VERSION ""

NS_ :

BS_:

BU_: VMCU TECU OBDScanT2 IC3 EMS ECUspare2 ECUspare1 DACU CIOM BBM

BO_ 1443 IC3_BB2_06S: 21 IC3
 SG_ SaveTrlrName_rqst_Request : 160|2@1+ (1,0) [0|0] ""  VMCU
 SG_ SaveTrlrName_rqst_sg_UB : 165|1@1+ (1,0) [0|0] ""  VMCU
 SG_ SaveTrlrName_rqst_NewName : 0|160@1+ (1,0) [0|0] ""  VMCU
 SG_ SaveTrlrName_rqst_Position : 162|3@1+ (1,0) [0|0] ""  VMCU

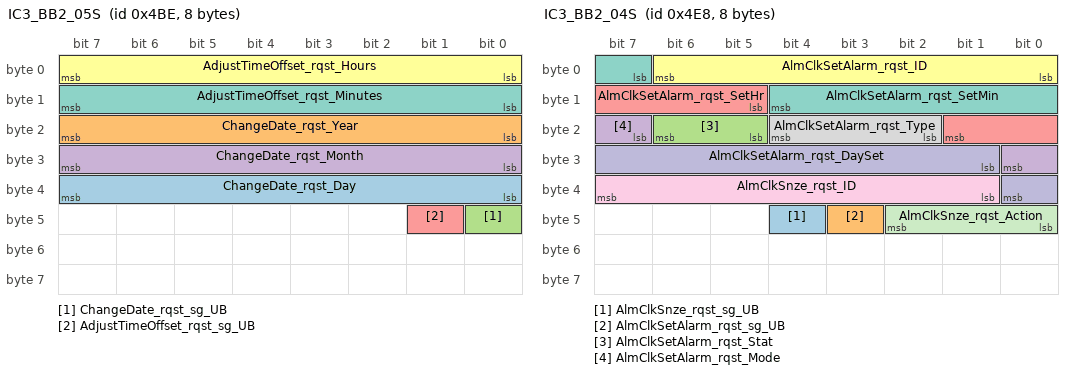
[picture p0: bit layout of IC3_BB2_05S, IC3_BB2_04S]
BO_ 1214 IC3_BB2_05S: 8 IC3
 SG_ ChangeDate_rqst_Day : 32|8@1+ (1,0) [0|255] "Days"  VMCU
 SG_ ChangeDate_rqst_Year : 16|8@1+ (1,1985) [1985|2240] "Years"  VMCU
 SG_ ChangeDate_rqst_sg_UB : 40|1@1+ (1,0) [0|0] ""  VMCU
 SG_ ChangeDate_rqst_Month : 24|8@1+ (1,0) [0|255] "Months"  VMCU
 SG_ AdjustTimeOffset_rqst_sg_UB : 41|1@1+ (1,0) [0|0] ""  VMCU
 SG_ AdjustTimeOffset_rqst_Hours : 0|8@1+ (1,0) [0|255] "h"  VMCU
 SG_ AdjustTimeOffset_rqst_Minutes : 8|8@1+ (1,0) [0|255] "min"  VMCU

BO_ 1256 IC3_BB2_04S: 8 IC3
 SG_ AlmClkSnze_rqst_sg_UB : 44|1@1+ (1,0) [0|0] ""  VMCU
 SG_ AlmClkSetAlarm_rqst_sg_UB : 43|1@1+ (1,0) [0|0] ""  VMCU
 SG_ AlmClkSetAlarm_rqst_Stat : 21|2@1+ (1,0) [0|0] ""  VMCU
 SG_ AlmClkSetAlarm_rqst_Mode : 23|2@1+ (1,0) [0|0] ""  VMCU
 SG_ AlmClkSetAlarm_rqst_SetHr : 13|5@1+ (1,0) [0|31] "h"  VMCU
 SG_ AlmClkSetAlarm_rqst_ID : 0|7@1+ (1,0) [0|0] ""  VMCU
 SG_ AlmClkSetAlarm_rqst_SetMin : 7|6@1+ (1,0) [0|63] "min"  VMCU
 SG_ AlmClkSetAlarm_rqst_Type : 18|3@1+ (1,0) [0|0] ""  VMCU
 SG_ AlmClkSnze_rqst_ID : 33|7@1+ (1,0) [0|0] ""  VMCU
 SG_ AlmClkSetAlarm_rqst_DaySet : 25|8@1+ (1,0) [0|255] ""  VMCU
 SG_ AlmClkSnze_rqst_Action : 40|3@1+ (1,0) [0|0] ""  VMCU

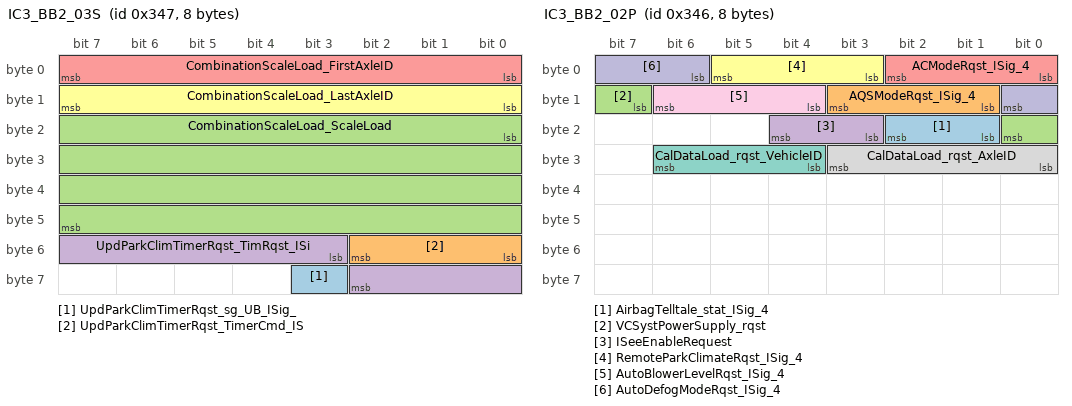
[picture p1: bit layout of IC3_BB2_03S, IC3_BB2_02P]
BO_ 839 IC3_BB2_03S: 8 IC3
 SG_ UpdParkClimTimerRqst_sg_UB_ISig_ : 59|1@1+ (1,0) [0|0] ""  CIOM
 SG_ UpdParkClimTimerRqst_TimerCmd_IS : 48|3@1+ (1,0) [0|0] ""  CIOM
 SG_ CombinationScaleLoad_ScaleLoad : 16|32@1+ (1,0) [0|4294967295] "kg"  VMCU
 SG_ UpdParkClimTimerRqst_TimRqst_ISi : 51|8@1+ (1,0) [0|0] ""  CIOM
 SG_ CombinationScaleLoad_FirstAxleID : 0|8@1+ (1,0) [0|255] "NotApplicable"  VMCU
 SG_ CombinationScaleLoad_LastAxleID : 8|8@1+ (1,0) [0|255] "NotApplicable"  VMCU

BO_ 838 IC3_BB2_02P: 8 IC3
 SG_ AirbagTelltale_stat_ISig_4 : 17|2@1+ (1,0) [0|0] ""  CIOM
 SG_ AQSModeRqst_ISig_4 : 9|3@1+ (1,0) [0|0] ""  CIOM
 SG_ VCSystPowerSupply_rqst : 15|2@1+ (1,0) [0|0] ""  VMCU
 SG_ ISeeEnableRequest : 19|2@1+ (1,0) [0|0] ""  TECU
 SG_ ACModeRqst_ISig_4 : 0|3@1+ (1,0) [0|0] ""  CIOM
 SG_ RemoteParkClimateRqst_ISig_4 : 3|3@1+ (1,0) [0|0] ""  CIOM
 SG_ CalDataLoad_rqst_VehicleID : 28|3@1+ (1,0) [0|0] ""  VMCU
 SG_ CalDataLoad_rqst_AxleID : 24|4@1+ (1,0) [0|0] ""  VMCU
 SG_ AutoBlowerLevelRqst_ISig_4 : 12|3@1+ (1,0) [0|0] ""  CIOM
 SG_ AutoDefogModeRqst_ISig_4 : 6|3@1+ (1,0) [0|0] ""  CIOM

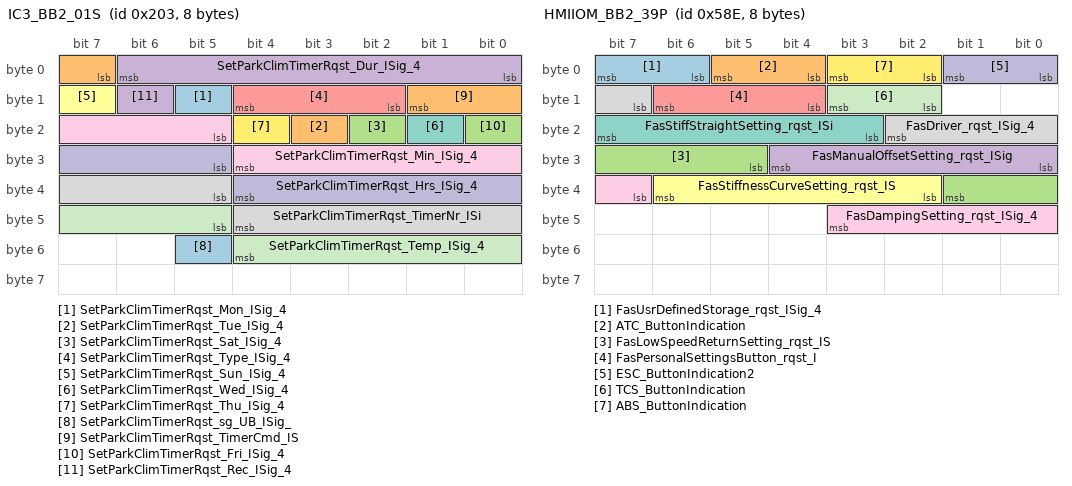
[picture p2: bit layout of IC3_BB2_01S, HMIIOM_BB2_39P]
BO_ 515 IC3_BB2_01S: 8 IC3
 SG_ SetParkClimTimerRqst_Mon_ISig_4 : 13|1@1+ (1,0) [0|0] ""  CIOM
 SG_ SetParkClimTimerRqst_Tue_ISig_4 : 19|1@1+ (1,0) [0|0] ""  CIOM
 SG_ SetParkClimTimerRqst_Sat_ISig_4 : 18|1@1+ (1,0) [0|0] ""  CIOM
 SG_ SetParkClimTimerRqst_Dur_ISig_4 : 0|7@1+ (1,0) [0|127] "min"  CIOM
 SG_ SetParkClimTimerRqst_Type_ISig_4 : 10|3@1+ (1,0) [0|0] ""  CIOM
 SG_ SetParkClimTimerRqst_Sun_ISig_4 : 15|1@1+ (1,0) [0|0] ""  CIOM
 SG_ SetParkClimTimerRqst_Wed_ISig_4 : 17|1@1+ (1,0) [0|0] ""  CIOM
 SG_ SetParkClimTimerRqst_TimerNr_ISi : 37|8@1+ (1,0) [0|0] ""  CIOM
 SG_ SetParkClimTimerRqst_Min_ISig_4 : 21|8@1+ (1,0) [0|255] "min"  CIOM
 SG_ SetParkClimTimerRqst_Hrs_ISig_4 : 29|8@1+ (1,0) [0|255] "h"  CIOM
 SG_ SetParkClimTimerRqst_Temp_ISig_4 : 45|8@1+ (0.5,0) [0|127.5] "DegreeC"  CIOM
 SG_ SetParkClimTimerRqst_Thu_ISig_4 : 20|1@1+ (1,0) [0|0] ""  CIOM
 SG_ SetParkClimTimerRqst_sg_UB_ISig_ : 53|1@1+ (1,0) [0|0] ""  CIOM
 SG_ SetParkClimTimerRqst_TimerCmd_IS : 7|3@1+ (1,0) [0|0] ""  CIOM
 SG_ SetParkClimTimerRqst_Fri_ISig_4 : 16|1@1+ (1,0) [0|0] ""  CIOM
 SG_ SetParkClimTimerRqst_Rec_ISig_4 : 14|1@1+ (1,0) [0|0] ""  CIOM

BO_ 1477 HMIIOM_BB2_S28_FCM: 8 TECU
 SG_ HMIIOM_BB2_S28_FCS : 0|64@1+ (1,0) [0|0] ""  IC3

BO_ 1422 HMIIOM_BB2_39P: 8 IC3
 SG_ FasUsrDefinedStorage_rqst_ISig_4 : 6|2@1+ (1,0) [0|0] ""  VMCU
 SG_ ATC_ButtonIndication : 4|2@1+ (1,0) [0|0] ""  CIOM
 SG_ FasLowSpeedReturnSetting_rqst_IS : 29|5@1+ (1,-10) [-10|21] ""  VMCU
 SG_ FasManualOffsetSetting_rqst_ISig : 24|5@1+ (1,-10) [-10|21] ""  VMCU
 SG_ FasPersonalSettingsButton_rqst_I : 12|3@1+ (1,0) [0|0] ""  VMCU
 SG_ FasStiffnessCurveSetting_rqst_IS : 34|5@1+ (1,-10) [-10|21] ""  VMCU
 SG_ FasStiffStraightSetting_rqst_ISi : 19|5@1+ (1,-10) [-10|21] ""  VMCU
 SG_ FasDriver_rqst_ISig_4 : 15|4@1+ (1,0) [0|0] ""  VMCU
 SG_ FasDampingSetting_rqst_ISig_4 : 39|5@1+ (1,-10) [-10|21] ""  VMCU
 SG_ ESC_ButtonIndication2 : 0|2@1+ (1,0) [0|0] ""  CIOM
 SG_ TCS_ButtonIndication : 10|2@1+ (1,0) [0|0] ""  CIOM
 SG_ ABS_ButtonIndication : 2|2@1+ (1,0) [0|0] ""  CIOM

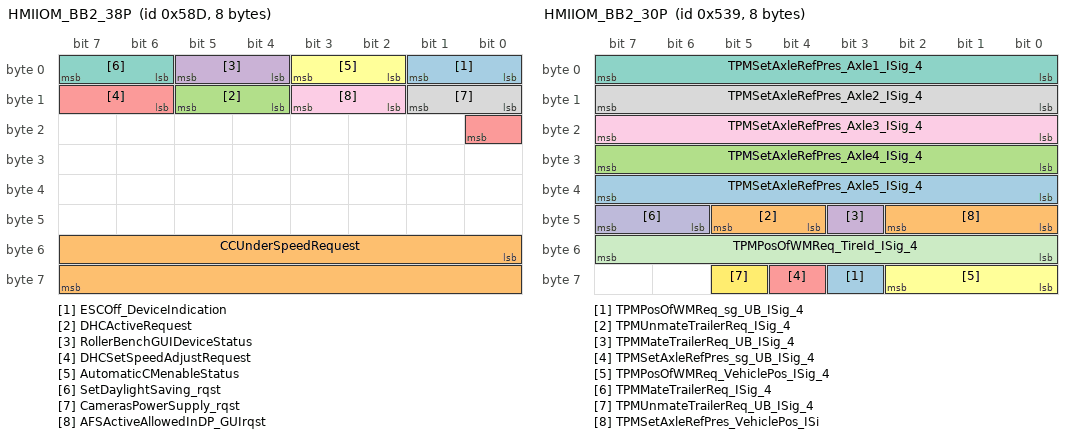
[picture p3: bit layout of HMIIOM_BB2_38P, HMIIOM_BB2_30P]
BO_ 1421 HMIIOM_BB2_38P: 8 IC3
 SG_ ESCOff_DeviceIndication : 0|2@1+ (1,0) [0|0] ""  CIOM
 SG_ CCUnderSpeedRequest : 48|16@1+ (0.00390625,0) [0|255.99609375] "Km_per_h"  VMCU
 SG_ DHCActiveRequest : 12|2@1+ (1,0) [0|0] ""  VMCU
 SG_ RollerBenchGUIDeviceStatus : 4|2@1+ (1,0) [0|0] ""  CIOM
 SG_ DHCSetSpeedAdjustRequest : 14|3@1+ (1,0) [0|0] ""  VMCU
 SG_ AutomaticCMenableStatus : 2|2@1+ (1,0) [0|0] ""  DACU
 SG_ SetDaylightSaving_rqst : 6|2@1+ (1,0) [0|0] ""  VMCU
 SG_ CamerasPowerSupply_rqst : 8|2@1+ (1,0) [0|0] ""  VMCU
 SG_ AFSActiveAllowedInDP_GUIrqst : 10|2@1+ (1,0) [0|0] ""  VMCU

BO_ 518 HMIIOM_BB2_37S: 8 IC3
 SG_ AdasisMapData_ISig_4 : 7|64@0+ (1,0) [0|0] ""  TECU

BO_ 1397 HMIIOM_BB2_36S_FCM: 8 CIOM
 SG_ HMIIOM_BB2_36S_FCS : 0|64@1+ (1,0) [0|0] ""  IC3

BO_ 1396 HMIIOM_BB2_36S: 36 IC3
 SG_ SEM_DisplayText_stat_ISig_4 : 0|288@1+ (1,0) [0|0] ""  CIOM

BO_ 952 HMIIOM_BB2_35S_FCM: 8 CIOM
 SG_ HMIIOM_BB2_35S_FCS : 0|64@1+ (1,0) [0|0] ""  IC3

BO_ 949 HMIIOM_BB2_35S: 98 IC3
 SG_ MediaSourcesListRsp_sg_UB_ISig_4 : 782|1@1+ (1,0) [0|0] ""  CIOM
 SG_ MediaSourcesListRsp_SrcAttrib_IS : 392|384@1+ (1,0) [0|0] ""  CIOM
 SG_ MediaSourcesListRsp_SInfo_ISig_4 : 780|2@1+ (1,0) [0|0] ""  CIOM
 SG_ MediaSourcesListRsp_Name_ISig_4 : 8|384@1+ (1,0) [0|0] ""  CIOM
 SG_ MediaSourcesListRsp_PCI_ISig_4 : 0|8@1+ (1,0) [0|255] ""  CIOM
 SG_ MediaSourcesListRsp_ItemID_ISig_ : 776|4@1+ (1,0) [0|0] ""  CIOM

BO_ 967 HMIIOM_BB2_34S: 8 IC3
 SG_ MediaSourcesListNPRsp_ISig_4 : 0|8@1+ (1,0) [0|255] ""  CIOM
 SG_ MediaSourcesListNPRsp_UB_ISig_4 : 8|1@1+ (1,0) [0|0] ""  CIOM

BO_ 822 HMIIOM_BB2_33P: 8 IC3
 SG_ SEMMediaSourceAvail_Source04_ISi : 4|1@1+ (1,0) [0|0] ""  CIOM
 SG_ SEMMediaSourceAvail_Source10_ISi : 10|1@1+ (1,0) [0|0] ""  CIOM
 SG_ SEMMediaSourceAvail_SInfo_ISig_4 : 14|2@1+ (1,0) [0|0] ""  CIOM
 SG_ SEM_PresetIndicationCmd_ISig_4 : 25|6@1+ (1,0) [0|63] "Enumeration"  CIOM
 SG_ SEMMediaSourceAvail_Source09_ISi : 9|1@1+ (1,0) [0|0] ""  CIOM
 SG_ SEMMediaSourceAvail_Source12_ISi : 12|1@1+ (1,0) [0|0] ""  CIOM
 SG_ SEMMediaSourceAvail_Source07_ISi : 7|1@1+ (1,0) [0|0] ""  CIOM
 SG_ SEMMediaSourceAvail_Source03_ISi : 3|1@1+ (1,0) [0|0] ""  CIOM
 SG_ SEMMediaSourceAvail_Source11_ISi : 11|1@1+ (1,0) [0|0] ""  CIOM
 SG_ SEM_AudioVolValIndCmd_ISig_4 : 19|6@1+ (1,0) [0|63] "Step"  CIOM
 SG_ SEMMediaSourceAvail_Source02_ISi : 2|1@1+ (1,0) [0|0] ""  CIOM
 SG_ AudioSourceStat_ISig_4 : 31|4@1+ (1,0) [0|0] ""  CIOM
 SG_ SEMMediaSourceAvail_Source06_ISi : 6|1@1+ (1,0) [0|0] ""  CIOM
 SG_ SEMMediaSourceAvail_Source00_ISi : 0|1@1+ (1,0) [0|0] ""  CIOM
 SG_ SEMMediaSourceAvail_Source01_ISi : 1|1@1+ (1,0) [0|0] ""  CIOM
 SG_ SEMMediaSourceAvail_Source08_ISi : 8|1@1+ (1,0) [0|0] ""  CIOM
 SG_ SEM_AudioMuteStat_ISig_4 : 16|3@1+ (1,0) [0|0] ""  CIOM
 SG_ SEMMediaSourceAvail_Source13_ISi : 13|1@1+ (1,0) [0|0] ""  CIOM
 SG_ SEMMediaSourceAvail_Source05_ISi : 5|1@1+ (1,0) [0|0] ""  CIOM

BO_ 1337 HMIIOM_BB2_30P: 8 IC3
 SG_ TPMPosOfWMReq_sg_UB_ISig_4 : 59|1@1+ (1,0) [0|0] ""  VMCU
 SG_ TPMUnmateTrailerReq_ISig_4 : 44|2@1+ (1,0) [0|0] ""  VMCU
 SG_ TPMSetAxleRefPres_Axle4_ISig_4 : 24|8@1+ (10,0) [0|2550] "kPa"  VMCU
 SG_ TPMMateTrailerReq_UB_ISig_4 : 43|1@1+ (1,0) [0|0] ""  VMCU
 SG_ TPMSetAxleRefPres_sg_UB_ISig_4 : 60|1@1+ (1,0) [0|0] ""  VMCU
 SG_ TPMPosOfWMReq_VehiclePos_ISig_4 : 56|3@1+ (1,0) [0|0] ""  VMCU
 SG_ TPMSetAxleRefPres_Axle1_ISig_4 : 0|8@1+ (10,0) [0|2550] "kPa"  VMCU
 SG_ TPMSetAxleRefPres_Axle2_ISig_4 : 8|8@1+ (10,0) [0|2550] "kPa"  VMCU
 SG_ TPMSetAxleRefPres_Axle3_ISig_4 : 16|8@1+ (10,0) [0|2550] "kPa"  VMCU
 SG_ TPMMateTrailerReq_ISig_4 : 46|2@1+ (1,0) [0|0] ""  VMCU
 SG_ TPMPosOfWMReq_TireId_ISig_4 : 48|8@1+ (1,0) [0|255] "NotApplicable"  VMCU
 SG_ TPMUnmateTrailerReq_UB_ISig_4 : 61|1@1+ (1,0) [0|0] ""  VMCU
 SG_ TPMSetAxleRefPres_Axle5_ISig_4 : 32|8@1+ (10,0) [0|2550] "kPa"  VMCU
 SG_ TPMSetAxleRefPres_VehiclePos_ISi : 40|3@1+ (1,0) [0|0] ""  VMCU

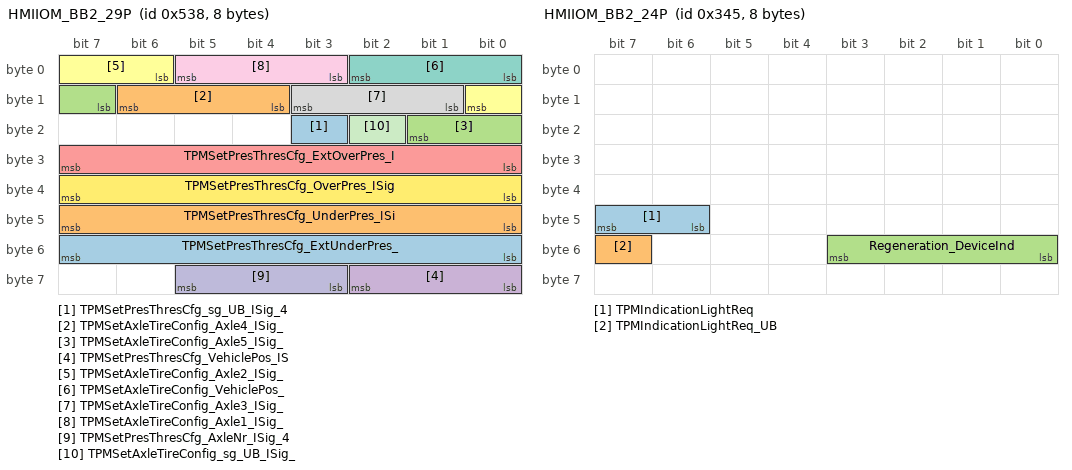
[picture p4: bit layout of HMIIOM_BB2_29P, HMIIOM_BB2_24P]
BO_ 1336 HMIIOM_BB2_29P: 8 IC3
 SG_ TPMSetPresThresCfg_sg_UB_ISig_4 : 19|1@1+ (1,0) [0|0] ""  VMCU
 SG_ TPMSetAxleTireConfig_Axle4_ISig_ : 12|3@1+ (1,0) [0|0] ""  VMCU
 SG_ TPMSetAxleTireConfig_Axle5_ISig_ : 15|3@1+ (1,0) [0|0] ""  VMCU
 SG_ TPMSetPresThresCfg_VehiclePos_IS : 56|3@1+ (1,0) [0|0] ""  VMCU
 SG_ TPMSetPresThresCfg_ExtOverPres_I : 24|8@1+ (1,-125) [-125|130] "Percent"  VMCU
 SG_ TPMSetAxleTireConfig_Axle2_ISig_ : 6|3@1+ (1,0) [0|0] ""  VMCU
 SG_ TPMSetAxleTireConfig_VehiclePos_ : 0|3@1+ (1,0) [0|0] ""  VMCU
 SG_ TPMSetAxleTireConfig_Axle3_ISig_ : 9|3@1+ (1,0) [0|0] ""  VMCU
 SG_ TPMSetAxleTireConfig_Axle1_ISig_ : 3|3@1+ (1,0) [0|0] ""  VMCU
 SG_ TPMSetPresThresCfg_AxleNr_ISig_4 : 59|3@1+ (1,0) [0|0] ""  VMCU
 SG_ TPMSetAxleTireConfig_sg_UB_ISig_ : 18|1@1+ (1,0) [0|0] ""  VMCU
 SG_ TPMSetPresThresCfg_OverPres_ISig : 32|8@1+ (1,-125) [-125|130] "Percent"  VMCU
 SG_ TPMSetPresThresCfg_ExtUnderPres_ : 48|8@1+ (1,-125) [-125|130] "Percent"  VMCU
 SG_ TPMSetPresThresCfg_UnderPres_ISi : 40|8@1+ (1,-125) [-125|130] "Percent"  VMCU

BO_ 1476 HMIIOM_BB2_28S: 284 IC3
 SG_ HillDataPkgTGW_ISig_4 : 0|2272@1+ (1,0) [0|0] ""  TECU

BO_ 1394 HMIIOM_BB2_27S_FCM: 8 CIOM
 SG_ HMIIOM_BB2_27S_FCS : 0|64@1+ (1,0) [0|0] ""  IC3

BO_ 837 HMIIOM_BB2_24P: 8 IC3
 SG_ TPMIndicationLightReq : 46|2@1+ (1,0) [0|0] ""  VMCU
 SG_ TPMIndicationLightReq_UB : 55|1@1+ (1,0) [0|0] ""  VMCU
 SG_ Regeneration_DeviceInd : 48|4@1+ (1,0) [0|0] ""  CIOM

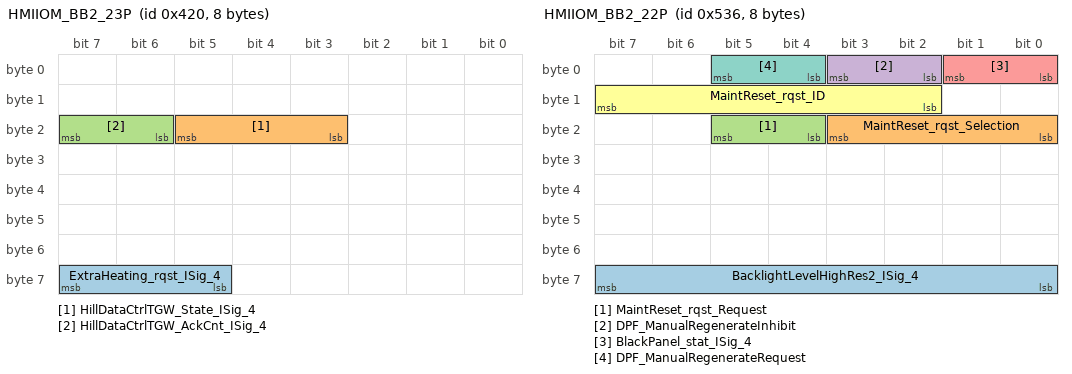
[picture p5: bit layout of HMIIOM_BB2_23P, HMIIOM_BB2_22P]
BO_ 1056 HMIIOM_BB2_23P: 8 IC3
 SG_ ExtraHeating_rqst_ISig_4 : 61|3@1+ (1,0) [0|0] ""  CIOM
 SG_ HillDataCtrlTGW_State_ISig_4 : 19|3@1+ (1,0) [0|0] ""  TECU
 SG_ HillDataCtrlTGW_AckCnt_ISig_4 : 22|2@1+ (1,0) [0|3] ""  TECU

BO_ 1334 HMIIOM_BB2_22P: 8 IC3
 SG_ BacklightLevelHighRes2_ISig_4 : 56|8@1+ (0.4,0) [0|102] "Percent"  CIOM,BBM,VMCU
 SG_ MaintReset_rqst_Selection : 16|4@1+ (1,0) [0|15] "Enumeration"  VMCU
 SG_ MaintReset_rqst_Request : 20|2@1+ (1,0) [0|0] ""  VMCU
 SG_ DPF_ManualRegenerateInhibit : 2|2@1+ (1,0) [0|0] ""  EMS
 SG_ BlackPanel_stat_ISig_4 : 0|2@1+ (1,0) [0|0] ""  VMCU
 SG_ MaintReset_rqst_ID : 10|6@1+ (1,0) [0|63] "Enumeration"  VMCU
 SG_ DPF_ManualRegenerateRequest : 4|2@1+ (1,0) [0|0] ""  EMS

BO_ 1344 HMIIOM_BB2_20S_FCM: 8 CIOM
 SG_ HMIIOM_BB2_20S_FCS : 0|64@1+ (1,0) [0|0] ""  IC3

BO_ 1343 HMIIOM_BB2_20S: 11 IC3
 SG_ ECU3VIN_stat : 0|88@1+ (1,0) [0|0] ""  CIOM

BO_ 1379 HMIIOM_BB2_19P_VMCU_FCM: 8 VMCU
 SG_ HMIIOM_BB2_19P_FCS_563 : 0|64@1+ (1,0) [0|0] ""  IC3

BO_ 1377 HMIIOM_BB2_19P_VMCU: 21 IC3
 SG_ GPSData_Longitude_ISig_4_561 : 0|32@1+ (1E-007,-210) [-210|219.4967295] "deg"  VMCU
 SG_ GPSData_sg_UB_ISig_4_561 : 163|1@1+ (1,0) [0|1] ""  VMCU
 SG_ GPSData_Direction_ISig_4_561 : 96|16@1+ (0.0078125,0) [0|511.9921875] "deg"  VMCU
 SG_ GPSData_Latitude_ISig_4_561 : 32|32@1+ (1E-007,-210) [-210|219.4967295] "deg"  VMCU
 SG_ GPSData_Altitude_ISig_4_561 : 144|16@1+ (0.125,-2500) [-2500|5691.875] "m"  VMCU
 SG_ GPSData_HDOP_ISig_4_561 : 112|16@1+ (0.01,0) [0|655.35] ""  VMCU
 SG_ GPSData_Time_ISig_4_561 : 64|32@1+ (1,0) [0|4294967295] "s"  VMCU
 SG_ GPSData_VehSpeed_ISig_4_561 : 128|16@1+ (0.00390625,0) [0|255.99609375] "Km_per_h"  VMCU
 SG_ GPSData_AntennaStat_ISig_4_561 : 160|3@1+ (1,0) [0|0] ""  VMCU

BO_ 1376 HMIIOM_BB2_19P_TECU_FCM: 8 TECU
 SG_ HMIIOM_BB2_19P_FCS_560 : 0|64@1+ (1,0) [0|0] ""  IC3

BO_ 1375 HMIIOM_BB2_19P_TECU: 21 IC3
 SG_ GPSData_HDOP_ISig_4_55f : 112|16@1+ (0.01,0) [0|655.35] ""  TECU
 SG_ GPSData_VehSpeed_ISig_4_55f : 128|16@1+ (0.00390625,0) [0|255.99609375] "Km_per_h"  TECU
 SG_ GPSData_Direction_ISig_4_55f : 96|16@1+ (0.0078125,0) [0|511.9921875] "deg"  TECU
 SG_ GPSData_Longitude_ISig_4_55f : 0|32@1+ (1E-007,-210) [-210|219.4967295] "deg"  TECU
 SG_ GPSData_sg_UB_ISig_4_55f : 163|1@1+ (1,0) [0|1] ""  TECU
 SG_ GPSData_Time_ISig_4_55f : 64|32@1+ (1,0) [0|4294967295] "s"  TECU
 SG_ GPSData_Latitude_ISig_4_55f : 32|32@1+ (1E-007,-210) [-210|219.4967295] "deg"  TECU
 SG_ GPSData_AntennaStat_ISig_4_55f : 160|3@1+ (1,0) [0|0] ""  TECU
 SG_ GPSData_Altitude_ISig_4_55f : 144|16@1+ (0.125,-2500) [-2500|5691.875] "m"  TECU

BO_ 1382 HMIIOM_BB2_19P_DACU_FCM: 8 DACU
 SG_ HMIIOM_BB2_19P_FCS_566 : 0|64@1+ (1,0) [0|0] ""  IC3

BO_ 1381 HMIIOM_BB2_19P_DACU: 21 IC3
 SG_ GPSData_HDOP_ISig_4_565 : 112|16@1+ (0.01,0) [0|655.35] ""  DACU
 SG_ GPSData_VehSpeed_ISig_4_565 : 128|16@1+ (0.00390625,0) [0|255.99609375] "Km_per_h"  DACU
 SG_ GPSData_sg_UB_ISig_4_565 : 163|1@1+ (1,0) [0|1] ""  DACU
 SG_ GPSData_AntennaStat_ISig_4_565 : 160|3@1+ (1,0) [0|0] ""  DACU
 SG_ GPSData_Latitude_ISig_4_565 : 32|32@1+ (1E-007,-210) [-210|219.4967295] "deg"  DACU
 SG_ GPSData_Time_ISig_4_565 : 64|32@1+ (1,0) [0|4294967295] "s"  DACU
 SG_ GPSData_Direction_ISig_4_565 : 96|16@1+ (0.0078125,0) [0|511.9921875] "deg"  DACU
 SG_ GPSData_Longitude_ISig_4_565 : 0|32@1+ (1E-007,-210) [-210|219.4967295] "deg"  DACU
 SG_ GPSData_Altitude_ISig_4_565 : 144|16@1+ (0.125,-2500) [-2500|5691.875] "m"  DACU

BO_ 1387 HMIIOM_BB2_19P_CIOM_FCM: 8 CIOM
 SG_ HMIIOM_BB2_19P_FCS_56b : 0|64@1+ (1,0) [0|0] ""  IC3

BO_ 1386 HMIIOM_BB2_19P_CIOM: 21 IC3
 SG_ GPSData_HDOP_ISig_4_56a : 112|16@1+ (0.01,0) [0|655.35] ""  CIOM
 SG_ GPSData_Latitude_ISig_4_56a : 32|32@1+ (1E-007,-210) [-210|219.4967295] "deg"  CIOM
 SG_ GPSData_Time_ISig_4_56a : 64|32@1+ (1,0) [0|4294967295] "s"  CIOM
 SG_ GPSData_Direction_ISig_4_56a : 96|16@1+ (0.0078125,0) [0|511.9921875] "deg"  CIOM
 SG_ GPSData_sg_UB_ISig_4_56a : 163|1@1+ (1,0) [0|1] ""  CIOM
 SG_ GPSData_AntennaStat_ISig_4_56a : 160|3@1+ (1,0) [0|0] ""  CIOM
 SG_ GPSData_Longitude_ISig_4_56a : 0|32@1+ (1E-007,-210) [-210|219.4967295] "deg"  CIOM
 SG_ GPSData_VehSpeed_ISig_4_56a : 128|16@1+ (0.00390625,0) [0|255.99609375] "Km_per_h"  CIOM
 SG_ GPSData_Altitude_ISig_4_56a : 144|16@1+ (0.125,-2500) [-2500|5691.875] "m"  CIOM

BO_ 1385 HMIIOM_BB2_19P_BBM_FCM: 8 BBM
 SG_ HMIIOM_BB2_19P_FCS_569 : 0|64@1+ (1,0) [0|0] ""  IC3

BO_ 1384 HMIIOM_BB2_19P_BBM: 21 IC3
 SG_ GPSData_Time_ISig_4_568 : 64|32@1+ (1,0) [0|4294967295] "s"  BBM
 SG_ GPSData_HDOP_ISig_4_568 : 112|16@1+ (0.01,0) [0|655.35] ""  BBM
 SG_ GPSData_Direction_ISig_4_568 : 96|16@1+ (0.0078125,0) [0|511.9921875] "deg"  BBM
 SG_ GPSData_Longitude_ISig_4_568 : 0|32@1+ (1E-007,-210) [-210|219.4967295] "deg"  BBM
 SG_ GPSData_sg_UB_ISig_4_568 : 163|1@1+ (1,0) [0|1] ""  BBM
 SG_ GPSData_VehSpeed_ISig_4_568 : 128|16@1+ (0.00390625,0) [0|255.99609375] "Km_per_h"  BBM
 SG_ GPSData_Altitude_ISig_4_568 : 144|16@1+ (0.125,-2500) [-2500|5691.875] "m"  BBM
 SG_ GPSData_Latitude_ISig_4_568 : 32|32@1+ (1E-007,-210) [-210|219.4967295] "deg"  BBM
 SG_ GPSData_AntennaStat_ISig_4_568 : 160|3@1+ (1,0) [0|0] ""  BBM

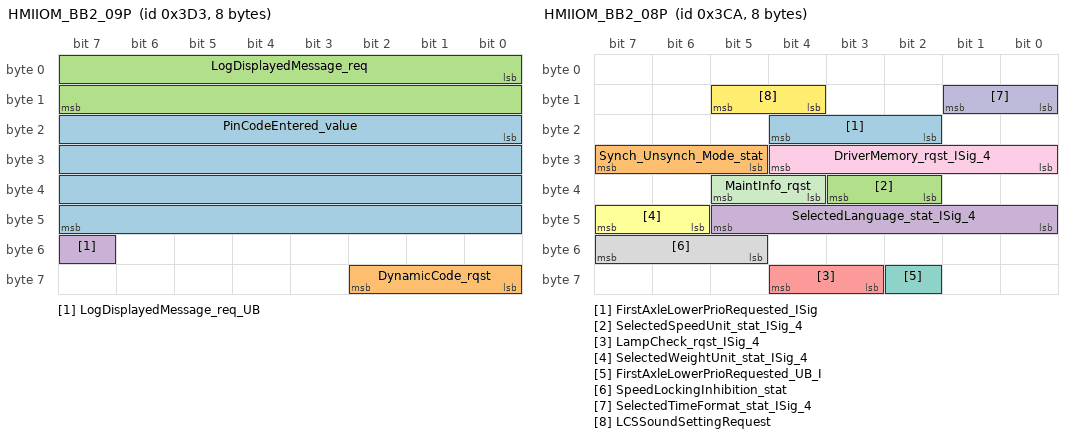
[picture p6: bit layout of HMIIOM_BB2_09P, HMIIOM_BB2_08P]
BO_ 979 HMIIOM_BB2_09P: 8 IC3
 SG_ PinCodeEntered_value : 16|32@1+ (1,0) [0|4294967295] "NotApplicable"  CIOM
 SG_ DynamicCode_rqst : 56|3@1+ (1,0) [0|0] ""  CIOM
 SG_ LogDisplayedMessage_req : 0|16@1+ (1,0) [0|65535] "NotApplicable"  VMCU
 SG_ LogDisplayedMessage_req_UB : 55|1@1+ (1,0) [0|0] ""  VMCU

BO_ 970 HMIIOM_BB2_08P: 8 IC3
 SG_ FirstAxleLowerPrioRequested_ISig : 18|3@1+ (1,0) [0|0] ""  VMCU
 SG_ Synch_Unsynch_Mode_stat : 29|3@1+ (1,0) [0|0] ""  CIOM
 SG_ SelectedSpeedUnit_stat_ISig_4 : 34|2@1+ (1,0) [0|0] ""  VMCU
 SG_ SelectedLanguage_stat_ISig_4 : 40|6@1+ (1,0) [0|0] ""  BBM,CIOM
 SG_ LampCheck_rqst_ISig_4 : 59|2@1+ (1,0) [0|0] ""  VMCU
 SG_ SelectedWeightUnit_stat_ISig_4 : 46|2@1+ (1,0) [0|0] ""  CIOM
 SG_ FirstAxleLowerPrioRequested_UB_I : 58|1@1+ (1,0) [0|0] ""  VMCU
 SG_ SpeedLockingInhibition_stat : 53|3@1+ (1,0) [0|0] ""  CIOM
 SG_ DriverMemory_rqst_ISig_4 : 24|5@1+ (1,0) [0|0] ""  CIOM,VMCU
 SG_ SelectedTimeFormat_stat_ISig_4 : 8|2@1+ (1,0) [0|0] ""  CIOM
 SG_ MaintInfo_rqst : 36|2@1+ (1,0) [0|0] ""  VMCU
 SG_ LCSSoundSettingRequest : 12|2@1+ (1,0) [0|0] ""  DACU

BO_ 851 HMIIOM_BB2_07P: 8 IC3
 SG_ BunkBacklightCmd_ISig_4 : 16|5@1+ (1,0) [0|0] ""  CIOM

BO_ 1270 HMIIOM_BB2_05P: 8 IC3
 SG_ CabLightIntensity_stat_ISig_4 : 0|8@1+ (0.4,0) [0|102] "Percent"  BBM,DACU

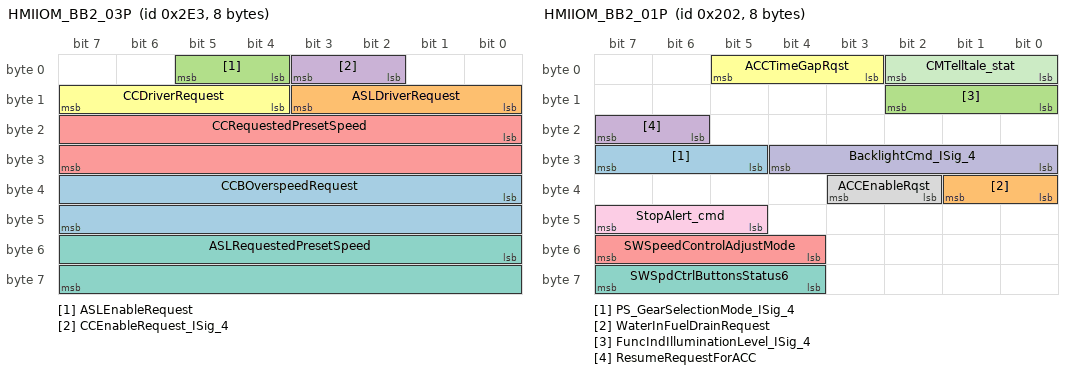
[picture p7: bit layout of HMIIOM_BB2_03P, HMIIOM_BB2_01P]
BO_ 739 HMIIOM_BB2_03P: 8 IC3
 SG_ CCBOverspeedRequest : 32|16@1+ (0.00390625,0) [0|255.99609375] "Km_per_h"  VMCU
 SG_ ASLDriverRequest : 8|4@1+ (1,0) [0|0] ""  VMCU
 SG_ ASLEnableRequest : 4|2@1+ (1,0) [0|0] ""  VMCU
 SG_ CCEnableRequest_ISig_4 : 2|2@1+ (1,0) [0|0] ""  CIOM,VMCU,BBM
 SG_ CCRequestedPresetSpeed : 16|16@1+ (0.00390625,0) [0|255.99609375] "Km_per_h"  VMCU
 SG_ CCDriverRequest : 12|4@1+ (1,0) [0|0] ""  VMCU,BBM
 SG_ ASLRequestedPresetSpeed : 48|16@1+ (0.00390625,0) [0|255.99609375] "Km_per_h"  VMCU

BO_ 390 HMIIOM_BB2_02P: 8 IC3
 SG_ EcoRollEnableRequest_ISig_4 : 6|2@1+ (1,0) [0|0] ""  TECU
 SG_ SelectedEcoCruiseLevel_ISig_4 : 40|3@1+ (1,0) [0|0] ""  EMS,DACU,TECU,VMCU

BO_ 514 HMIIOM_BB2_01P: 8 IC3
 SG_ PS_GearSelectionMode_ISig_4 : 29|3@1+ (1,0) [0|0] ""  VMCU
 SG_ WaterInFuelDrainRequest : 32|2@1+ (1,0) [0|0] ""  EMS
 SG_ FuncIndIlluminationLevel_ISig_4 : 8|3@1+ (1,0) [0|0] ""  VMCU,CIOM
 SG_ ResumeRequestForACC : 22|2@1+ (1,0) [0|0] ""  DACU
 SG_ SWSpeedControlAdjustMode : 52|4@1+ (1,0) [0|0] ""  VMCU,CIOM
 SG_ ACCTimeGapRqst : 3|3@1+ (1,0) [0|0] ""  DACU
 SG_ SWSpdCtrlButtonsStatus6 : 60|4@1+ (1,0) [0|0] ""  CIOM
 SG_ ACCEnableRqst : 34|2@1+ (1,0) [0|0] ""  VMCU,DACU,CIOM
 SG_ StopAlert_cmd : 45|3@1+ (1,0) [0|0] ""  VMCU
 SG_ BacklightCmd_ISig_4 : 24|5@1+ (1,0) [0|0] ""  CIOM,VMCU
 SG_ CMTelltale_stat : 0|3@1+ (1,0) [0|0] ""  DACU

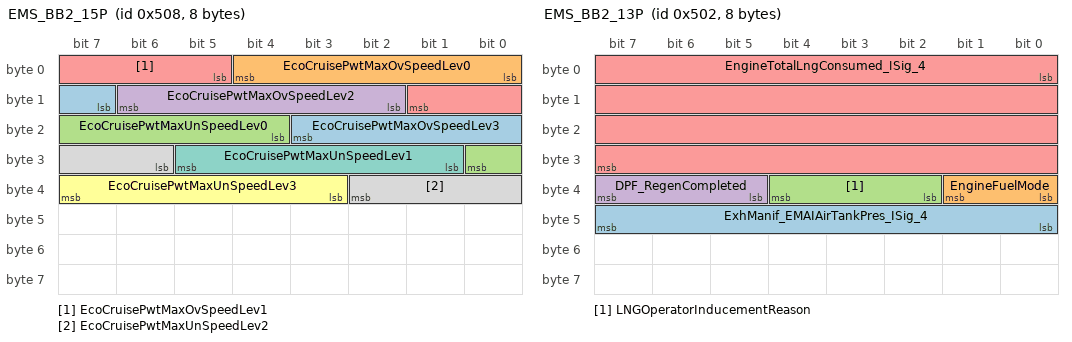
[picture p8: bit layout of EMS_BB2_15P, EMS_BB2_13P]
BO_ 1288 EMS_BB2_15P: 8 EMS
 SG_ EcoCruisePwtMaxOvSpeedLev3 : 15|5@1+ (1,0) [0|31] "Km_per_h"  VMCU
 SG_ EcoCruisePwtMaxOvSpeedLev0 : 0|5@1+ (1,0) [0|31] "Km_per_h"  VMCU
 SG_ EcoCruisePwtMaxUnSpeedLev0 : 20|5@1+ (1,0) [0|31] "Km_per_h"  VMCU
 SG_ EcoCruisePwtMaxOvSpeedLev2 : 10|5@1+ (1,0) [0|31] "Km_per_h"  VMCU
 SG_ EcoCruisePwtMaxOvSpeedLev1 : 5|5@1+ (1,0) [0|31] "Km_per_h"  VMCU
 SG_ EcoCruisePwtMaxUnSpeedLev3 : 35|5@1+ (1,0) [0|31] "Km_per_h"  VMCU
 SG_ EcoCruisePwtMaxUnSpeedLev1 : 25|5@1+ (1,0) [0|31] "Km_per_h"  VMCU
 SG_ EcoCruisePwtMaxUnSpeedLev2 : 30|5@1+ (1,0) [0|31] "Km_per_h"  VMCU

BO_ 1285 EMS_BB2_14P: 8 EMS
 SG_ TotPTOLNGHighAccuracy : 0|32@1+ (0.01,0) [0|42949672.95] "kg"  VMCU

BO_ 1282 EMS_BB2_13P: 8 EMS
 SG_ ExhManif_EMAIAirTankPres_ISig_4 : 40|8@1+ (8,0) [0|2040] "kPa"  VMCU
 SG_ EngineFuelMode : 32|2@1+ (1,0) [0|0] ""  VMCU
 SG_ LNGOperatorInducementReason : 34|3@1+ (1,0) [0|0] ""  IC3
 SG_ DPF_RegenCompleted : 37|3@1+ (1,0) [0|0] ""  IC3
 SG_ EngineTotalLngConsumed_ISig_4 : 0|32@1+ (0.01,0) [0|42949672.95] "kg"  CIOM,IC3,VMCU

BO_ 1252 EMS_BB2_12P: 8 EMS
 SG_ DistLeftToSevereInducement_OBD : 32|8@1+ (5,0) [0|1275] "Km"  IC3
 SG_ TopGearUseDistance_ISig_4 : 0|32@1+ (0.01,0) [0|42949672.95] "km"  IC3

BO_ 961 EMS_BB2_11S_FCM: 8 CIOM
 SG_ EMS_BB2_11S_FCS : 0|64@1+ (1,0) [0|0] ""  EMS

BO_ 958 EMS_BB2_11S: 16 EMS
 SG_ KeyID_EngineStartAuth : 0|128@1+ (1,0) [0|0] ""  CIOM

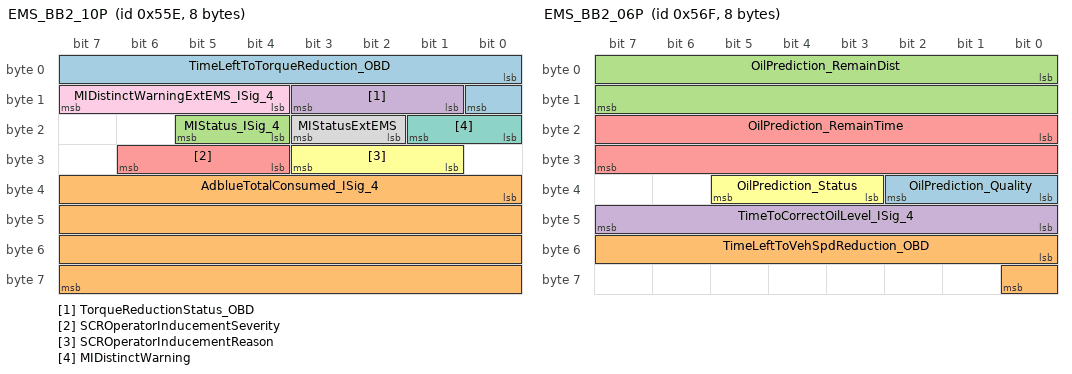
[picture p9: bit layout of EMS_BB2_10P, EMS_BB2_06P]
BO_ 1374 EMS_BB2_10P: 8 EMS
 SG_ TimeLeftToTorqueReduction_OBD : 0|9@1+ (12,0) [0|6132] "min"  IC3
 SG_ AdblueTotalConsumed_ISig_4 : 32|32@1+ (0.01,0) [0|42949672.95] "l"  VMCU,IC3
 SG_ MIStatus_ISig_4 : 20|2@1+ (1,0) [0|0] ""  VMCU,IC3
 SG_ TorqueReductionStatus_OBD : 9|3@1+ (1,0) [0|0] ""  IC3
 SG_ SCROperatorInducementSeverity : 28|3@1+ (1,0) [0|0] ""  IC3
 SG_ SCROperatorInducementReason : 25|3@1+ (1,0) [0|0] ""  IC3
 SG_ MIDistinctWarning : 16|2@1+ (1,0) [0|0] ""  VMCU,IC3
 SG_ MIStatusExtEMS : 18|2@1+ (1,0) [0|0] ""  IC3
 SG_ MIDistinctWarningExtEMS_ISig_4 : 12|4@1+ (1,0) [0|0] ""  VMCU,IC3

BO_ 1342 EMS_BB2_09S_FCM: 8 CIOM
 SG_ EMS_BB2_09S_FCS : 0|64@1+ (1,0) [0|0] ""  EMS

BO_ 1341 EMS_BB2_09S: 11 EMS
 SG_ ECU4VIN_stat : 0|88@1+ (1,0) [0|0] ""  CIOM

BO_ 1392 EMS_BB2_08P: 8 EMS
 SG_ EngineRunningTime_ISig_4 : 0|32@1+ (1,0) [0|4294967295] "s"  BBM,IC3,VMCU,CIOM
 SG_ TotPTOFuelHighAccuracy : 32|32@1+ (0.01,0) [0|42949672.95] "l"  VMCU

BO_ 1391 EMS_BB2_06P: 8 EMS
 SG_ OilPrediction_Quality : 32|3@1+ (1,0) [0|0] ""  CIOM,VMCU
 SG_ TimeLeftToVehSpdReduction_OBD : 48|9@1+ (15,0) [0|7665] "min"  IC3
 SG_ OilPrediction_RemainDist : 0|16@1+ (10,0) [0|655350] "km"  CIOM,VMCU
 SG_ TimeToCorrectOilLevel_ISig_4 : 40|8@1+ (1,0) [0|255] "min"  IC3
 SG_ OilPrediction_RemainTime : 16|16@1+ (1,0) [0|65535] "h"  VMCU,CIOM
 SG_ OilPrediction_Status : 35|3@1+ (1,0) [0|0] ""  CIOM,VMCU

CM_ SG_ 1377 GPSData_Longitude_ISig_4_561 "4261412864-4278190079 Error ; 4278190080-4294967295 Not available";
CM_ SG_ 1377 GPSData_Latitude_ISig_4_561 "4261412864-4278190079 Error ; 4278190080-4294967295 Not available";
CM_ SG_ 1377 GPSData_Time_ISig_4_561 "4261412864 - 4278190079 Error ; 4278190080 - 4294967295 Not available";
CM_ SG_ 1377 GPSData_VehSpeed_ISig_4_561 "65024 - 65279 Error ; 65280 - 65535 Not available";
CM_ SG_ 1375 GPSData_VehSpeed_ISig_4_55f "65024 - 65279 Error ; 65280 - 65535 Not available";
CM_ SG_ 1375 GPSData_Longitude_ISig_4_55f "4261412864-4278190079 Error ; 4278190080-4294967295 Not available";
CM_ SG_ 1375 GPSData_Time_ISig_4_55f "4261412864 - 4278190079 Error ; 4278190080 - 4294967295 Not available";
CM_ SG_ 1375 GPSData_Latitude_ISig_4_55f "4261412864-4278190079 Error ; 4278190080-4294967295 Not available";
CM_ SG_ 1381 GPSData_VehSpeed_ISig_4_565 "65024 - 65279 Error ; 65280 - 65535 Not available";
CM_ SG_ 1381 GPSData_Latitude_ISig_4_565 "4261412864-4278190079 Error ; 4278190080-4294967295 Not available";
CM_ SG_ 1381 GPSData_Time_ISig_4_565 "4261412864 - 4278190079 Error ; 4278190080 - 4294967295 Not available";
CM_ SG_ 1381 GPSData_Longitude_ISig_4_565 "4261412864-4278190079 Error ; 4278190080-4294967295 Not available";
CM_ SG_ 1386 GPSData_Latitude_ISig_4_56a "4261412864-4278190079 Error ; 4278190080-4294967295 Not available";
CM_ SG_ 1386 GPSData_Time_ISig_4_56a "4261412864 - 4278190079 Error ; 4278190080 - 4294967295 Not available";
CM_ SG_ 1386 GPSData_Longitude_ISig_4_56a "4261412864-4278190079 Error ; 4278190080-4294967295 Not available";
CM_ SG_ 1386 GPSData_VehSpeed_ISig_4_56a "65024 - 65279 Error ; 65280 - 65535 Not available";
CM_ SG_ 1384 GPSData_Time_ISig_4_568 "4261412864 - 4278190079 Error ; 4278190080 - 4294967295 Not available";
CM_ SG_ 1384 GPSData_Longitude_ISig_4_568 "4261412864-4278190079 Error ; 4278190080-4294967295 Not available";
CM_ SG_ 1384 GPSData_VehSpeed_ISig_4_568 "65024 - 65279 Error ; 65280 - 65535 Not available";
CM_ SG_ 1384 GPSData_Latitude_ISig_4_568 "4261412864-4278190079 Error ; 4278190080-4294967295 Not available";
CM_ SG_ 1270 CabLightIntensity_stat_ISig_4 "254 Error ; 255 Not available";
CM_ SG_ 739 CCBOverspeedRequest "65024 - 65279 Error ; 65280 - 65535 Not available";
CM_ SG_ 739 CCRequestedPresetSpeed "65024 - 65279 Error ; 65280 - 65535 Not available";
CM_ SG_ 739 ASLRequestedPresetSpeed "65024 - 65279 Error ; 65280 - 65535 Not available";
CM_ SG_ 1374 TimeLeftToTorqueReduction_OBD "510 Error ; 511 Not available";
CM_ SG_ 1374 AdblueTotalConsumed_ISig_4 "4261412864 - 4278190079 Error ; 4278190080 - 4294967295 Not available";
CM_ SG_ 1392 EngineRunningTime_ISig_4 "4261412864 - 4278190079 Error ; 4278190080 - 4294967295 Not available";
CM_ SG_ 1392 TotPTOFuelHighAccuracy "4261412864 - 4278190079 Error ; 4278190080 - 4294967295 Not available";
CM_ SG_ 1391 OilPrediction_RemainDist "65024 - 65279 Error ; 65280 - 65535 Not available";
CM_ SG_ 1391 TimeToCorrectOilLevel_ISig_4 "254 Error ; 255 Not Available";
CM_ SG_ 1391 OilPrediction_RemainTime "65024 - 65279 Error ; 65280 - 65535 Not available";
BA_DEF_ BO_  "GenMsgStartDelayTime" INT 0 0;
BA_DEF_ BO_  "GenMsgDelayTime" INT 0 0;
BA_DEF_ BO_  "GenMsgCycleTime" INT 0 0;
BA_DEF_ BO_  "GenMsgSendType" ENUM  "Cyclic","NotUsed","NotUsed","NotUsed","NotUsed","NotUsed","NotUsed","IfActive","NoMsgSendType","NotUsed";
BA_DEF_ SG_  "GenSigStartValue" INT 0 0;
BA_DEF_ SG_  "GenSigCycleTimeActive" INT 0 0;
BA_DEF_ SG_  "GenSigCycleTime" INT 0 0;
BA_DEF_ SG_  "GenSigSendType" ENUM  "Cyclic","OnWrite","OnWriteWithRepetition","OnChange","OnChangeWithRepetition","IfActive","IfActiveWithRepetition","NoSigSendType","NotUsed","NotUsed","NotUsed","NotUsed","NotUsed";
BA_DEF_ BO_  "VFrameFormat" ENUM  "StandardCAN","ExtendedCAN","reserved","J1939PG";
BA_DEF_ SG_  "SigType" ENUM  "Default","Range","RangeSigned","ASCII","Discrete","Control","ReferencePGN","DTC","StringDelimiter","StringLength","StringLengthControl";
BA_DEF_ SG_  "SeToolVersion_SIGNAL" STRING ;
BA_DEF_ SG_  "SeToolUniqueID_SIGNAL" STRING ;
BA_DEF_ SG_  "SeToolOwnerSigGroup_SIGNAL" STRING ;
BA_DEF_ SG_  "SeToolOwnerSigGroupID_SIGNAL" STRING ;
BA_DEF_ SG_  "SeToolName_SIGNAL" STRING ;
BA_DEF_ SG_  "SeToolItemID_SIGNAL" STRING ;
BA_DEF_ SG_  "SeToolAncestorID_SIGNAL" STRING ;
BA_DEF_ SG_  "Platform_VMCU1_Sig" ENUM  "No","Yes";
BA_DEF_ BO_  "NmAsrMessage" ENUM  "No","Yes";
BA_DEF_ SG_  "NeedsUpdateBit" ENUM  "No","Yes";
BA_DEF_ SG_  "MmAnSignal" ENUM  "No","Yes";
BA_DEF_ SG_  "GenSigMaxLatency" INT 0 65535;
BA_DEF_ SG_  "GenSigILSupport" ENUM  "Yes","No";
BA_DEF_ BO_  "GenMsgRequestable" INT 0 1;
BA_DEF_ BO_  "GenMsgILSupport" ENUM  "No","Yes";
BA_DEF_ BO_  "DiagUUDTResponse" ENUM  "No","Yes";
BA_DEF_ BO_  "DiagState" ENUM  "No","Yes";
BA_DEF_ BO_  "DiagResponse" ENUM  "No","Yes";
BA_DEF_ BO_  "DiagRequest" ENUM  "No","Yes";
BA_DEF_ BO_  "DiagConnection" HEX 0 65535;
BA_DEF_ BO_  "CanTpSTmin" INT 0 255;
BA_DEF_ BO_  "CanTpFcFrameId" HEX 0 2147483647;
BA_DEF_ BO_  "CanTpBs" INT 0 255;
BA_DEF_ SG_  "SystemSignalLongSymbol" STRING ;
BA_DEF_REL_ BU_SG_REL_  "GenSigTimeoutTime" INT 0 65535;
BA_DEF_REL_ BU_SG_REL_  "GenSigFirstTimeoutTime" INT 0 65535;
BA_DEF_DEF_  "GenMsgStartDelayTime" 0;
BA_DEF_DEF_  "GenMsgDelayTime" 0;
BA_DEF_DEF_  "GenMsgCycleTime" 0;
BA_DEF_DEF_  "GenMsgSendType" "Cyclic";
BA_DEF_DEF_  "GenSigStartValue" 0;
BA_DEF_DEF_  "GenSigCycleTimeActive" 0;
BA_DEF_DEF_  "GenSigCycleTime" 0;
BA_DEF_DEF_  "GenSigSendType" "Cyclic";
BA_DEF_DEF_  "VFrameFormat" "ExtendedCAN";
BA_DEF_DEF_  "SigType" "Default";
BA_DEF_DEF_  "SeToolVersion_SIGNAL" "";
BA_DEF_DEF_  "SeToolUniqueID_SIGNAL" "";
BA_DEF_DEF_  "SeToolOwnerSigGroup_SIGNAL" "";
BA_DEF_DEF_  "SeToolOwnerSigGroupID_SIGNAL" "";
BA_DEF_DEF_  "SeToolName_SIGNAL" "";
BA_DEF_DEF_  "SeToolItemID_SIGNAL" "";
BA_DEF_DEF_  "SeToolAncestorID_SIGNAL" "";
BA_DEF_DEF_  "Platform_VMCU1_Sig" "No";
BA_DEF_DEF_  "NmAsrMessage" "No";
BA_DEF_DEF_  "NeedsUpdateBit" "No";
BA_DEF_DEF_  "MmAnSignal" "No";
BA_DEF_DEF_  "GenSigMaxLatency" 0;
BA_DEF_DEF_  "GenSigILSupport" "Yes";
BA_DEF_DEF_  "GenMsgRequestable" 1;
BA_DEF_DEF_  "GenMsgILSupport" "Yes";
BA_DEF_DEF_  "DiagUUDTResponse" "No";
BA_DEF_DEF_  "DiagState" "No";
BA_DEF_DEF_  "DiagResponse" "No";
BA_DEF_DEF_  "DiagRequest" "No";
BA_DEF_DEF_  "DiagConnection" 0;
BA_DEF_DEF_  "CanTpSTmin" 0;
BA_DEF_DEF_  "CanTpFcFrameId" 2147483647;
BA_DEF_DEF_  "CanTpBs" 255;
BA_DEF_DEF_REL_ "GenSigTimeoutTime" 0;
BA_DEF_DEF_REL_ "GenSigFirstTimeoutTime" 0;
BA_DEF_DEF_  "SystemSignalLongSymbol" "";
BA_ "CanTpFcFrameId" BO_ 1443 1444;
BA_ "VFrameFormat" BO_ 1443 0;
BA_ "GenMsgSendType" BO_ 1443 8;
BA_ "GenMsgDelayTime" BO_ 1443 200;
BA_ "VFrameFormat" BO_ 1214 0;
BA_ "GenMsgSendType" BO_ 1214 8;
BA_ "GenMsgDelayTime" BO_ 1214 200;
BA_ "VFrameFormat" BO_ 1256 0;
BA_ "GenMsgSendType" BO_ 1256 8;
BA_ "GenMsgDelayTime" BO_ 1256 200;
BA_ "VFrameFormat" BO_ 839 0;
BA_ "GenMsgSendType" BO_ 839 8;
BA_ "GenMsgStartDelayTime" BO_ 839 20;
BA_ "VFrameFormat" BO_ 838 0;
BA_ "GenMsgCycleTime" BO_ 838 50;
BA_ "GenMsgStartDelayTime" BO_ 838 10;
BA_ "VFrameFormat" BO_ 515 0;
BA_ "GenMsgSendType" BO_ 515 8;
BA_ "GenMsgStartDelayTime" BO_ 515 20;
BA_ "CanTpSTmin" BO_ 1477 5;
BA_ "GenMsgILSupport" BO_ 1477 0;
BA_ "VFrameFormat" BO_ 1477 0;
BA_ "GenMsgSendType" BO_ 1477 8;
BA_ "VFrameFormat" BO_ 1422 0;
BA_ "GenMsgCycleTime" BO_ 1422 1000;
BA_ "GenMsgStartDelayTime" BO_ 1422 50;
BA_ "VFrameFormat" BO_ 1421 0;
BA_ "GenMsgCycleTime" BO_ 1421 100;
BA_ "GenMsgStartDelayTime" BO_ 1421 50;
BA_ "VFrameFormat" BO_ 518 0;
BA_ "GenMsgSendType" BO_ 518 8;
BA_ "GenMsgDelayTime" BO_ 518 20;
BA_ "GenMsgILSupport" BO_ 1397 0;
BA_ "VFrameFormat" BO_ 1397 0;
BA_ "GenMsgSendType" BO_ 1397 8;
BA_ "CanTpFcFrameId" BO_ 1396 1397;
BA_ "VFrameFormat" BO_ 1396 0;
BA_ "GenMsgSendType" BO_ 1396 8;
BA_ "GenMsgDelayTime" BO_ 1396 150;
BA_ "GenMsgILSupport" BO_ 952 0;
BA_ "VFrameFormat" BO_ 952 0;
BA_ "GenMsgSendType" BO_ 952 8;
BA_ "CanTpFcFrameId" BO_ 949 952;
BA_ "VFrameFormat" BO_ 949 0;
BA_ "GenMsgSendType" BO_ 949 8;
BA_ "GenMsgDelayTime" BO_ 949 100;
BA_ "VFrameFormat" BO_ 967 0;
BA_ "GenMsgSendType" BO_ 967 8;
BA_ "GenMsgDelayTime" BO_ 967 50;
BA_ "VFrameFormat" BO_ 822 0;
BA_ "GenMsgCycleTime" BO_ 822 50;
BA_ "GenMsgStartDelayTime" BO_ 822 25;
BA_ "VFrameFormat" BO_ 1337 0;
BA_ "GenMsgCycleTime" BO_ 1337 500;
BA_ "GenMsgStartDelayTime" BO_ 1337 285;
BA_ "VFrameFormat" BO_ 1336 0;
BA_ "GenMsgCycleTime" BO_ 1336 500;
BA_ "GenMsgStartDelayTime" BO_ 1336 100;
BA_ "CanTpFcFrameId" BO_ 1476 1477;
BA_ "CanTpSTmin" BO_ 1476 5;
BA_ "VFrameFormat" BO_ 1476 0;
BA_ "GenMsgSendType" BO_ 1476 8;
BA_ "GenMsgDelayTime" BO_ 1476 2400;
BA_ "GenMsgStartDelayTime" BO_ 1476 50;
BA_ "GenMsgILSupport" BO_ 1394 0;
BA_ "VFrameFormat" BO_ 1394 0;
BA_ "GenMsgSendType" BO_ 1394 8;
BA_ "VFrameFormat" BO_ 837 0;
BA_ "GenMsgCycleTime" BO_ 837 50;
BA_ "VFrameFormat" BO_ 1056 0;
BA_ "GenMsgCycleTime" BO_ 1056 150;
BA_ "GenMsgStartDelayTime" BO_ 1056 35;
BA_ "VFrameFormat" BO_ 1334 0;
BA_ "GenMsgCycleTime" BO_ 1334 500;
BA_ "GenMsgDelayTime" BO_ 1334 100;
BA_ "GenMsgStartDelayTime" BO_ 1334 250;
BA_ "GenMsgILSupport" BO_ 1344 0;
BA_ "VFrameFormat" BO_ 1344 0;
BA_ "GenMsgSendType" BO_ 1344 8;
BA_ "CanTpFcFrameId" BO_ 1343 1344;
BA_ "VFrameFormat" BO_ 1343 0;
BA_ "GenMsgSendType" BO_ 1343 8;
BA_ "GenMsgDelayTime" BO_ 1343 110;
BA_ "GenMsgStartDelayTime" BO_ 1343 50;
BA_ "GenMsgILSupport" BO_ 1379 0;
BA_ "VFrameFormat" BO_ 1379 0;
BA_ "GenMsgSendType" BO_ 1379 8;
BA_ "CanTpFcFrameId" BO_ 1377 1379;
BA_ "VFrameFormat" BO_ 1377 0;
BA_ "GenMsgCycleTime" BO_ 1377 500;
BA_ "GenMsgStartDelayTime" BO_ 1377 5;
BA_ "GenMsgILSupport" BO_ 1376 0;
BA_ "VFrameFormat" BO_ 1376 0;
BA_ "GenMsgSendType" BO_ 1376 8;
BA_ "CanTpFcFrameId" BO_ 1375 1376;
BA_ "VFrameFormat" BO_ 1375 0;
BA_ "GenMsgCycleTime" BO_ 1375 500;
BA_ "GenMsgStartDelayTime" BO_ 1375 50;
BA_ "GenMsgILSupport" BO_ 1382 0;
BA_ "VFrameFormat" BO_ 1382 0;
BA_ "GenMsgSendType" BO_ 1382 8;
BA_ "CanTpFcFrameId" BO_ 1381 1382;
BA_ "VFrameFormat" BO_ 1381 0;
BA_ "GenMsgCycleTime" BO_ 1381 500;
BA_ "GenMsgStartDelayTime" BO_ 1381 105;
BA_ "GenMsgILSupport" BO_ 1387 0;
BA_ "VFrameFormat" BO_ 1387 0;
BA_ "GenMsgSendType" BO_ 1387 8;
BA_ "CanTpFcFrameId" BO_ 1386 1387;
BA_ "VFrameFormat" BO_ 1386 0;
BA_ "GenMsgCycleTime" BO_ 1386 500;
BA_ "GenMsgStartDelayTime" BO_ 1386 210;
BA_ "GenMsgILSupport" BO_ 1385 0;
BA_ "VFrameFormat" BO_ 1385 0;
BA_ "GenMsgSendType" BO_ 1385 8;
BA_ "CanTpFcFrameId" BO_ 1384 1385;
BA_ "VFrameFormat" BO_ 1384 0;
BA_ "GenMsgCycleTime" BO_ 1384 500;
BA_ "GenMsgStartDelayTime" BO_ 1384 150;
BA_ "VFrameFormat" BO_ 979 0;
BA_ "GenMsgCycleTime" BO_ 979 75;
BA_ "GenMsgStartDelayTime" BO_ 979 5;
BA_ "VFrameFormat" BO_ 970 0;
BA_ "GenMsgCycleTime" BO_ 970 75;
BA_ "GenMsgStartDelayTime" BO_ 970 30;
BA_ "VFrameFormat" BO_ 851 0;
BA_ "GenMsgCycleTime" BO_ 851 60;
BA_ "GenMsgStartDelayTime" BO_ 851 10;
BA_ "VFrameFormat" BO_ 1270 0;
BA_ "GenMsgCycleTime" BO_ 1270 200;
BA_ "VFrameFormat" BO_ 739 0;
BA_ "GenMsgCycleTime" BO_ 739 35;
BA_ "GenMsgStartDelayTime" BO_ 739 20;
BA_ "VFrameFormat" BO_ 390 0;
BA_ "GenMsgCycleTime" BO_ 390 15;
BA_ "VFrameFormat" BO_ 514 0;
BA_ "GenMsgCycleTime" BO_ 514 25;
BA_ "GenMsgStartDelayTime" BO_ 514 5;
BA_ "VFrameFormat" BO_ 1288 0;
BA_ "GenMsgCycleTime" BO_ 1288 1000;
BA_ "GenMsgStartDelayTime" BO_ 1288 150;
BA_ "VFrameFormat" BO_ 1285 0;
BA_ "GenMsgCycleTime" BO_ 1285 1000;
BA_ "VFrameFormat" BO_ 1282 0;
BA_ "GenMsgCycleTime" BO_ 1282 500;
BA_ "GenMsgStartDelayTime" BO_ 1282 100;
BA_ "VFrameFormat" BO_ 1252 0;
BA_ "GenMsgCycleTime" BO_ 1252 1000;
BA_ "GenMsgStartDelayTime" BO_ 1252 75;
BA_ "GenMsgILSupport" BO_ 961 0;
BA_ "VFrameFormat" BO_ 961 0;
BA_ "GenMsgSendType" BO_ 961 8;
BA_ "CanTpFcFrameId" BO_ 958 961;
BA_ "VFrameFormat" BO_ 958 0;
BA_ "GenMsgSendType" BO_ 958 8;
BA_ "GenMsgDelayTime" BO_ 958 85;
BA_ "VFrameFormat" BO_ 1374 0;
BA_ "GenMsgCycleTime" BO_ 1374 1000;
BA_ "GenMsgStartDelayTime" BO_ 1374 40;
BA_ "GenMsgILSupport" BO_ 1342 0;
BA_ "VFrameFormat" BO_ 1342 0;
BA_ "GenMsgSendType" BO_ 1342 8;
BA_ "CanTpFcFrameId" BO_ 1341 1342;
BA_ "VFrameFormat" BO_ 1341 0;
BA_ "GenMsgSendType" BO_ 1341 8;
BA_ "GenMsgDelayTime" BO_ 1341 110;
BA_ "VFrameFormat" BO_ 1392 0;
BA_ "GenMsgCycleTime" BO_ 1392 1200;
BA_ "GenMsgStartDelayTime" BO_ 1392 60;
BA_ "VFrameFormat" BO_ 1391 0;
BA_ "GenMsgCycleTime" BO_ 1391 1500;
BA_ "GenMsgStartDelayTime" BO_ 1391 250;
BA_ "GenSigSendType" SG_ 1443 SaveTrlrName_rqst_Request 1;
BA_ "GenSigStartValue" SG_ 1443 SaveTrlrName_rqst_Request 3;
BA_ "GenSigMaxLatency" SG_ 1443 SaveTrlrName_rqst_Request 1000;
BA_ "NeedsUpdateBit" SG_ 1443 SaveTrlrName_rqst_Request 1;
BA_ "GenSigSendType" SG_ 1443 SaveTrlrName_rqst_sg_UB 7;
BA_ "GenSigSendType" SG_ 1443 SaveTrlrName_rqst_NewName 1;
BA_ "GenSigMaxLatency" SG_ 1443 SaveTrlrName_rqst_NewName 1000;
BA_ "NeedsUpdateBit" SG_ 1443 SaveTrlrName_rqst_NewName 1;
BA_ "GenSigSendType" SG_ 1443 SaveTrlrName_rqst_Position 1;
BA_ "GenSigStartValue" SG_ 1443 SaveTrlrName_rqst_Position 7;
BA_ "GenSigMaxLatency" SG_ 1443 SaveTrlrName_rqst_Position 1000;
BA_ "NeedsUpdateBit" SG_ 1443 SaveTrlrName_rqst_Position 1;
BA_ "GenSigSendType" SG_ 1214 ChangeDate_rqst_Day 1;
BA_ "GenSigCycleTime" SG_ 1214 ChangeDate_rqst_Day 100;
BA_ "GenSigCycleTimeActive" SG_ 1214 ChangeDate_rqst_Day 100;
BA_ "GenSigStartValue" SG_ 1214 ChangeDate_rqst_Day 255;
BA_ "GenSigMaxLatency" SG_ 1214 ChangeDate_rqst_Day 200;
BA_ "NeedsUpdateBit" SG_ 1214 ChangeDate_rqst_Day 1;
BA_ "GenSigSendType" SG_ 1214 ChangeDate_rqst_Year 1;
BA_ "GenSigCycleTime" SG_ 1214 ChangeDate_rqst_Year 100;
BA_ "GenSigCycleTimeActive" SG_ 1214 ChangeDate_rqst_Year 100;
BA_ "GenSigStartValue" SG_ 1214 ChangeDate_rqst_Year 255;
BA_ "GenSigMaxLatency" SG_ 1214 ChangeDate_rqst_Year 200;
BA_ "NeedsUpdateBit" SG_ 1214 ChangeDate_rqst_Year 1;
BA_ "GenSigSendType" SG_ 1214 ChangeDate_rqst_sg_UB 7;
BA_ "GenSigSendType" SG_ 1214 ChangeDate_rqst_Month 1;
BA_ "GenSigCycleTime" SG_ 1214 ChangeDate_rqst_Month 100;
BA_ "GenSigCycleTimeActive" SG_ 1214 ChangeDate_rqst_Month 100;
BA_ "GenSigStartValue" SG_ 1214 ChangeDate_rqst_Month 255;
BA_ "GenSigMaxLatency" SG_ 1214 ChangeDate_rqst_Month 200;
BA_ "NeedsUpdateBit" SG_ 1214 ChangeDate_rqst_Month 1;
BA_ "GenSigSendType" SG_ 1214 AdjustTimeOffset_rqst_sg_UB 7;
BA_ "GenSigSendType" SG_ 1214 AdjustTimeOffset_rqst_Hours 1;
BA_ "GenSigCycleTime" SG_ 1214 AdjustTimeOffset_rqst_Hours 100;
BA_ "GenSigCycleTimeActive" SG_ 1214 AdjustTimeOffset_rqst_Hours 100;
BA_ "GenSigStartValue" SG_ 1214 AdjustTimeOffset_rqst_Hours 255;
BA_ "GenSigMaxLatency" SG_ 1214 AdjustTimeOffset_rqst_Hours 200;
BA_ "NeedsUpdateBit" SG_ 1214 AdjustTimeOffset_rqst_Hours 1;
BA_ "GenSigSendType" SG_ 1214 AdjustTimeOffset_rqst_Minutes 1;
BA_ "GenSigCycleTime" SG_ 1214 AdjustTimeOffset_rqst_Minutes 100;
BA_ "GenSigCycleTimeActive" SG_ 1214 AdjustTimeOffset_rqst_Minutes 100;
BA_ "GenSigStartValue" SG_ 1214 AdjustTimeOffset_rqst_Minutes 255;
BA_ "GenSigMaxLatency" SG_ 1214 AdjustTimeOffset_rqst_Minutes 200;
BA_ "NeedsUpdateBit" SG_ 1214 AdjustTimeOffset_rqst_Minutes 1;
BA_ "GenSigSendType" SG_ 1256 AlmClkSnze_rqst_sg_UB 7;
BA_ "GenSigSendType" SG_ 1256 AlmClkSetAlarm_rqst_sg_UB 7;
BA_ "GenSigSendType" SG_ 1256 AlmClkSetAlarm_rqst_Stat 1;
BA_ "GenSigCycleTime" SG_ 1256 AlmClkSetAlarm_rqst_Stat 100;
BA_ "GenSigCycleTimeActive" SG_ 1256 AlmClkSetAlarm_rqst_Stat 100;
BA_ "GenSigStartValue" SG_ 1256 AlmClkSetAlarm_rqst_Stat 3;
BA_ "GenSigMaxLatency" SG_ 1256 AlmClkSetAlarm_rqst_Stat 210;
BA_ "NeedsUpdateBit" SG_ 1256 AlmClkSetAlarm_rqst_Stat 1;
BA_ "GenSigSendType" SG_ 1256 AlmClkSetAlarm_rqst_Mode 1;
BA_ "GenSigCycleTime" SG_ 1256 AlmClkSetAlarm_rqst_Mode 100;
BA_ "GenSigCycleTimeActive" SG_ 1256 AlmClkSetAlarm_rqst_Mode 100;
BA_ "GenSigStartValue" SG_ 1256 AlmClkSetAlarm_rqst_Mode 3;
BA_ "GenSigMaxLatency" SG_ 1256 AlmClkSetAlarm_rqst_Mode 210;
BA_ "NeedsUpdateBit" SG_ 1256 AlmClkSetAlarm_rqst_Mode 1;
BA_ "GenSigSendType" SG_ 1256 AlmClkSetAlarm_rqst_SetHr 1;
BA_ "GenSigCycleTime" SG_ 1256 AlmClkSetAlarm_rqst_SetHr 100;
BA_ "GenSigCycleTimeActive" SG_ 1256 AlmClkSetAlarm_rqst_SetHr 100;
BA_ "GenSigStartValue" SG_ 1256 AlmClkSetAlarm_rqst_SetHr 31;
BA_ "GenSigMaxLatency" SG_ 1256 AlmClkSetAlarm_rqst_SetHr 210;
BA_ "NeedsUpdateBit" SG_ 1256 AlmClkSetAlarm_rqst_SetHr 1;
BA_ "GenSigSendType" SG_ 1256 AlmClkSetAlarm_rqst_ID 1;
BA_ "GenSigCycleTime" SG_ 1256 AlmClkSetAlarm_rqst_ID 100;
BA_ "GenSigCycleTimeActive" SG_ 1256 AlmClkSetAlarm_rqst_ID 100;
BA_ "GenSigStartValue" SG_ 1256 AlmClkSetAlarm_rqst_ID 127;
BA_ "GenSigMaxLatency" SG_ 1256 AlmClkSetAlarm_rqst_ID 210;
BA_ "NeedsUpdateBit" SG_ 1256 AlmClkSetAlarm_rqst_ID 1;
BA_ "GenSigSendType" SG_ 1256 AlmClkSetAlarm_rqst_SetMin 1;
BA_ "GenSigCycleTime" SG_ 1256 AlmClkSetAlarm_rqst_SetMin 100;
BA_ "GenSigCycleTimeActive" SG_ 1256 AlmClkSetAlarm_rqst_SetMin 100;
BA_ "GenSigStartValue" SG_ 1256 AlmClkSetAlarm_rqst_SetMin 63;
BA_ "GenSigMaxLatency" SG_ 1256 AlmClkSetAlarm_rqst_SetMin 210;
BA_ "NeedsUpdateBit" SG_ 1256 AlmClkSetAlarm_rqst_SetMin 1;
BA_ "GenSigSendType" SG_ 1256 AlmClkSetAlarm_rqst_Type 1;
BA_ "GenSigCycleTime" SG_ 1256 AlmClkSetAlarm_rqst_Type 100;
BA_ "GenSigCycleTimeActive" SG_ 1256 AlmClkSetAlarm_rqst_Type 100;
BA_ "GenSigStartValue" SG_ 1256 AlmClkSetAlarm_rqst_Type 7;
BA_ "GenSigMaxLatency" SG_ 1256 AlmClkSetAlarm_rqst_Type 210;
BA_ "NeedsUpdateBit" SG_ 1256 AlmClkSetAlarm_rqst_Type 1;
BA_ "GenSigSendType" SG_ 1256 AlmClkSnze_rqst_ID 1;
BA_ "GenSigCycleTime" SG_ 1256 AlmClkSnze_rqst_ID 100;
BA_ "GenSigCycleTimeActive" SG_ 1256 AlmClkSnze_rqst_ID 100;
BA_ "GenSigStartValue" SG_ 1256 AlmClkSnze_rqst_ID 127;
BA_ "GenSigMaxLatency" SG_ 1256 AlmClkSnze_rqst_ID 210;
BA_ "NeedsUpdateBit" SG_ 1256 AlmClkSnze_rqst_ID 1;
BA_ "GenSigSendType" SG_ 1256 AlmClkSetAlarm_rqst_DaySet 1;
BA_ "GenSigCycleTime" SG_ 1256 AlmClkSetAlarm_rqst_DaySet 100;
BA_ "GenSigCycleTimeActive" SG_ 1256 AlmClkSetAlarm_rqst_DaySet 100;
BA_ "GenSigStartValue" SG_ 1256 AlmClkSetAlarm_rqst_DaySet 255;
BA_ "GenSigMaxLatency" SG_ 1256 AlmClkSetAlarm_rqst_DaySet 210;
BA_ "NeedsUpdateBit" SG_ 1256 AlmClkSetAlarm_rqst_DaySet 1;
BA_ "GenSigSendType" SG_ 1256 AlmClkSnze_rqst_Action 1;
BA_ "GenSigCycleTime" SG_ 1256 AlmClkSnze_rqst_Action 100;
BA_ "GenSigCycleTimeActive" SG_ 1256 AlmClkSnze_rqst_Action 100;
BA_ "GenSigStartValue" SG_ 1256 AlmClkSnze_rqst_Action 7;
BA_ "GenSigMaxLatency" SG_ 1256 AlmClkSnze_rqst_Action 210;
BA_ "NeedsUpdateBit" SG_ 1256 AlmClkSnze_rqst_Action 1;
BA_ "GenSigSendType" SG_ 839 UpdParkClimTimerRqst_sg_UB_ISig_ 7;
BA_ "SystemSignalLongSymbol" SG_ 839 UpdParkClimTimerRqst_sg_UB_ISig_ "UpdParkClimTimerRqst_sg_UB_ISig_4";
BA_ "GenSigSendType" SG_ 839 UpdParkClimTimerRqst_TimerCmd_IS 1;
BA_ "GenSigStartValue" SG_ 839 UpdParkClimTimerRqst_TimerCmd_IS 7;
BA_ "NeedsUpdateBit" SG_ 839 UpdParkClimTimerRqst_TimerCmd_IS 1;
BA_ "SystemSignalLongSymbol" SG_ 839 UpdParkClimTimerRqst_TimerCmd_IS "UpdParkClimTimerRqst_TimerCmd_ISig_4";
BA_ "GenSigSendType" SG_ 839 CombinationScaleLoad_ScaleLoad 1;
BA_ "GenSigStartValue" SG_ 839 CombinationScaleLoad_ScaleLoad 4294967295;
BA_ "GenSigSendType" SG_ 839 UpdParkClimTimerRqst_TimRqst_ISi 1;
BA_ "GenSigStartValue" SG_ 839 UpdParkClimTimerRqst_TimRqst_ISi 255;
BA_ "NeedsUpdateBit" SG_ 839 UpdParkClimTimerRqst_TimRqst_ISi 1;
BA_ "SystemSignalLongSymbol" SG_ 839 UpdParkClimTimerRqst_TimRqst_ISi "UpdParkClimTimerRqst_TimRqst_ISig_4";
BA_ "GenSigSendType" SG_ 839 CombinationScaleLoad_FirstAxleID 1;
BA_ "GenSigStartValue" SG_ 839 CombinationScaleLoad_FirstAxleID 255;
BA_ "GenSigSendType" SG_ 839 CombinationScaleLoad_LastAxleID 1;
BA_ "GenSigStartValue" SG_ 839 CombinationScaleLoad_LastAxleID 255;
BA_ "GenSigCycleTime" SG_ 838 AirbagTelltale_stat_ISig_4 100;
BA_ "GenSigCycleTimeActive" SG_ 838 AirbagTelltale_stat_ISig_4 100;
BA_ "GenSigStartValue" SG_ 838 AirbagTelltale_stat_ISig_4 3;
BA_ "GenSigCycleTime" SG_ 838 AQSModeRqst_ISig_4 100;
BA_ "GenSigCycleTimeActive" SG_ 838 AQSModeRqst_ISig_4 100;
BA_ "GenSigStartValue" SG_ 838 AQSModeRqst_ISig_4 7;
BA_ "GenSigCycleTime" SG_ 838 VCSystPowerSupply_rqst 100;
BA_ "GenSigCycleTimeActive" SG_ 838 VCSystPowerSupply_rqst 100;
BA_ "GenSigStartValue" SG_ 838 VCSystPowerSupply_rqst 3;
BA_ "GenSigCycleTime" SG_ 838 ISeeEnableRequest 100;
BA_ "GenSigCycleTimeActive" SG_ 838 ISeeEnableRequest 100;
BA_ "GenSigStartValue" SG_ 838 ISeeEnableRequest 3;
BA_ "GenSigCycleTime" SG_ 838 ACModeRqst_ISig_4 100;
BA_ "GenSigCycleTimeActive" SG_ 838 ACModeRqst_ISig_4 100;
BA_ "GenSigStartValue" SG_ 838 ACModeRqst_ISig_4 7;
BA_ "GenSigCycleTime" SG_ 838 RemoteParkClimateRqst_ISig_4 100;
BA_ "GenSigCycleTimeActive" SG_ 838 RemoteParkClimateRqst_ISig_4 100;
BA_ "GenSigStartValue" SG_ 838 RemoteParkClimateRqst_ISig_4 7;
BA_ "GenSigCycleTime" SG_ 838 CalDataLoad_rqst_VehicleID 100;
BA_ "GenSigCycleTimeActive" SG_ 838 CalDataLoad_rqst_VehicleID 100;
BA_ "GenSigStartValue" SG_ 838 CalDataLoad_rqst_VehicleID 7;
BA_ "GenSigCycleTime" SG_ 838 CalDataLoad_rqst_AxleID 100;
BA_ "GenSigCycleTimeActive" SG_ 838 CalDataLoad_rqst_AxleID 100;
BA_ "GenSigStartValue" SG_ 838 CalDataLoad_rqst_AxleID 15;
BA_ "GenSigCycleTime" SG_ 838 AutoBlowerLevelRqst_ISig_4 100;
BA_ "GenSigCycleTimeActive" SG_ 838 AutoBlowerLevelRqst_ISig_4 100;
BA_ "GenSigStartValue" SG_ 838 AutoBlowerLevelRqst_ISig_4 7;
BA_ "GenSigCycleTime" SG_ 838 AutoDefogModeRqst_ISig_4 100;
BA_ "GenSigCycleTimeActive" SG_ 838 AutoDefogModeRqst_ISig_4 100;
BA_ "GenSigStartValue" SG_ 838 AutoDefogModeRqst_ISig_4 7;
BA_ "GenSigSendType" SG_ 515 SetParkClimTimerRqst_Mon_ISig_4 1;
BA_ "NeedsUpdateBit" SG_ 515 SetParkClimTimerRqst_Mon_ISig_4 1;
BA_ "GenSigSendType" SG_ 515 SetParkClimTimerRqst_Tue_ISig_4 1;
BA_ "NeedsUpdateBit" SG_ 515 SetParkClimTimerRqst_Tue_ISig_4 1;
BA_ "GenSigSendType" SG_ 515 SetParkClimTimerRqst_Sat_ISig_4 1;
BA_ "NeedsUpdateBit" SG_ 515 SetParkClimTimerRqst_Sat_ISig_4 1;
BA_ "GenSigSendType" SG_ 515 SetParkClimTimerRqst_Dur_ISig_4 1;
BA_ "GenSigStartValue" SG_ 515 SetParkClimTimerRqst_Dur_ISig_4 127;
BA_ "NeedsUpdateBit" SG_ 515 SetParkClimTimerRqst_Dur_ISig_4 1;
BA_ "GenSigSendType" SG_ 515 SetParkClimTimerRqst_Type_ISig_4 1;
BA_ "GenSigStartValue" SG_ 515 SetParkClimTimerRqst_Type_ISig_4 7;
BA_ "NeedsUpdateBit" SG_ 515 SetParkClimTimerRqst_Type_ISig_4 1;
BA_ "GenSigSendType" SG_ 515 SetParkClimTimerRqst_Sun_ISig_4 1;
BA_ "NeedsUpdateBit" SG_ 515 SetParkClimTimerRqst_Sun_ISig_4 1;
BA_ "GenSigSendType" SG_ 515 SetParkClimTimerRqst_Wed_ISig_4 1;
BA_ "NeedsUpdateBit" SG_ 515 SetParkClimTimerRqst_Wed_ISig_4 1;
BA_ "GenSigSendType" SG_ 515 SetParkClimTimerRqst_TimerNr_ISi 1;
BA_ "GenSigStartValue" SG_ 515 SetParkClimTimerRqst_TimerNr_ISi 255;
BA_ "NeedsUpdateBit" SG_ 515 SetParkClimTimerRqst_TimerNr_ISi 1;
BA_ "SystemSignalLongSymbol" SG_ 515 SetParkClimTimerRqst_TimerNr_ISi "SetParkClimTimerRqst_TimerNr_ISig_4";
BA_ "GenSigSendType" SG_ 515 SetParkClimTimerRqst_Min_ISig_4 1;
BA_ "GenSigStartValue" SG_ 515 SetParkClimTimerRqst_Min_ISig_4 255;
BA_ "NeedsUpdateBit" SG_ 515 SetParkClimTimerRqst_Min_ISig_4 1;
BA_ "GenSigSendType" SG_ 515 SetParkClimTimerRqst_Hrs_ISig_4 1;
BA_ "GenSigStartValue" SG_ 515 SetParkClimTimerRqst_Hrs_ISig_4 255;
BA_ "NeedsUpdateBit" SG_ 515 SetParkClimTimerRqst_Hrs_ISig_4 1;
BA_ "GenSigSendType" SG_ 515 SetParkClimTimerRqst_Temp_ISig_4 1;
BA_ "GenSigStartValue" SG_ 515 SetParkClimTimerRqst_Temp_ISig_4 255;
BA_ "NeedsUpdateBit" SG_ 515 SetParkClimTimerRqst_Temp_ISig_4 1;
BA_ "GenSigSendType" SG_ 515 SetParkClimTimerRqst_Thu_ISig_4 1;
BA_ "NeedsUpdateBit" SG_ 515 SetParkClimTimerRqst_Thu_ISig_4 1;
BA_ "GenSigSendType" SG_ 515 SetParkClimTimerRqst_sg_UB_ISig_ 7;
BA_ "SystemSignalLongSymbol" SG_ 515 SetParkClimTimerRqst_sg_UB_ISig_ "SetParkClimTimerRqst_sg_UB_ISig_4";
BA_ "GenSigSendType" SG_ 515 SetParkClimTimerRqst_TimerCmd_IS 1;
BA_ "GenSigStartValue" SG_ 515 SetParkClimTimerRqst_TimerCmd_IS 7;
BA_ "NeedsUpdateBit" SG_ 515 SetParkClimTimerRqst_TimerCmd_IS 1;
BA_ "SystemSignalLongSymbol" SG_ 515 SetParkClimTimerRqst_TimerCmd_IS "SetParkClimTimerRqst_TimerCmd_ISig_4";
BA_ "GenSigSendType" SG_ 515 SetParkClimTimerRqst_Fri_ISig_4 1;
BA_ "NeedsUpdateBit" SG_ 515 SetParkClimTimerRqst_Fri_ISig_4 1;
BA_ "GenSigSendType" SG_ 515 SetParkClimTimerRqst_Rec_ISig_4 1;
BA_ "NeedsUpdateBit" SG_ 515 SetParkClimTimerRqst_Rec_ISig_4 1;
BA_ "GenSigSendType" SG_ 1477 HMIIOM_BB2_S28_FCS 7;
BA_ "Platform_VMCU1_Sig" SG_ 1477 HMIIOM_BB2_S28_FCS 1;
BA_ "GenSigCycleTime" SG_ 1422 FasUsrDefinedStorage_rqst_ISig_4 100;
BA_ "GenSigCycleTimeActive" SG_ 1422 FasUsrDefinedStorage_rqst_ISig_4 100;
BA_ "GenSigStartValue" SG_ 1422 FasUsrDefinedStorage_rqst_ISig_4 3;
BA_ "GenSigMaxLatency" SG_ 1422 FasUsrDefinedStorage_rqst_ISig_4 1037;
BA_ "GenSigCycleTime" SG_ 1422 ATC_ButtonIndication 100;
BA_ "GenSigCycleTimeActive" SG_ 1422 ATC_ButtonIndication 100;
BA_ "GenSigMaxLatency" SG_ 1422 ATC_ButtonIndication 1037;
BA_ "GenSigCycleTime" SG_ 1422 FasLowSpeedReturnSetting_rqst_IS 100;
BA_ "GenSigCycleTimeActive" SG_ 1422 FasLowSpeedReturnSetting_rqst_IS 100;
BA_ "GenSigStartValue" SG_ 1422 FasLowSpeedReturnSetting_rqst_IS 31;
BA_ "GenSigMaxLatency" SG_ 1422 FasLowSpeedReturnSetting_rqst_IS 1037;
BA_ "SystemSignalLongSymbol" SG_ 1422 FasLowSpeedReturnSetting_rqst_IS "FasLowSpeedReturnSetting_rqst_ISig_4";
BA_ "GenSigCycleTime" SG_ 1422 FasManualOffsetSetting_rqst_ISig 100;
BA_ "GenSigCycleTimeActive" SG_ 1422 FasManualOffsetSetting_rqst_ISig 100;
BA_ "GenSigStartValue" SG_ 1422 FasManualOffsetSetting_rqst_ISig 31;
BA_ "GenSigMaxLatency" SG_ 1422 FasManualOffsetSetting_rqst_ISig 1037;
BA_ "SystemSignalLongSymbol" SG_ 1422 FasManualOffsetSetting_rqst_ISig "FasManualOffsetSetting_rqst_ISig_4";
BA_ "GenSigCycleTime" SG_ 1422 FasPersonalSettingsButton_rqst_I 100;
BA_ "GenSigCycleTimeActive" SG_ 1422 FasPersonalSettingsButton_rqst_I 100;
BA_ "GenSigStartValue" SG_ 1422 FasPersonalSettingsButton_rqst_I 7;
BA_ "GenSigMaxLatency" SG_ 1422 FasPersonalSettingsButton_rqst_I 1037;
BA_ "SystemSignalLongSymbol" SG_ 1422 FasPersonalSettingsButton_rqst_I "FasPersonalSettingsButton_rqst_ISig_4";
BA_ "GenSigCycleTime" SG_ 1422 FasStiffnessCurveSetting_rqst_IS 100;
BA_ "GenSigCycleTimeActive" SG_ 1422 FasStiffnessCurveSetting_rqst_IS 100;
BA_ "GenSigStartValue" SG_ 1422 FasStiffnessCurveSetting_rqst_IS 31;
BA_ "GenSigMaxLatency" SG_ 1422 FasStiffnessCurveSetting_rqst_IS 1037;
BA_ "SystemSignalLongSymbol" SG_ 1422 FasStiffnessCurveSetting_rqst_IS "FasStiffnessCurveSetting_rqst_ISig_4";
BA_ "GenSigCycleTime" SG_ 1422 FasStiffStraightSetting_rqst_ISi 100;
BA_ "GenSigCycleTimeActive" SG_ 1422 FasStiffStraightSetting_rqst_ISi 100;
BA_ "GenSigStartValue" SG_ 1422 FasStiffStraightSetting_rqst_ISi 31;
BA_ "GenSigMaxLatency" SG_ 1422 FasStiffStraightSetting_rqst_ISi 1037;
BA_ "SystemSignalLongSymbol" SG_ 1422 FasStiffStraightSetting_rqst_ISi "FasStiffStraightSetting_rqst_ISig_4";
BA_ "GenSigCycleTime" SG_ 1422 FasDriver_rqst_ISig_4 100;
BA_ "GenSigCycleTimeActive" SG_ 1422 FasDriver_rqst_ISig_4 100;
BA_ "GenSigStartValue" SG_ 1422 FasDriver_rqst_ISig_4 15;
BA_ "GenSigMaxLatency" SG_ 1422 FasDriver_rqst_ISig_4 1037;
BA_ "GenSigCycleTime" SG_ 1422 FasDampingSetting_rqst_ISig_4 100;
BA_ "GenSigCycleTimeActive" SG_ 1422 FasDampingSetting_rqst_ISig_4 100;
BA_ "GenSigStartValue" SG_ 1422 FasDampingSetting_rqst_ISig_4 31;
BA_ "GenSigMaxLatency" SG_ 1422 FasDampingSetting_rqst_ISig_4 1037;
BA_ "GenSigCycleTime" SG_ 1422 ESC_ButtonIndication2 100;
BA_ "GenSigCycleTimeActive" SG_ 1422 ESC_ButtonIndication2 100;
BA_ "GenSigMaxLatency" SG_ 1422 ESC_ButtonIndication2 1037;
BA_ "GenSigCycleTime" SG_ 1422 TCS_ButtonIndication 100;
BA_ "GenSigCycleTimeActive" SG_ 1422 TCS_ButtonIndication 100;
BA_ "GenSigMaxLatency" SG_ 1422 TCS_ButtonIndication 1037;
BA_ "GenSigCycleTime" SG_ 1422 ABS_ButtonIndication 100;
BA_ "GenSigCycleTimeActive" SG_ 1422 ABS_ButtonIndication 100;
BA_ "GenSigMaxLatency" SG_ 1422 ABS_ButtonIndication 1037;
BA_ "GenSigCycleTime" SG_ 1421 ESCOff_DeviceIndication 100;
BA_ "GenSigCycleTimeActive" SG_ 1421 ESCOff_DeviceIndication 100;
BA_ "GenSigStartValue" SG_ 1421 ESCOff_DeviceIndication 3;
BA_ "GenSigMaxLatency" SG_ 1421 ESCOff_DeviceIndication 102;
BA_ "Platform_VMCU1_Sig" SG_ 1421 ESCOff_DeviceIndication 1;
BA_ "GenSigCycleTime" SG_ 1421 CCUnderSpeedRequest 100;
BA_ "GenSigCycleTimeActive" SG_ 1421 CCUnderSpeedRequest 100;
BA_ "GenSigStartValue" SG_ 1421 CCUnderSpeedRequest 65535;
BA_ "GenSigCycleTime" SG_ 1421 DHCActiveRequest 100;
BA_ "GenSigCycleTimeActive" SG_ 1421 DHCActiveRequest 100;
BA_ "GenSigStartValue" SG_ 1421 DHCActiveRequest 3;
BA_ "GenSigCycleTime" SG_ 1421 RollerBenchGUIDeviceStatus 100;
BA_ "GenSigCycleTimeActive" SG_ 1421 RollerBenchGUIDeviceStatus 100;
BA_ "GenSigStartValue" SG_ 1421 RollerBenchGUIDeviceStatus 3;
BA_ "GenSigMaxLatency" SG_ 1421 RollerBenchGUIDeviceStatus 102;
BA_ "Platform_VMCU1_Sig" SG_ 1421 RollerBenchGUIDeviceStatus 1;
BA_ "GenSigCycleTime" SG_ 1421 DHCSetSpeedAdjustRequest 100;
BA_ "GenSigCycleTimeActive" SG_ 1421 DHCSetSpeedAdjustRequest 100;
BA_ "GenSigStartValue" SG_ 1421 DHCSetSpeedAdjustRequest 7;
BA_ "GenSigCycleTime" SG_ 1421 AutomaticCMenableStatus 100;
BA_ "GenSigCycleTimeActive" SG_ 1421 AutomaticCMenableStatus 100;
BA_ "GenSigStartValue" SG_ 1421 AutomaticCMenableStatus 3;
BA_ "GenSigMaxLatency" SG_ 1421 AutomaticCMenableStatus 102;
BA_ "Platform_VMCU1_Sig" SG_ 1421 AutomaticCMenableStatus 1;
BA_ "GenSigCycleTime" SG_ 1421 SetDaylightSaving_rqst 100;
BA_ "GenSigCycleTimeActive" SG_ 1421 SetDaylightSaving_rqst 100;
BA_ "GenSigStartValue" SG_ 1421 SetDaylightSaving_rqst 3;
BA_ "GenSigCycleTime" SG_ 1421 CamerasPowerSupply_rqst 100;
BA_ "GenSigCycleTimeActive" SG_ 1421 CamerasPowerSupply_rqst 100;
BA_ "GenSigStartValue" SG_ 1421 CamerasPowerSupply_rqst 3;
BA_ "GenSigCycleTime" SG_ 1421 AFSActiveAllowedInDP_GUIrqst 100;
BA_ "GenSigCycleTimeActive" SG_ 1421 AFSActiveAllowedInDP_GUIrqst 100;
BA_ "GenSigStartValue" SG_ 1421 AFSActiveAllowedInDP_GUIrqst 3;
BA_ "GenSigSendType" SG_ 518 AdasisMapData_ISig_4 1;
BA_ "GenSigCycleTime" SG_ 518 AdasisMapData_ISig_4 100;
BA_ "GenSigCycleTimeActive" SG_ 518 AdasisMapData_ISig_4 100;
BA_ "Platform_VMCU1_Sig" SG_ 518 AdasisMapData_ISig_4 1;
BA_ "GenSigSendType" SG_ 1397 HMIIOM_BB2_36S_FCS 7;
BA_ "Platform_VMCU1_Sig" SG_ 1397 HMIIOM_BB2_36S_FCS 1;
BA_ "GenSigSendType" SG_ 1396 SEM_DisplayText_stat_ISig_4 1;
BA_ "GenSigMaxLatency" SG_ 1396 SEM_DisplayText_stat_ISig_4 170;
BA_ "Platform_VMCU1_Sig" SG_ 1396 SEM_DisplayText_stat_ISig_4 1;
BA_ "GenSigSendType" SG_ 952 HMIIOM_BB2_35S_FCS 7;
BA_ "Platform_VMCU1_Sig" SG_ 952 HMIIOM_BB2_35S_FCS 1;
BA_ "GenSigSendType" SG_ 949 MediaSourcesListRsp_sg_UB_ISig_4 7;
BA_ "Platform_VMCU1_Sig" SG_ 949 MediaSourcesListRsp_sg_UB_ISig_4 1;
BA_ "GenSigSendType" SG_ 949 MediaSourcesListRsp_SrcAttrib_IS 1;
BA_ "GenSigMaxLatency" SG_ 949 MediaSourcesListRsp_SrcAttrib_IS 100;
BA_ "NeedsUpdateBit" SG_ 949 MediaSourcesListRsp_SrcAttrib_IS 1;
BA_ "Platform_VMCU1_Sig" SG_ 949 MediaSourcesListRsp_SrcAttrib_IS 1;
BA_ "SystemSignalLongSymbol" SG_ 949 MediaSourcesListRsp_SrcAttrib_IS "MediaSourcesListRsp_SrcAttrib_ISig_4";
BA_ "GenSigSendType" SG_ 949 MediaSourcesListRsp_SInfo_ISig_4 1;
BA_ "GenSigStartValue" SG_ 949 MediaSourcesListRsp_SInfo_ISig_4 3;
BA_ "GenSigMaxLatency" SG_ 949 MediaSourcesListRsp_SInfo_ISig_4 100;
BA_ "NeedsUpdateBit" SG_ 949 MediaSourcesListRsp_SInfo_ISig_4 1;
BA_ "Platform_VMCU1_Sig" SG_ 949 MediaSourcesListRsp_SInfo_ISig_4 1;
BA_ "GenSigSendType" SG_ 949 MediaSourcesListRsp_Name_ISig_4 1;
BA_ "GenSigMaxLatency" SG_ 949 MediaSourcesListRsp_Name_ISig_4 100;
BA_ "NeedsUpdateBit" SG_ 949 MediaSourcesListRsp_Name_ISig_4 1;
BA_ "Platform_VMCU1_Sig" SG_ 949 MediaSourcesListRsp_Name_ISig_4 1;
BA_ "GenSigSendType" SG_ 949 MediaSourcesListRsp_PCI_ISig_4 1;
BA_ "GenSigMaxLatency" SG_ 949 MediaSourcesListRsp_PCI_ISig_4 100;
BA_ "NeedsUpdateBit" SG_ 949 MediaSourcesListRsp_PCI_ISig_4 1;
BA_ "Platform_VMCU1_Sig" SG_ 949 MediaSourcesListRsp_PCI_ISig_4 1;
BA_ "GenSigSendType" SG_ 949 MediaSourcesListRsp_ItemID_ISig_ 1;
BA_ "GenSigMaxLatency" SG_ 949 MediaSourcesListRsp_ItemID_ISig_ 100;
BA_ "NeedsUpdateBit" SG_ 949 MediaSourcesListRsp_ItemID_ISig_ 1;
BA_ "Platform_VMCU1_Sig" SG_ 949 MediaSourcesListRsp_ItemID_ISig_ 1;
BA_ "SystemSignalLongSymbol" SG_ 949 MediaSourcesListRsp_ItemID_ISig_ "MediaSourcesListRsp_ItemID_ISig_4";
BA_ "GenSigSendType" SG_ 967 MediaSourcesListNPRsp_ISig_4 1;
BA_ "GenSigMaxLatency" SG_ 967 MediaSourcesListNPRsp_ISig_4 50;
BA_ "NeedsUpdateBit" SG_ 967 MediaSourcesListNPRsp_ISig_4 1;
BA_ "Platform_VMCU1_Sig" SG_ 967 MediaSourcesListNPRsp_ISig_4 1;
BA_ "GenSigSendType" SG_ 967 MediaSourcesListNPRsp_UB_ISig_4 7;
BA_ "Platform_VMCU1_Sig" SG_ 967 MediaSourcesListNPRsp_UB_ISig_4 1;
BA_ "GenSigCycleTime" SG_ 822 SEMMediaSourceAvail_Source04_ISi 100;
BA_ "GenSigCycleTimeActive" SG_ 822 SEMMediaSourceAvail_Source04_ISi 100;
BA_ "Platform_VMCU1_Sig" SG_ 822 SEMMediaSourceAvail_Source04_ISi 1;
BA_ "SystemSignalLongSymbol" SG_ 822 SEMMediaSourceAvail_Source04_ISi "SEMMediaSourceAvail_Source04_ISig_4";
BA_ "GenSigCycleTime" SG_ 822 SEMMediaSourceAvail_Source10_ISi 100;
BA_ "GenSigCycleTimeActive" SG_ 822 SEMMediaSourceAvail_Source10_ISi 100;
BA_ "Platform_VMCU1_Sig" SG_ 822 SEMMediaSourceAvail_Source10_ISi 1;
BA_ "SystemSignalLongSymbol" SG_ 822 SEMMediaSourceAvail_Source10_ISi "SEMMediaSourceAvail_Source10_ISig_4";
BA_ "GenSigCycleTime" SG_ 822 SEMMediaSourceAvail_SInfo_ISig_4 100;
BA_ "GenSigCycleTimeActive" SG_ 822 SEMMediaSourceAvail_SInfo_ISig_4 100;
BA_ "GenSigStartValue" SG_ 822 SEMMediaSourceAvail_SInfo_ISig_4 3;
BA_ "Platform_VMCU1_Sig" SG_ 822 SEMMediaSourceAvail_SInfo_ISig_4 1;
BA_ "GenSigCycleTime" SG_ 822 SEM_PresetIndicationCmd_ISig_4 100;
BA_ "GenSigCycleTimeActive" SG_ 822 SEM_PresetIndicationCmd_ISig_4 100;
BA_ "GenSigStartValue" SG_ 822 SEM_PresetIndicationCmd_ISig_4 63;
BA_ "Platform_VMCU1_Sig" SG_ 822 SEM_PresetIndicationCmd_ISig_4 1;
BA_ "GenSigCycleTime" SG_ 822 SEMMediaSourceAvail_Source09_ISi 100;
BA_ "GenSigCycleTimeActive" SG_ 822 SEMMediaSourceAvail_Source09_ISi 100;
BA_ "Platform_VMCU1_Sig" SG_ 822 SEMMediaSourceAvail_Source09_ISi 1;
BA_ "SystemSignalLongSymbol" SG_ 822 SEMMediaSourceAvail_Source09_ISi "SEMMediaSourceAvail_Source09_ISig_4";
BA_ "GenSigCycleTime" SG_ 822 SEMMediaSourceAvail_Source12_ISi 100;
BA_ "GenSigCycleTimeActive" SG_ 822 SEMMediaSourceAvail_Source12_ISi 100;
BA_ "Platform_VMCU1_Sig" SG_ 822 SEMMediaSourceAvail_Source12_ISi 1;
BA_ "SystemSignalLongSymbol" SG_ 822 SEMMediaSourceAvail_Source12_ISi "SEMMediaSourceAvail_Source12_ISig_4";
BA_ "GenSigCycleTime" SG_ 822 SEMMediaSourceAvail_Source07_ISi 100;
BA_ "GenSigCycleTimeActive" SG_ 822 SEMMediaSourceAvail_Source07_ISi 100;
BA_ "Platform_VMCU1_Sig" SG_ 822 SEMMediaSourceAvail_Source07_ISi 1;
BA_ "SystemSignalLongSymbol" SG_ 822 SEMMediaSourceAvail_Source07_ISi "SEMMediaSourceAvail_Source07_ISig_4";
BA_ "GenSigCycleTime" SG_ 822 SEMMediaSourceAvail_Source03_ISi 100;
BA_ "GenSigCycleTimeActive" SG_ 822 SEMMediaSourceAvail_Source03_ISi 100;
BA_ "Platform_VMCU1_Sig" SG_ 822 SEMMediaSourceAvail_Source03_ISi 1;
BA_ "SystemSignalLongSymbol" SG_ 822 SEMMediaSourceAvail_Source03_ISi "SEMMediaSourceAvail_Source03_ISig_4";
BA_ "GenSigCycleTime" SG_ 822 SEMMediaSourceAvail_Source11_ISi 100;
BA_ "GenSigCycleTimeActive" SG_ 822 SEMMediaSourceAvail_Source11_ISi 100;
BA_ "Platform_VMCU1_Sig" SG_ 822 SEMMediaSourceAvail_Source11_ISi 1;
BA_ "SystemSignalLongSymbol" SG_ 822 SEMMediaSourceAvail_Source11_ISi "SEMMediaSourceAvail_Source11_ISig_4";
BA_ "GenSigCycleTime" SG_ 822 SEM_AudioVolValIndCmd_ISig_4 100;
BA_ "GenSigCycleTimeActive" SG_ 822 SEM_AudioVolValIndCmd_ISig_4 100;
BA_ "Platform_VMCU1_Sig" SG_ 822 SEM_AudioVolValIndCmd_ISig_4 1;
BA_ "GenSigCycleTime" SG_ 822 SEMMediaSourceAvail_Source02_ISi 100;
BA_ "GenSigCycleTimeActive" SG_ 822 SEMMediaSourceAvail_Source02_ISi 100;
BA_ "Platform_VMCU1_Sig" SG_ 822 SEMMediaSourceAvail_Source02_ISi 1;
BA_ "SystemSignalLongSymbol" SG_ 822 SEMMediaSourceAvail_Source02_ISi "SEMMediaSourceAvail_Source02_ISig_4";
BA_ "GenSigCycleTime" SG_ 822 AudioSourceStat_ISig_4 100;
BA_ "GenSigCycleTimeActive" SG_ 822 AudioSourceStat_ISig_4 100;
BA_ "GenSigStartValue" SG_ 822 AudioSourceStat_ISig_4 15;
BA_ "Platform_VMCU1_Sig" SG_ 822 AudioSourceStat_ISig_4 1;
BA_ "GenSigCycleTime" SG_ 822 SEMMediaSourceAvail_Source06_ISi 100;
BA_ "GenSigCycleTimeActive" SG_ 822 SEMMediaSourceAvail_Source06_ISi 100;
BA_ "Platform_VMCU1_Sig" SG_ 822 SEMMediaSourceAvail_Source06_ISi 1;
BA_ "SystemSignalLongSymbol" SG_ 822 SEMMediaSourceAvail_Source06_ISi "SEMMediaSourceAvail_Source06_ISig_4";
BA_ "GenSigCycleTime" SG_ 822 SEMMediaSourceAvail_Source00_ISi 100;
BA_ "GenSigCycleTimeActive" SG_ 822 SEMMediaSourceAvail_Source00_ISi 100;
BA_ "Platform_VMCU1_Sig" SG_ 822 SEMMediaSourceAvail_Source00_ISi 1;
BA_ "SystemSignalLongSymbol" SG_ 822 SEMMediaSourceAvail_Source00_ISi "SEMMediaSourceAvail_Source00_ISig_4";
BA_ "GenSigCycleTime" SG_ 822 SEMMediaSourceAvail_Source01_ISi 100;
BA_ "GenSigCycleTimeActive" SG_ 822 SEMMediaSourceAvail_Source01_ISi 100;
BA_ "Platform_VMCU1_Sig" SG_ 822 SEMMediaSourceAvail_Source01_ISi 1;
BA_ "SystemSignalLongSymbol" SG_ 822 SEMMediaSourceAvail_Source01_ISi "SEMMediaSourceAvail_Source01_ISig_4";
BA_ "GenSigCycleTime" SG_ 822 SEMMediaSourceAvail_Source08_ISi 100;
BA_ "GenSigCycleTimeActive" SG_ 822 SEMMediaSourceAvail_Source08_ISi 100;
BA_ "Platform_VMCU1_Sig" SG_ 822 SEMMediaSourceAvail_Source08_ISi 1;
BA_ "SystemSignalLongSymbol" SG_ 822 SEMMediaSourceAvail_Source08_ISi "SEMMediaSourceAvail_Source08_ISig_4";
BA_ "GenSigCycleTime" SG_ 822 SEM_AudioMuteStat_ISig_4 100;
BA_ "GenSigCycleTimeActive" SG_ 822 SEM_AudioMuteStat_ISig_4 100;
BA_ "GenSigStartValue" SG_ 822 SEM_AudioMuteStat_ISig_4 7;
BA_ "Platform_VMCU1_Sig" SG_ 822 SEM_AudioMuteStat_ISig_4 1;
BA_ "GenSigCycleTime" SG_ 822 SEMMediaSourceAvail_Source13_ISi 100;
BA_ "GenSigCycleTimeActive" SG_ 822 SEMMediaSourceAvail_Source13_ISi 100;
BA_ "Platform_VMCU1_Sig" SG_ 822 SEMMediaSourceAvail_Source13_ISi 1;
BA_ "SystemSignalLongSymbol" SG_ 822 SEMMediaSourceAvail_Source13_ISi "SEMMediaSourceAvail_Source13_ISig_4";
BA_ "GenSigCycleTime" SG_ 822 SEMMediaSourceAvail_Source05_ISi 100;
BA_ "GenSigCycleTimeActive" SG_ 822 SEMMediaSourceAvail_Source05_ISi 100;
BA_ "Platform_VMCU1_Sig" SG_ 822 SEMMediaSourceAvail_Source05_ISi 1;
BA_ "SystemSignalLongSymbol" SG_ 822 SEMMediaSourceAvail_Source05_ISi "SEMMediaSourceAvail_Source05_ISig_4";
BA_ "GenSigSendType" SG_ 1337 TPMPosOfWMReq_sg_UB_ISig_4 7;
BA_ "GenSigCycleTime" SG_ 1337 TPMPosOfWMReq_sg_UB_ISig_4 100;
BA_ "GenSigCycleTimeActive" SG_ 1337 TPMPosOfWMReq_sg_UB_ISig_4 100;
BA_ "Platform_VMCU1_Sig" SG_ 1337 TPMPosOfWMReq_sg_UB_ISig_4 1;
BA_ "GenSigCycleTime" SG_ 1337 TPMUnmateTrailerReq_ISig_4 100;
BA_ "GenSigCycleTimeActive" SG_ 1337 TPMUnmateTrailerReq_ISig_4 100;
BA_ "GenSigStartValue" SG_ 1337 TPMUnmateTrailerReq_ISig_4 3;
BA_ "NeedsUpdateBit" SG_ 1337 TPMUnmateTrailerReq_ISig_4 1;
BA_ "Platform_VMCU1_Sig" SG_ 1337 TPMUnmateTrailerReq_ISig_4 1;
BA_ "GenSigCycleTime" SG_ 1337 TPMSetAxleRefPres_Axle4_ISig_4 100;
BA_ "GenSigCycleTimeActive" SG_ 1337 TPMSetAxleRefPres_Axle4_ISig_4 100;
BA_ "GenSigStartValue" SG_ 1337 TPMSetAxleRefPres_Axle4_ISig_4 255;
BA_ "NeedsUpdateBit" SG_ 1337 TPMSetAxleRefPres_Axle4_ISig_4 1;
BA_ "Platform_VMCU1_Sig" SG_ 1337 TPMSetAxleRefPres_Axle4_ISig_4 1;
BA_ "GenSigSendType" SG_ 1337 TPMMateTrailerReq_UB_ISig_4 7;
BA_ "GenSigCycleTime" SG_ 1337 TPMMateTrailerReq_UB_ISig_4 100;
BA_ "GenSigCycleTimeActive" SG_ 1337 TPMMateTrailerReq_UB_ISig_4 100;
BA_ "Platform_VMCU1_Sig" SG_ 1337 TPMMateTrailerReq_UB_ISig_4 1;
BA_ "GenSigSendType" SG_ 1337 TPMSetAxleRefPres_sg_UB_ISig_4 7;
BA_ "GenSigCycleTime" SG_ 1337 TPMSetAxleRefPres_sg_UB_ISig_4 100;
BA_ "GenSigCycleTimeActive" SG_ 1337 TPMSetAxleRefPres_sg_UB_ISig_4 100;
BA_ "Platform_VMCU1_Sig" SG_ 1337 TPMSetAxleRefPres_sg_UB_ISig_4 1;
BA_ "GenSigCycleTime" SG_ 1337 TPMPosOfWMReq_VehiclePos_ISig_4 100;
BA_ "GenSigCycleTimeActive" SG_ 1337 TPMPosOfWMReq_VehiclePos_ISig_4 100;
BA_ "GenSigStartValue" SG_ 1337 TPMPosOfWMReq_VehiclePos_ISig_4 7;
BA_ "NeedsUpdateBit" SG_ 1337 TPMPosOfWMReq_VehiclePos_ISig_4 1;
BA_ "Platform_VMCU1_Sig" SG_ 1337 TPMPosOfWMReq_VehiclePos_ISig_4 1;
BA_ "GenSigCycleTime" SG_ 1337 TPMSetAxleRefPres_Axle1_ISig_4 100;
BA_ "GenSigCycleTimeActive" SG_ 1337 TPMSetAxleRefPres_Axle1_ISig_4 100;
BA_ "GenSigStartValue" SG_ 1337 TPMSetAxleRefPres_Axle1_ISig_4 255;
BA_ "NeedsUpdateBit" SG_ 1337 TPMSetAxleRefPres_Axle1_ISig_4 1;
BA_ "Platform_VMCU1_Sig" SG_ 1337 TPMSetAxleRefPres_Axle1_ISig_4 1;
BA_ "GenSigCycleTime" SG_ 1337 TPMSetAxleRefPres_Axle2_ISig_4 100;
BA_ "GenSigCycleTimeActive" SG_ 1337 TPMSetAxleRefPres_Axle2_ISig_4 100;
BA_ "GenSigStartValue" SG_ 1337 TPMSetAxleRefPres_Axle2_ISig_4 255;
BA_ "NeedsUpdateBit" SG_ 1337 TPMSetAxleRefPres_Axle2_ISig_4 1;
BA_ "Platform_VMCU1_Sig" SG_ 1337 TPMSetAxleRefPres_Axle2_ISig_4 1;
BA_ "GenSigCycleTime" SG_ 1337 TPMSetAxleRefPres_Axle3_ISig_4 100;
BA_ "GenSigCycleTimeActive" SG_ 1337 TPMSetAxleRefPres_Axle3_ISig_4 100;
BA_ "GenSigStartValue" SG_ 1337 TPMSetAxleRefPres_Axle3_ISig_4 255;
BA_ "NeedsUpdateBit" SG_ 1337 TPMSetAxleRefPres_Axle3_ISig_4 1;
BA_ "Platform_VMCU1_Sig" SG_ 1337 TPMSetAxleRefPres_Axle3_ISig_4 1;
BA_ "GenSigCycleTime" SG_ 1337 TPMMateTrailerReq_ISig_4 100;
BA_ "GenSigCycleTimeActive" SG_ 1337 TPMMateTrailerReq_ISig_4 100;
BA_ "GenSigStartValue" SG_ 1337 TPMMateTrailerReq_ISig_4 3;
BA_ "NeedsUpdateBit" SG_ 1337 TPMMateTrailerReq_ISig_4 1;
BA_ "Platform_VMCU1_Sig" SG_ 1337 TPMMateTrailerReq_ISig_4 1;
BA_ "GenSigCycleTime" SG_ 1337 TPMPosOfWMReq_TireId_ISig_4 100;
BA_ "GenSigCycleTimeActive" SG_ 1337 TPMPosOfWMReq_TireId_ISig_4 100;
BA_ "NeedsUpdateBit" SG_ 1337 TPMPosOfWMReq_TireId_ISig_4 1;
BA_ "Platform_VMCU1_Sig" SG_ 1337 TPMPosOfWMReq_TireId_ISig_4 1;
BA_ "GenSigSendType" SG_ 1337 TPMUnmateTrailerReq_UB_ISig_4 7;
BA_ "GenSigCycleTime" SG_ 1337 TPMUnmateTrailerReq_UB_ISig_4 100;
BA_ "GenSigCycleTimeActive" SG_ 1337 TPMUnmateTrailerReq_UB_ISig_4 100;
BA_ "Platform_VMCU1_Sig" SG_ 1337 TPMUnmateTrailerReq_UB_ISig_4 1;
BA_ "GenSigCycleTime" SG_ 1337 TPMSetAxleRefPres_Axle5_ISig_4 100;
BA_ "GenSigCycleTimeActive" SG_ 1337 TPMSetAxleRefPres_Axle5_ISig_4 100;
BA_ "GenSigStartValue" SG_ 1337 TPMSetAxleRefPres_Axle5_ISig_4 255;
BA_ "NeedsUpdateBit" SG_ 1337 TPMSetAxleRefPres_Axle5_ISig_4 1;
BA_ "Platform_VMCU1_Sig" SG_ 1337 TPMSetAxleRefPres_Axle5_ISig_4 1;
BA_ "GenSigCycleTime" SG_ 1337 TPMSetAxleRefPres_VehiclePos_ISi 100;
BA_ "GenSigCycleTimeActive" SG_ 1337 TPMSetAxleRefPres_VehiclePos_ISi 100;
BA_ "GenSigStartValue" SG_ 1337 TPMSetAxleRefPres_VehiclePos_ISi 7;
BA_ "NeedsUpdateBit" SG_ 1337 TPMSetAxleRefPres_VehiclePos_ISi 1;
BA_ "Platform_VMCU1_Sig" SG_ 1337 TPMSetAxleRefPres_VehiclePos_ISi 1;
BA_ "SystemSignalLongSymbol" SG_ 1337 TPMSetAxleRefPres_VehiclePos_ISi "TPMSetAxleRefPres_VehiclePos_ISig_4";
BA_ "GenSigSendType" SG_ 1336 TPMSetPresThresCfg_sg_UB_ISig_4 7;
BA_ "GenSigCycleTime" SG_ 1336 TPMSetPresThresCfg_sg_UB_ISig_4 100;
BA_ "GenSigCycleTimeActive" SG_ 1336 TPMSetPresThresCfg_sg_UB_ISig_4 100;
BA_ "Platform_VMCU1_Sig" SG_ 1336 TPMSetPresThresCfg_sg_UB_ISig_4 1;
BA_ "GenSigCycleTime" SG_ 1336 TPMSetAxleTireConfig_Axle4_ISig_ 100;
BA_ "GenSigCycleTimeActive" SG_ 1336 TPMSetAxleTireConfig_Axle4_ISig_ 100;
BA_ "GenSigStartValue" SG_ 1336 TPMSetAxleTireConfig_Axle4_ISig_ 7;
BA_ "NeedsUpdateBit" SG_ 1336 TPMSetAxleTireConfig_Axle4_ISig_ 1;
BA_ "Platform_VMCU1_Sig" SG_ 1336 TPMSetAxleTireConfig_Axle4_ISig_ 1;
BA_ "SystemSignalLongSymbol" SG_ 1336 TPMSetAxleTireConfig_Axle4_ISig_ "TPMSetAxleTireConfig_Axle4_ISig_4";
BA_ "GenSigCycleTime" SG_ 1336 TPMSetAxleTireConfig_Axle5_ISig_ 100;
BA_ "GenSigCycleTimeActive" SG_ 1336 TPMSetAxleTireConfig_Axle5_ISig_ 100;
BA_ "GenSigStartValue" SG_ 1336 TPMSetAxleTireConfig_Axle5_ISig_ 7;
BA_ "NeedsUpdateBit" SG_ 1336 TPMSetAxleTireConfig_Axle5_ISig_ 1;
BA_ "Platform_VMCU1_Sig" SG_ 1336 TPMSetAxleTireConfig_Axle5_ISig_ 1;
BA_ "SystemSignalLongSymbol" SG_ 1336 TPMSetAxleTireConfig_Axle5_ISig_ "TPMSetAxleTireConfig_Axle5_ISig_4";
BA_ "GenSigCycleTime" SG_ 1336 TPMSetPresThresCfg_VehiclePos_IS 100;
BA_ "GenSigCycleTimeActive" SG_ 1336 TPMSetPresThresCfg_VehiclePos_IS 100;
BA_ "GenSigStartValue" SG_ 1336 TPMSetPresThresCfg_VehiclePos_IS 7;
BA_ "NeedsUpdateBit" SG_ 1336 TPMSetPresThresCfg_VehiclePos_IS 1;
BA_ "Platform_VMCU1_Sig" SG_ 1336 TPMSetPresThresCfg_VehiclePos_IS 1;
BA_ "SystemSignalLongSymbol" SG_ 1336 TPMSetPresThresCfg_VehiclePos_IS "TPMSetPresThresCfg_VehiclePos_ISig_4";
BA_ "GenSigCycleTime" SG_ 1336 TPMSetPresThresCfg_ExtOverPres_I 100;
BA_ "GenSigCycleTimeActive" SG_ 1336 TPMSetPresThresCfg_ExtOverPres_I 100;
BA_ "GenSigStartValue" SG_ 1336 TPMSetPresThresCfg_ExtOverPres_I 255;
BA_ "NeedsUpdateBit" SG_ 1336 TPMSetPresThresCfg_ExtOverPres_I 1;
BA_ "Platform_VMCU1_Sig" SG_ 1336 TPMSetPresThresCfg_ExtOverPres_I 1;
BA_ "SystemSignalLongSymbol" SG_ 1336 TPMSetPresThresCfg_ExtOverPres_I "TPMSetPresThresCfg_ExtOverPres_ISig_4";
BA_ "GenSigCycleTime" SG_ 1336 TPMSetAxleTireConfig_Axle2_ISig_ 100;
BA_ "GenSigCycleTimeActive" SG_ 1336 TPMSetAxleTireConfig_Axle2_ISig_ 100;
BA_ "GenSigStartValue" SG_ 1336 TPMSetAxleTireConfig_Axle2_ISig_ 7;
BA_ "NeedsUpdateBit" SG_ 1336 TPMSetAxleTireConfig_Axle2_ISig_ 1;
BA_ "Platform_VMCU1_Sig" SG_ 1336 TPMSetAxleTireConfig_Axle2_ISig_ 1;
BA_ "SystemSignalLongSymbol" SG_ 1336 TPMSetAxleTireConfig_Axle2_ISig_ "TPMSetAxleTireConfig_Axle2_ISig_4";
BA_ "GenSigCycleTime" SG_ 1336 TPMSetAxleTireConfig_VehiclePos_ 100;
BA_ "GenSigCycleTimeActive" SG_ 1336 TPMSetAxleTireConfig_VehiclePos_ 100;
BA_ "GenSigStartValue" SG_ 1336 TPMSetAxleTireConfig_VehiclePos_ 7;
BA_ "NeedsUpdateBit" SG_ 1336 TPMSetAxleTireConfig_VehiclePos_ 1;
BA_ "Platform_VMCU1_Sig" SG_ 1336 TPMSetAxleTireConfig_VehiclePos_ 1;
BA_ "SystemSignalLongSymbol" SG_ 1336 TPMSetAxleTireConfig_VehiclePos_ "TPMSetAxleTireConfig_VehiclePos_ISig_4";
BA_ "GenSigCycleTime" SG_ 1336 TPMSetAxleTireConfig_Axle3_ISig_ 100;
BA_ "GenSigCycleTimeActive" SG_ 1336 TPMSetAxleTireConfig_Axle3_ISig_ 100;
BA_ "GenSigStartValue" SG_ 1336 TPMSetAxleTireConfig_Axle3_ISig_ 7;
BA_ "NeedsUpdateBit" SG_ 1336 TPMSetAxleTireConfig_Axle3_ISig_ 1;
BA_ "Platform_VMCU1_Sig" SG_ 1336 TPMSetAxleTireConfig_Axle3_ISig_ 1;
BA_ "SystemSignalLongSymbol" SG_ 1336 TPMSetAxleTireConfig_Axle3_ISig_ "TPMSetAxleTireConfig_Axle3_ISig_4";
BA_ "GenSigCycleTime" SG_ 1336 TPMSetAxleTireConfig_Axle1_ISig_ 100;
BA_ "GenSigCycleTimeActive" SG_ 1336 TPMSetAxleTireConfig_Axle1_ISig_ 100;
BA_ "GenSigStartValue" SG_ 1336 TPMSetAxleTireConfig_Axle1_ISig_ 7;
BA_ "NeedsUpdateBit" SG_ 1336 TPMSetAxleTireConfig_Axle1_ISig_ 1;
BA_ "Platform_VMCU1_Sig" SG_ 1336 TPMSetAxleTireConfig_Axle1_ISig_ 1;
BA_ "SystemSignalLongSymbol" SG_ 1336 TPMSetAxleTireConfig_Axle1_ISig_ "TPMSetAxleTireConfig_Axle1_ISig_4";
BA_ "GenSigCycleTime" SG_ 1336 TPMSetPresThresCfg_AxleNr_ISig_4 100;
BA_ "GenSigCycleTimeActive" SG_ 1336 TPMSetPresThresCfg_AxleNr_ISig_4 100;
BA_ "GenSigStartValue" SG_ 1336 TPMSetPresThresCfg_AxleNr_ISig_4 7;
BA_ "NeedsUpdateBit" SG_ 1336 TPMSetPresThresCfg_AxleNr_ISig_4 1;
BA_ "Platform_VMCU1_Sig" SG_ 1336 TPMSetPresThresCfg_AxleNr_ISig_4 1;
BA_ "GenSigSendType" SG_ 1336 TPMSetAxleTireConfig_sg_UB_ISig_ 7;
BA_ "GenSigCycleTime" SG_ 1336 TPMSetAxleTireConfig_sg_UB_ISig_ 100;
BA_ "GenSigCycleTimeActive" SG_ 1336 TPMSetAxleTireConfig_sg_UB_ISig_ 100;
BA_ "Platform_VMCU1_Sig" SG_ 1336 TPMSetAxleTireConfig_sg_UB_ISig_ 1;
BA_ "SystemSignalLongSymbol" SG_ 1336 TPMSetAxleTireConfig_sg_UB_ISig_ "TPMSetAxleTireConfig_sg_UB_ISig_4";
BA_ "GenSigCycleTime" SG_ 1336 TPMSetPresThresCfg_OverPres_ISig 100;
BA_ "GenSigCycleTimeActive" SG_ 1336 TPMSetPresThresCfg_OverPres_ISig 100;
BA_ "GenSigStartValue" SG_ 1336 TPMSetPresThresCfg_OverPres_ISig 255;
BA_ "NeedsUpdateBit" SG_ 1336 TPMSetPresThresCfg_OverPres_ISig 1;
BA_ "Platform_VMCU1_Sig" SG_ 1336 TPMSetPresThresCfg_OverPres_ISig 1;
BA_ "SystemSignalLongSymbol" SG_ 1336 TPMSetPresThresCfg_OverPres_ISig "TPMSetPresThresCfg_OverPres_ISig_4";
BA_ "GenSigCycleTime" SG_ 1336 TPMSetPresThresCfg_ExtUnderPres_ 100;
BA_ "GenSigCycleTimeActive" SG_ 1336 TPMSetPresThresCfg_ExtUnderPres_ 100;
BA_ "GenSigStartValue" SG_ 1336 TPMSetPresThresCfg_ExtUnderPres_ 255;
BA_ "NeedsUpdateBit" SG_ 1336 TPMSetPresThresCfg_ExtUnderPres_ 1;
BA_ "Platform_VMCU1_Sig" SG_ 1336 TPMSetPresThresCfg_ExtUnderPres_ 1;
BA_ "SystemSignalLongSymbol" SG_ 1336 TPMSetPresThresCfg_ExtUnderPres_ "TPMSetPresThresCfg_ExtUnderPres_ISig_4";
BA_ "GenSigCycleTime" SG_ 1336 TPMSetPresThresCfg_UnderPres_ISi 100;
BA_ "GenSigCycleTimeActive" SG_ 1336 TPMSetPresThresCfg_UnderPres_ISi 100;
BA_ "GenSigStartValue" SG_ 1336 TPMSetPresThresCfg_UnderPres_ISi 255;
BA_ "NeedsUpdateBit" SG_ 1336 TPMSetPresThresCfg_UnderPres_ISi 1;
BA_ "Platform_VMCU1_Sig" SG_ 1336 TPMSetPresThresCfg_UnderPres_ISi 1;
BA_ "SystemSignalLongSymbol" SG_ 1336 TPMSetPresThresCfg_UnderPres_ISi "TPMSetPresThresCfg_UnderPres_ISig_4";
BA_ "GenSigSendType" SG_ 1476 HillDataPkgTGW_ISig_4 1;
BA_ "GenSigMaxLatency" SG_ 1476 HillDataPkgTGW_ISig_4 2500;
BA_ "Platform_VMCU1_Sig" SG_ 1476 HillDataPkgTGW_ISig_4 1;
BA_ "GenSigSendType" SG_ 1394 HMIIOM_BB2_27S_FCS 7;
BA_ "Platform_VMCU1_Sig" SG_ 1394 HMIIOM_BB2_27S_FCS 1;
BA_ "GenSigCycleTime" SG_ 837 TPMIndicationLightReq 100;
BA_ "GenSigCycleTimeActive" SG_ 837 TPMIndicationLightReq 100;
BA_ "GenSigStartValue" SG_ 837 TPMIndicationLightReq 3;
BA_ "GenSigSendType" SG_ 837 TPMIndicationLightReq_UB 7;
BA_ "GenSigCycleTime" SG_ 837 TPMIndicationLightReq_UB 100;
BA_ "GenSigCycleTimeActive" SG_ 837 TPMIndicationLightReq_UB 100;
BA_ "GenSigCycleTime" SG_ 837 Regeneration_DeviceInd 100;
BA_ "GenSigCycleTimeActive" SG_ 837 Regeneration_DeviceInd 100;
BA_ "GenSigStartValue" SG_ 837 Regeneration_DeviceInd 15;
BA_ "Platform_VMCU1_Sig" SG_ 837 Regeneration_DeviceInd 1;
BA_ "GenSigCycleTime" SG_ 1056 ExtraHeating_rqst_ISig_4 100;
BA_ "GenSigCycleTimeActive" SG_ 1056 ExtraHeating_rqst_ISig_4 100;
BA_ "GenSigStartValue" SG_ 1056 ExtraHeating_rqst_ISig_4 7;
BA_ "GenSigCycleTime" SG_ 1056 HillDataCtrlTGW_State_ISig_4 100;
BA_ "GenSigCycleTimeActive" SG_ 1056 HillDataCtrlTGW_State_ISig_4 100;
BA_ "GenSigStartValue" SG_ 1056 HillDataCtrlTGW_State_ISig_4 7;
BA_ "Platform_VMCU1_Sig" SG_ 1056 HillDataCtrlTGW_State_ISig_4 1;
BA_ "GenSigCycleTime" SG_ 1056 HillDataCtrlTGW_AckCnt_ISig_4 100;
BA_ "GenSigCycleTimeActive" SG_ 1056 HillDataCtrlTGW_AckCnt_ISig_4 100;
BA_ "Platform_VMCU1_Sig" SG_ 1056 HillDataCtrlTGW_AckCnt_ISig_4 1;
BA_ "GenSigCycleTime" SG_ 1334 BacklightLevelHighRes2_ISig_4 100;
BA_ "GenSigCycleTimeActive" SG_ 1334 BacklightLevelHighRes2_ISig_4 100;
BA_ "GenSigStartValue" SG_ 1334 BacklightLevelHighRes2_ISig_4 255;
BA_ "Platform_VMCU1_Sig" SG_ 1334 BacklightLevelHighRes2_ISig_4 1;
BA_ "GenSigCycleTime" SG_ 1334 MaintReset_rqst_Selection 100;
BA_ "GenSigCycleTimeActive" SG_ 1334 MaintReset_rqst_Selection 100;
BA_ "GenSigStartValue" SG_ 1334 MaintReset_rqst_Selection 15;
BA_ "Platform_VMCU1_Sig" SG_ 1334 MaintReset_rqst_Selection 1;
BA_ "GenSigCycleTime" SG_ 1334 MaintReset_rqst_Request 100;
BA_ "GenSigCycleTimeActive" SG_ 1334 MaintReset_rqst_Request 100;
BA_ "GenSigStartValue" SG_ 1334 MaintReset_rqst_Request 3;
BA_ "Platform_VMCU1_Sig" SG_ 1334 MaintReset_rqst_Request 1;
BA_ "GenSigSendType" SG_ 1334 DPF_ManualRegenerateInhibit 3;
BA_ "GenSigCycleTime" SG_ 1334 DPF_ManualRegenerateInhibit 100;
BA_ "GenSigCycleTimeActive" SG_ 1334 DPF_ManualRegenerateInhibit 100;
BA_ "GenSigStartValue" SG_ 1334 DPF_ManualRegenerateInhibit 3;
BA_ "Platform_VMCU1_Sig" SG_ 1334 DPF_ManualRegenerateInhibit 1;
BA_ "GenSigCycleTime" SG_ 1334 BlackPanel_stat_ISig_4 100;
BA_ "GenSigCycleTimeActive" SG_ 1334 BlackPanel_stat_ISig_4 100;
BA_ "GenSigStartValue" SG_ 1334 BlackPanel_stat_ISig_4 3;
BA_ "GenSigCycleTime" SG_ 1334 MaintReset_rqst_ID 100;
BA_ "GenSigCycleTimeActive" SG_ 1334 MaintReset_rqst_ID 100;
BA_ "GenSigStartValue" SG_ 1334 MaintReset_rqst_ID 63;
BA_ "Platform_VMCU1_Sig" SG_ 1334 MaintReset_rqst_ID 1;
BA_ "GenSigSendType" SG_ 1334 DPF_ManualRegenerateRequest 3;
BA_ "GenSigCycleTime" SG_ 1334 DPF_ManualRegenerateRequest 100;
BA_ "GenSigCycleTimeActive" SG_ 1334 DPF_ManualRegenerateRequest 100;
BA_ "GenSigStartValue" SG_ 1334 DPF_ManualRegenerateRequest 3;
BA_ "Platform_VMCU1_Sig" SG_ 1334 DPF_ManualRegenerateRequest 1;
BA_ "GenSigSendType" SG_ 1344 HMIIOM_BB2_20S_FCS 7;
BA_ "Platform_VMCU1_Sig" SG_ 1344 HMIIOM_BB2_20S_FCS 1;
BA_ "GenSigSendType" SG_ 1343 ECU3VIN_stat 1;
BA_ "GenSigMaxLatency" SG_ 1343 ECU3VIN_stat 137;
BA_ "Platform_VMCU1_Sig" SG_ 1343 ECU3VIN_stat 1;
BA_ "GenSigSendType" SG_ 1379 HMIIOM_BB2_19P_FCS_563 7;
BA_ "Platform_VMCU1_Sig" SG_ 1379 HMIIOM_BB2_19P_FCS_563 1;
BA_ "GenSigCycleTime" SG_ 1377 GPSData_Longitude_ISig_4_561 100;
BA_ "GenSigCycleTimeActive" SG_ 1377 GPSData_Longitude_ISig_4_561 100;
BA_ "GenSigStartValue" SG_ 1377 GPSData_Longitude_ISig_4_561 4294967295;
BA_ "GenSigMaxLatency" SG_ 1377 GPSData_Longitude_ISig_4_561 523;
BA_ "NeedsUpdateBit" SG_ 1377 GPSData_Longitude_ISig_4_561 1;
BA_ "Platform_VMCU1_Sig" SG_ 1377 GPSData_Longitude_ISig_4_561 1;
BA_ "GenSigSendType" SG_ 1377 GPSData_sg_UB_ISig_4_561 7;
BA_ "Platform_VMCU1_Sig" SG_ 1377 GPSData_sg_UB_ISig_4_561 1;
BA_ "GenSigCycleTime" SG_ 1377 GPSData_Direction_ISig_4_561 100;
BA_ "GenSigCycleTimeActive" SG_ 1377 GPSData_Direction_ISig_4_561 100;
BA_ "GenSigMaxLatency" SG_ 1377 GPSData_Direction_ISig_4_561 523;
BA_ "NeedsUpdateBit" SG_ 1377 GPSData_Direction_ISig_4_561 1;
BA_ "Platform_VMCU1_Sig" SG_ 1377 GPSData_Direction_ISig_4_561 1;
BA_ "GenSigCycleTime" SG_ 1377 GPSData_Latitude_ISig_4_561 100;
BA_ "GenSigCycleTimeActive" SG_ 1377 GPSData_Latitude_ISig_4_561 100;
BA_ "GenSigStartValue" SG_ 1377 GPSData_Latitude_ISig_4_561 4294967295;
BA_ "GenSigMaxLatency" SG_ 1377 GPSData_Latitude_ISig_4_561 523;
BA_ "NeedsUpdateBit" SG_ 1377 GPSData_Latitude_ISig_4_561 1;
BA_ "Platform_VMCU1_Sig" SG_ 1377 GPSData_Latitude_ISig_4_561 1;
BA_ "GenSigCycleTime" SG_ 1377 GPSData_Altitude_ISig_4_561 100;
BA_ "GenSigCycleTimeActive" SG_ 1377 GPSData_Altitude_ISig_4_561 100;
BA_ "GenSigStartValue" SG_ 1377 GPSData_Altitude_ISig_4_561 65535;
BA_ "GenSigMaxLatency" SG_ 1377 GPSData_Altitude_ISig_4_561 523;
BA_ "NeedsUpdateBit" SG_ 1377 GPSData_Altitude_ISig_4_561 1;
BA_ "Platform_VMCU1_Sig" SG_ 1377 GPSData_Altitude_ISig_4_561 1;
BA_ "GenSigCycleTime" SG_ 1377 GPSData_HDOP_ISig_4_561 100;
BA_ "GenSigCycleTimeActive" SG_ 1377 GPSData_HDOP_ISig_4_561 100;
BA_ "GenSigMaxLatency" SG_ 1377 GPSData_HDOP_ISig_4_561 523;
BA_ "NeedsUpdateBit" SG_ 1377 GPSData_HDOP_ISig_4_561 1;
BA_ "Platform_VMCU1_Sig" SG_ 1377 GPSData_HDOP_ISig_4_561 1;
BA_ "GenSigCycleTime" SG_ 1377 GPSData_Time_ISig_4_561 100;
BA_ "GenSigCycleTimeActive" SG_ 1377 GPSData_Time_ISig_4_561 100;
BA_ "GenSigStartValue" SG_ 1377 GPSData_Time_ISig_4_561 4294967295;
BA_ "GenSigMaxLatency" SG_ 1377 GPSData_Time_ISig_4_561 523;
BA_ "NeedsUpdateBit" SG_ 1377 GPSData_Time_ISig_4_561 1;
BA_ "Platform_VMCU1_Sig" SG_ 1377 GPSData_Time_ISig_4_561 1;
BA_ "GenSigCycleTime" SG_ 1377 GPSData_VehSpeed_ISig_4_561 100;
BA_ "GenSigCycleTimeActive" SG_ 1377 GPSData_VehSpeed_ISig_4_561 100;
BA_ "GenSigStartValue" SG_ 1377 GPSData_VehSpeed_ISig_4_561 65535;
BA_ "GenSigMaxLatency" SG_ 1377 GPSData_VehSpeed_ISig_4_561 523;
BA_ "NeedsUpdateBit" SG_ 1377 GPSData_VehSpeed_ISig_4_561 1;
BA_ "Platform_VMCU1_Sig" SG_ 1377 GPSData_VehSpeed_ISig_4_561 1;
BA_ "GenSigCycleTime" SG_ 1377 GPSData_AntennaStat_ISig_4_561 100;
BA_ "GenSigCycleTimeActive" SG_ 1377 GPSData_AntennaStat_ISig_4_561 100;
BA_ "GenSigStartValue" SG_ 1377 GPSData_AntennaStat_ISig_4_561 7;
BA_ "GenSigMaxLatency" SG_ 1377 GPSData_AntennaStat_ISig_4_561 523;
BA_ "NeedsUpdateBit" SG_ 1377 GPSData_AntennaStat_ISig_4_561 1;
BA_ "Platform_VMCU1_Sig" SG_ 1377 GPSData_AntennaStat_ISig_4_561 1;
BA_ "GenSigSendType" SG_ 1376 HMIIOM_BB2_19P_FCS_560 7;
BA_ "Platform_VMCU1_Sig" SG_ 1376 HMIIOM_BB2_19P_FCS_560 1;
BA_ "GenSigCycleTime" SG_ 1375 GPSData_HDOP_ISig_4_55f 100;
BA_ "GenSigCycleTimeActive" SG_ 1375 GPSData_HDOP_ISig_4_55f 100;
BA_ "GenSigMaxLatency" SG_ 1375 GPSData_HDOP_ISig_4_55f 523;
BA_ "NeedsUpdateBit" SG_ 1375 GPSData_HDOP_ISig_4_55f 1;
BA_ "Platform_VMCU1_Sig" SG_ 1375 GPSData_HDOP_ISig_4_55f 1;
BA_ "GenSigCycleTime" SG_ 1375 GPSData_VehSpeed_ISig_4_55f 100;
BA_ "GenSigCycleTimeActive" SG_ 1375 GPSData_VehSpeed_ISig_4_55f 100;
BA_ "GenSigStartValue" SG_ 1375 GPSData_VehSpeed_ISig_4_55f 65535;
BA_ "GenSigMaxLatency" SG_ 1375 GPSData_VehSpeed_ISig_4_55f 523;
BA_ "NeedsUpdateBit" SG_ 1375 GPSData_VehSpeed_ISig_4_55f 1;
BA_ "Platform_VMCU1_Sig" SG_ 1375 GPSData_VehSpeed_ISig_4_55f 1;
BA_ "GenSigCycleTime" SG_ 1375 GPSData_Direction_ISig_4_55f 100;
BA_ "GenSigCycleTimeActive" SG_ 1375 GPSData_Direction_ISig_4_55f 100;
BA_ "GenSigMaxLatency" SG_ 1375 GPSData_Direction_ISig_4_55f 523;
BA_ "NeedsUpdateBit" SG_ 1375 GPSData_Direction_ISig_4_55f 1;
BA_ "Platform_VMCU1_Sig" SG_ 1375 GPSData_Direction_ISig_4_55f 1;
BA_ "GenSigCycleTime" SG_ 1375 GPSData_Longitude_ISig_4_55f 100;
BA_ "GenSigCycleTimeActive" SG_ 1375 GPSData_Longitude_ISig_4_55f 100;
BA_ "GenSigStartValue" SG_ 1375 GPSData_Longitude_ISig_4_55f 4294967295;
BA_ "GenSigMaxLatency" SG_ 1375 GPSData_Longitude_ISig_4_55f 523;
BA_ "NeedsUpdateBit" SG_ 1375 GPSData_Longitude_ISig_4_55f 1;
BA_ "Platform_VMCU1_Sig" SG_ 1375 GPSData_Longitude_ISig_4_55f 1;
BA_ "GenSigSendType" SG_ 1375 GPSData_sg_UB_ISig_4_55f 7;
BA_ "Platform_VMCU1_Sig" SG_ 1375 GPSData_sg_UB_ISig_4_55f 1;
BA_ "GenSigCycleTime" SG_ 1375 GPSData_Time_ISig_4_55f 100;
BA_ "GenSigCycleTimeActive" SG_ 1375 GPSData_Time_ISig_4_55f 100;
BA_ "GenSigStartValue" SG_ 1375 GPSData_Time_ISig_4_55f 4294967295;
BA_ "GenSigMaxLatency" SG_ 1375 GPSData_Time_ISig_4_55f 523;
BA_ "NeedsUpdateBit" SG_ 1375 GPSData_Time_ISig_4_55f 1;
BA_ "Platform_VMCU1_Sig" SG_ 1375 GPSData_Time_ISig_4_55f 1;
BA_ "GenSigCycleTime" SG_ 1375 GPSData_Latitude_ISig_4_55f 100;
BA_ "GenSigCycleTimeActive" SG_ 1375 GPSData_Latitude_ISig_4_55f 100;
BA_ "GenSigStartValue" SG_ 1375 GPSData_Latitude_ISig_4_55f 4294967295;
BA_ "GenSigMaxLatency" SG_ 1375 GPSData_Latitude_ISig_4_55f 523;
BA_ "NeedsUpdateBit" SG_ 1375 GPSData_Latitude_ISig_4_55f 1;
BA_ "Platform_VMCU1_Sig" SG_ 1375 GPSData_Latitude_ISig_4_55f 1;
BA_ "GenSigCycleTime" SG_ 1375 GPSData_AntennaStat_ISig_4_55f 100;
BA_ "GenSigCycleTimeActive" SG_ 1375 GPSData_AntennaStat_ISig_4_55f 100;
BA_ "GenSigStartValue" SG_ 1375 GPSData_AntennaStat_ISig_4_55f 7;
BA_ "GenSigMaxLatency" SG_ 1375 GPSData_AntennaStat_ISig_4_55f 523;
BA_ "NeedsUpdateBit" SG_ 1375 GPSData_AntennaStat_ISig_4_55f 1;
BA_ "Platform_VMCU1_Sig" SG_ 1375 GPSData_AntennaStat_ISig_4_55f 1;
BA_ "GenSigCycleTime" SG_ 1375 GPSData_Altitude_ISig_4_55f 100;
BA_ "GenSigCycleTimeActive" SG_ 1375 GPSData_Altitude_ISig_4_55f 100;
BA_ "GenSigStartValue" SG_ 1375 GPSData_Altitude_ISig_4_55f 65535;
BA_ "GenSigMaxLatency" SG_ 1375 GPSData_Altitude_ISig_4_55f 523;
BA_ "NeedsUpdateBit" SG_ 1375 GPSData_Altitude_ISig_4_55f 1;
BA_ "Platform_VMCU1_Sig" SG_ 1375 GPSData_Altitude_ISig_4_55f 1;
BA_ "GenSigSendType" SG_ 1382 HMIIOM_BB2_19P_FCS_566 7;
BA_ "Platform_VMCU1_Sig" SG_ 1382 HMIIOM_BB2_19P_FCS_566 1;
BA_ "GenSigCycleTime" SG_ 1381 GPSData_HDOP_ISig_4_565 100;
BA_ "GenSigCycleTimeActive" SG_ 1381 GPSData_HDOP_ISig_4_565 100;
BA_ "GenSigMaxLatency" SG_ 1381 GPSData_HDOP_ISig_4_565 523;
BA_ "NeedsUpdateBit" SG_ 1381 GPSData_HDOP_ISig_4_565 1;
BA_ "Platform_VMCU1_Sig" SG_ 1381 GPSData_HDOP_ISig_4_565 1;
BA_ "GenSigCycleTime" SG_ 1381 GPSData_VehSpeed_ISig_4_565 100;
BA_ "GenSigCycleTimeActive" SG_ 1381 GPSData_VehSpeed_ISig_4_565 100;
BA_ "GenSigStartValue" SG_ 1381 GPSData_VehSpeed_ISig_4_565 65535;
BA_ "GenSigMaxLatency" SG_ 1381 GPSData_VehSpeed_ISig_4_565 523;
BA_ "NeedsUpdateBit" SG_ 1381 GPSData_VehSpeed_ISig_4_565 1;
BA_ "Platform_VMCU1_Sig" SG_ 1381 GPSData_VehSpeed_ISig_4_565 1;
BA_ "GenSigSendType" SG_ 1381 GPSData_sg_UB_ISig_4_565 7;
BA_ "Platform_VMCU1_Sig" SG_ 1381 GPSData_sg_UB_ISig_4_565 1;
BA_ "GenSigCycleTime" SG_ 1381 GPSData_AntennaStat_ISig_4_565 100;
BA_ "GenSigCycleTimeActive" SG_ 1381 GPSData_AntennaStat_ISig_4_565 100;
BA_ "GenSigStartValue" SG_ 1381 GPSData_AntennaStat_ISig_4_565 7;
BA_ "GenSigMaxLatency" SG_ 1381 GPSData_AntennaStat_ISig_4_565 523;
BA_ "NeedsUpdateBit" SG_ 1381 GPSData_AntennaStat_ISig_4_565 1;
BA_ "Platform_VMCU1_Sig" SG_ 1381 GPSData_AntennaStat_ISig_4_565 1;
BA_ "GenSigCycleTime" SG_ 1381 GPSData_Latitude_ISig_4_565 100;
BA_ "GenSigCycleTimeActive" SG_ 1381 GPSData_Latitude_ISig_4_565 100;
BA_ "GenSigStartValue" SG_ 1381 GPSData_Latitude_ISig_4_565 4294967295;
BA_ "GenSigMaxLatency" SG_ 1381 GPSData_Latitude_ISig_4_565 523;
BA_ "NeedsUpdateBit" SG_ 1381 GPSData_Latitude_ISig_4_565 1;
BA_ "Platform_VMCU1_Sig" SG_ 1381 GPSData_Latitude_ISig_4_565 1;
BA_ "GenSigCycleTime" SG_ 1381 GPSData_Time_ISig_4_565 100;
BA_ "GenSigCycleTimeActive" SG_ 1381 GPSData_Time_ISig_4_565 100;
BA_ "GenSigStartValue" SG_ 1381 GPSData_Time_ISig_4_565 4294967295;
BA_ "GenSigMaxLatency" SG_ 1381 GPSData_Time_ISig_4_565 523;
BA_ "NeedsUpdateBit" SG_ 1381 GPSData_Time_ISig_4_565 1;
BA_ "Platform_VMCU1_Sig" SG_ 1381 GPSData_Time_ISig_4_565 1;
BA_ "GenSigCycleTime" SG_ 1381 GPSData_Direction_ISig_4_565 100;
BA_ "GenSigCycleTimeActive" SG_ 1381 GPSData_Direction_ISig_4_565 100;
BA_ "GenSigMaxLatency" SG_ 1381 GPSData_Direction_ISig_4_565 523;
BA_ "NeedsUpdateBit" SG_ 1381 GPSData_Direction_ISig_4_565 1;
BA_ "Platform_VMCU1_Sig" SG_ 1381 GPSData_Direction_ISig_4_565 1;
BA_ "GenSigCycleTime" SG_ 1381 GPSData_Longitude_ISig_4_565 100;
BA_ "GenSigCycleTimeActive" SG_ 1381 GPSData_Longitude_ISig_4_565 100;
BA_ "GenSigStartValue" SG_ 1381 GPSData_Longitude_ISig_4_565 4294967295;
BA_ "GenSigMaxLatency" SG_ 1381 GPSData_Longitude_ISig_4_565 523;
BA_ "NeedsUpdateBit" SG_ 1381 GPSData_Longitude_ISig_4_565 1;
BA_ "Platform_VMCU1_Sig" SG_ 1381 GPSData_Longitude_ISig_4_565 1;
BA_ "GenSigCycleTime" SG_ 1381 GPSData_Altitude_ISig_4_565 100;
BA_ "GenSigCycleTimeActive" SG_ 1381 GPSData_Altitude_ISig_4_565 100;
BA_ "GenSigStartValue" SG_ 1381 GPSData_Altitude_ISig_4_565 65535;
BA_ "GenSigMaxLatency" SG_ 1381 GPSData_Altitude_ISig_4_565 523;
BA_ "NeedsUpdateBit" SG_ 1381 GPSData_Altitude_ISig_4_565 1;
BA_ "Platform_VMCU1_Sig" SG_ 1381 GPSData_Altitude_ISig_4_565 1;
BA_ "GenSigSendType" SG_ 1387 HMIIOM_BB2_19P_FCS_56b 7;
BA_ "Platform_VMCU1_Sig" SG_ 1387 HMIIOM_BB2_19P_FCS_56b 1;
BA_ "GenSigCycleTime" SG_ 1386 GPSData_HDOP_ISig_4_56a 100;
BA_ "GenSigCycleTimeActive" SG_ 1386 GPSData_HDOP_ISig_4_56a 100;
BA_ "GenSigMaxLatency" SG_ 1386 GPSData_HDOP_ISig_4_56a 523;
BA_ "NeedsUpdateBit" SG_ 1386 GPSData_HDOP_ISig_4_56a 1;
BA_ "Platform_VMCU1_Sig" SG_ 1386 GPSData_HDOP_ISig_4_56a 1;
BA_ "GenSigCycleTime" SG_ 1386 GPSData_Latitude_ISig_4_56a 100;
BA_ "GenSigCycleTimeActive" SG_ 1386 GPSData_Latitude_ISig_4_56a 100;
BA_ "GenSigStartValue" SG_ 1386 GPSData_Latitude_ISig_4_56a 4294967295;
BA_ "GenSigMaxLatency" SG_ 1386 GPSData_Latitude_ISig_4_56a 523;
BA_ "NeedsUpdateBit" SG_ 1386 GPSData_Latitude_ISig_4_56a 1;
BA_ "Platform_VMCU1_Sig" SG_ 1386 GPSData_Latitude_ISig_4_56a 1;
BA_ "GenSigCycleTime" SG_ 1386 GPSData_Time_ISig_4_56a 100;
BA_ "GenSigCycleTimeActive" SG_ 1386 GPSData_Time_ISig_4_56a 100;
BA_ "GenSigStartValue" SG_ 1386 GPSData_Time_ISig_4_56a 4294967295;
BA_ "GenSigMaxLatency" SG_ 1386 GPSData_Time_ISig_4_56a 523;
BA_ "NeedsUpdateBit" SG_ 1386 GPSData_Time_ISig_4_56a 1;
BA_ "Platform_VMCU1_Sig" SG_ 1386 GPSData_Time_ISig_4_56a 1;
BA_ "GenSigCycleTime" SG_ 1386 GPSData_Direction_ISig_4_56a 100;
BA_ "GenSigCycleTimeActive" SG_ 1386 GPSData_Direction_ISig_4_56a 100;
BA_ "GenSigMaxLatency" SG_ 1386 GPSData_Direction_ISig_4_56a 523;
BA_ "NeedsUpdateBit" SG_ 1386 GPSData_Direction_ISig_4_56a 1;
BA_ "Platform_VMCU1_Sig" SG_ 1386 GPSData_Direction_ISig_4_56a 1;
BA_ "GenSigSendType" SG_ 1386 GPSData_sg_UB_ISig_4_56a 7;
BA_ "Platform_VMCU1_Sig" SG_ 1386 GPSData_sg_UB_ISig_4_56a 1;
BA_ "GenSigCycleTime" SG_ 1386 GPSData_AntennaStat_ISig_4_56a 100;
BA_ "GenSigCycleTimeActive" SG_ 1386 GPSData_AntennaStat_ISig_4_56a 100;
BA_ "GenSigStartValue" SG_ 1386 GPSData_AntennaStat_ISig_4_56a 7;
BA_ "GenSigMaxLatency" SG_ 1386 GPSData_AntennaStat_ISig_4_56a 523;
BA_ "NeedsUpdateBit" SG_ 1386 GPSData_AntennaStat_ISig_4_56a 1;
BA_ "Platform_VMCU1_Sig" SG_ 1386 GPSData_AntennaStat_ISig_4_56a 1;
BA_ "GenSigCycleTime" SG_ 1386 GPSData_Longitude_ISig_4_56a 100;
BA_ "GenSigCycleTimeActive" SG_ 1386 GPSData_Longitude_ISig_4_56a 100;
BA_ "GenSigStartValue" SG_ 1386 GPSData_Longitude_ISig_4_56a 4294967295;
BA_ "GenSigMaxLatency" SG_ 1386 GPSData_Longitude_ISig_4_56a 523;
BA_ "NeedsUpdateBit" SG_ 1386 GPSData_Longitude_ISig_4_56a 1;
BA_ "Platform_VMCU1_Sig" SG_ 1386 GPSData_Longitude_ISig_4_56a 1;
BA_ "GenSigCycleTime" SG_ 1386 GPSData_VehSpeed_ISig_4_56a 100;
BA_ "GenSigCycleTimeActive" SG_ 1386 GPSData_VehSpeed_ISig_4_56a 100;
BA_ "GenSigStartValue" SG_ 1386 GPSData_VehSpeed_ISig_4_56a 65535;
BA_ "GenSigMaxLatency" SG_ 1386 GPSData_VehSpeed_ISig_4_56a 523;
BA_ "NeedsUpdateBit" SG_ 1386 GPSData_VehSpeed_ISig_4_56a 1;
BA_ "Platform_VMCU1_Sig" SG_ 1386 GPSData_VehSpeed_ISig_4_56a 1;
BA_ "GenSigCycleTime" SG_ 1386 GPSData_Altitude_ISig_4_56a 100;
BA_ "GenSigCycleTimeActive" SG_ 1386 GPSData_Altitude_ISig_4_56a 100;
BA_ "GenSigStartValue" SG_ 1386 GPSData_Altitude_ISig_4_56a 65535;
BA_ "GenSigMaxLatency" SG_ 1386 GPSData_Altitude_ISig_4_56a 523;
BA_ "NeedsUpdateBit" SG_ 1386 GPSData_Altitude_ISig_4_56a 1;
BA_ "Platform_VMCU1_Sig" SG_ 1386 GPSData_Altitude_ISig_4_56a 1;
BA_ "GenSigSendType" SG_ 1385 HMIIOM_BB2_19P_FCS_569 7;
BA_ "Platform_VMCU1_Sig" SG_ 1385 HMIIOM_BB2_19P_FCS_569 1;
BA_ "GenSigCycleTime" SG_ 1384 GPSData_Time_ISig_4_568 100;
BA_ "GenSigCycleTimeActive" SG_ 1384 GPSData_Time_ISig_4_568 100;
BA_ "GenSigStartValue" SG_ 1384 GPSData_Time_ISig_4_568 4294967295;
BA_ "GenSigMaxLatency" SG_ 1384 GPSData_Time_ISig_4_568 523;
BA_ "NeedsUpdateBit" SG_ 1384 GPSData_Time_ISig_4_568 1;
BA_ "Platform_VMCU1_Sig" SG_ 1384 GPSData_Time_ISig_4_568 1;
BA_ "GenSigCycleTime" SG_ 1384 GPSData_HDOP_ISig_4_568 100;
BA_ "GenSigCycleTimeActive" SG_ 1384 GPSData_HDOP_ISig_4_568 100;
BA_ "GenSigMaxLatency" SG_ 1384 GPSData_HDOP_ISig_4_568 523;
BA_ "NeedsUpdateBit" SG_ 1384 GPSData_HDOP_ISig_4_568 1;
BA_ "Platform_VMCU1_Sig" SG_ 1384 GPSData_HDOP_ISig_4_568 1;
BA_ "GenSigCycleTime" SG_ 1384 GPSData_Direction_ISig_4_568 100;
BA_ "GenSigCycleTimeActive" SG_ 1384 GPSData_Direction_ISig_4_568 100;
BA_ "GenSigMaxLatency" SG_ 1384 GPSData_Direction_ISig_4_568 523;
BA_ "NeedsUpdateBit" SG_ 1384 GPSData_Direction_ISig_4_568 1;
BA_ "Platform_VMCU1_Sig" SG_ 1384 GPSData_Direction_ISig_4_568 1;
BA_ "GenSigCycleTime" SG_ 1384 GPSData_Longitude_ISig_4_568 100;
BA_ "GenSigCycleTimeActive" SG_ 1384 GPSData_Longitude_ISig_4_568 100;
BA_ "GenSigStartValue" SG_ 1384 GPSData_Longitude_ISig_4_568 4294967295;
BA_ "GenSigMaxLatency" SG_ 1384 GPSData_Longitude_ISig_4_568 523;
BA_ "NeedsUpdateBit" SG_ 1384 GPSData_Longitude_ISig_4_568 1;
BA_ "Platform_VMCU1_Sig" SG_ 1384 GPSData_Longitude_ISig_4_568 1;
BA_ "GenSigSendType" SG_ 1384 GPSData_sg_UB_ISig_4_568 7;
BA_ "Platform_VMCU1_Sig" SG_ 1384 GPSData_sg_UB_ISig_4_568 1;
BA_ "GenSigCycleTime" SG_ 1384 GPSData_VehSpeed_ISig_4_568 100;
BA_ "GenSigCycleTimeActive" SG_ 1384 GPSData_VehSpeed_ISig_4_568 100;
BA_ "GenSigStartValue" SG_ 1384 GPSData_VehSpeed_ISig_4_568 65535;
BA_ "GenSigMaxLatency" SG_ 1384 GPSData_VehSpeed_ISig_4_568 523;
BA_ "NeedsUpdateBit" SG_ 1384 GPSData_VehSpeed_ISig_4_568 1;
BA_ "Platform_VMCU1_Sig" SG_ 1384 GPSData_VehSpeed_ISig_4_568 1;
BA_ "GenSigCycleTime" SG_ 1384 GPSData_Altitude_ISig_4_568 100;
BA_ "GenSigCycleTimeActive" SG_ 1384 GPSData_Altitude_ISig_4_568 100;
BA_ "GenSigStartValue" SG_ 1384 GPSData_Altitude_ISig_4_568 65535;
BA_ "GenSigMaxLatency" SG_ 1384 GPSData_Altitude_ISig_4_568 523;
BA_ "NeedsUpdateBit" SG_ 1384 GPSData_Altitude_ISig_4_568 1;
BA_ "Platform_VMCU1_Sig" SG_ 1384 GPSData_Altitude_ISig_4_568 1;
BA_ "GenSigCycleTime" SG_ 1384 GPSData_Latitude_ISig_4_568 100;
BA_ "GenSigCycleTimeActive" SG_ 1384 GPSData_Latitude_ISig_4_568 100;
BA_ "GenSigStartValue" SG_ 1384 GPSData_Latitude_ISig_4_568 4294967295;
BA_ "GenSigMaxLatency" SG_ 1384 GPSData_Latitude_ISig_4_568 523;
BA_ "NeedsUpdateBit" SG_ 1384 GPSData_Latitude_ISig_4_568 1;
BA_ "Platform_VMCU1_Sig" SG_ 1384 GPSData_Latitude_ISig_4_568 1;
BA_ "GenSigCycleTime" SG_ 1384 GPSData_AntennaStat_ISig_4_568 100;
BA_ "GenSigCycleTimeActive" SG_ 1384 GPSData_AntennaStat_ISig_4_568 100;
BA_ "GenSigStartValue" SG_ 1384 GPSData_AntennaStat_ISig_4_568 7;
BA_ "GenSigMaxLatency" SG_ 1384 GPSData_AntennaStat_ISig_4_568 523;
BA_ "NeedsUpdateBit" SG_ 1384 GPSData_AntennaStat_ISig_4_568 1;
BA_ "Platform_VMCU1_Sig" SG_ 1384 GPSData_AntennaStat_ISig_4_568 1;
BA_ "GenSigCycleTime" SG_ 979 PinCodeEntered_value 100;
BA_ "GenSigCycleTimeActive" SG_ 979 PinCodeEntered_value 100;
BA_ "GenSigMaxLatency" SG_ 979 PinCodeEntered_value 89;
BA_ "Platform_VMCU1_Sig" SG_ 979 PinCodeEntered_value 1;
BA_ "GenSigCycleTime" SG_ 979 DynamicCode_rqst 100;
BA_ "GenSigCycleTimeActive" SG_ 979 DynamicCode_rqst 100;
BA_ "GenSigStartValue" SG_ 979 DynamicCode_rqst 7;
BA_ "GenSigMaxLatency" SG_ 979 DynamicCode_rqst 26;
BA_ "Platform_VMCU1_Sig" SG_ 979 DynamicCode_rqst 1;
BA_ "GenSigCycleTime" SG_ 979 LogDisplayedMessage_req 100;
BA_ "GenSigCycleTimeActive" SG_ 979 LogDisplayedMessage_req 100;
BA_ "GenSigMaxLatency" SG_ 979 LogDisplayedMessage_req 89;
BA_ "NeedsUpdateBit" SG_ 979 LogDisplayedMessage_req 1;
BA_ "Platform_VMCU1_Sig" SG_ 979 LogDisplayedMessage_req 1;
BA_ "GenSigSendType" SG_ 979 LogDisplayedMessage_req_UB 7;
BA_ "Platform_VMCU1_Sig" SG_ 979 LogDisplayedMessage_req_UB 1;
BA_ "GenSigCycleTime" SG_ 970 FirstAxleLowerPrioRequested_ISig 100;
BA_ "GenSigCycleTimeActive" SG_ 970 FirstAxleLowerPrioRequested_ISig 100;
BA_ "GenSigStartValue" SG_ 970 FirstAxleLowerPrioRequested_ISig 7;
BA_ "NeedsUpdateBit" SG_ 970 FirstAxleLowerPrioRequested_ISig 1;
BA_ "SystemSignalLongSymbol" SG_ 970 FirstAxleLowerPrioRequested_ISig "FirstAxleLowerPrioRequested_ISig_4";
BA_ "GenSigCycleTime" SG_ 970 Synch_Unsynch_Mode_stat 100;
BA_ "GenSigCycleTimeActive" SG_ 970 Synch_Unsynch_Mode_stat 100;
BA_ "GenSigStartValue" SG_ 970 Synch_Unsynch_Mode_stat 7;
BA_ "GenSigMaxLatency" SG_ 970 Synch_Unsynch_Mode_stat 89;
BA_ "Platform_VMCU1_Sig" SG_ 970 Synch_Unsynch_Mode_stat 1;
BA_ "GenSigCycleTime" SG_ 970 SelectedSpeedUnit_stat_ISig_4 100;
BA_ "GenSigCycleTimeActive" SG_ 970 SelectedSpeedUnit_stat_ISig_4 100;
BA_ "GenSigStartValue" SG_ 970 SelectedSpeedUnit_stat_ISig_4 3;
BA_ "GenSigMaxLatency" SG_ 970 SelectedSpeedUnit_stat_ISig_4 89;
BA_ "Platform_VMCU1_Sig" SG_ 970 SelectedSpeedUnit_stat_ISig_4 1;
BA_ "GenSigCycleTime" SG_ 970 SelectedLanguage_stat_ISig_4 100;
BA_ "GenSigCycleTimeActive" SG_ 970 SelectedLanguage_stat_ISig_4 100;
BA_ "GenSigStartValue" SG_ 970 SelectedLanguage_stat_ISig_4 63;
BA_ "GenSigMaxLatency" SG_ 970 SelectedLanguage_stat_ISig_4 89;
BA_ "Platform_VMCU1_Sig" SG_ 970 SelectedLanguage_stat_ISig_4 1;
BA_ "GenSigCycleTime" SG_ 970 LampCheck_rqst_ISig_4 100;
BA_ "GenSigCycleTimeActive" SG_ 970 LampCheck_rqst_ISig_4 100;
BA_ "GenSigStartValue" SG_ 970 LampCheck_rqst_ISig_4 3;
BA_ "Platform_VMCU1_Sig" SG_ 970 LampCheck_rqst_ISig_4 1;
BA_ "GenSigCycleTime" SG_ 970 SelectedWeightUnit_stat_ISig_4 100;
BA_ "GenSigCycleTimeActive" SG_ 970 SelectedWeightUnit_stat_ISig_4 100;
BA_ "GenSigStartValue" SG_ 970 SelectedWeightUnit_stat_ISig_4 3;
BA_ "Platform_VMCU1_Sig" SG_ 970 SelectedWeightUnit_stat_ISig_4 1;
BA_ "GenSigSendType" SG_ 970 FirstAxleLowerPrioRequested_UB_I 7;
BA_ "SystemSignalLongSymbol" SG_ 970 FirstAxleLowerPrioRequested_UB_I "FirstAxleLowerPrioRequested_UB_ISig_4";
BA_ "GenSigCycleTime" SG_ 970 SpeedLockingInhibition_stat 100;
BA_ "GenSigCycleTimeActive" SG_ 970 SpeedLockingInhibition_stat 100;
BA_ "GenSigStartValue" SG_ 970 SpeedLockingInhibition_stat 7;
BA_ "GenSigMaxLatency" SG_ 970 SpeedLockingInhibition_stat 89;
BA_ "Platform_VMCU1_Sig" SG_ 970 SpeedLockingInhibition_stat 1;
BA_ "GenSigCycleTime" SG_ 970 DriverMemory_rqst_ISig_4 100;
BA_ "GenSigCycleTimeActive" SG_ 970 DriverMemory_rqst_ISig_4 100;
BA_ "GenSigStartValue" SG_ 970 DriverMemory_rqst_ISig_4 31;
BA_ "Platform_VMCU1_Sig" SG_ 970 DriverMemory_rqst_ISig_4 1;
BA_ "GenSigCycleTime" SG_ 970 SelectedTimeFormat_stat_ISig_4 100;
BA_ "GenSigCycleTimeActive" SG_ 970 SelectedTimeFormat_stat_ISig_4 100;
BA_ "GenSigStartValue" SG_ 970 SelectedTimeFormat_stat_ISig_4 3;
BA_ "Platform_VMCU1_Sig" SG_ 970 SelectedTimeFormat_stat_ISig_4 1;
BA_ "GenSigCycleTime" SG_ 970 MaintInfo_rqst 100;
BA_ "GenSigCycleTimeActive" SG_ 970 MaintInfo_rqst 100;
BA_ "GenSigStartValue" SG_ 970 MaintInfo_rqst 3;
BA_ "GenSigCycleTime" SG_ 970 LCSSoundSettingRequest 100;
BA_ "GenSigCycleTimeActive" SG_ 970 LCSSoundSettingRequest 100;
BA_ "GenSigStartValue" SG_ 970 LCSSoundSettingRequest 3;
BA_ "Platform_VMCU1_Sig" SG_ 970 LCSSoundSettingRequest 1;
BA_ "GenSigCycleTime" SG_ 851 BunkBacklightCmd_ISig_4 100;
BA_ "GenSigCycleTimeActive" SG_ 851 BunkBacklightCmd_ISig_4 100;
BA_ "GenSigMaxLatency" SG_ 851 BunkBacklightCmd_ISig_4 71;
BA_ "Platform_VMCU1_Sig" SG_ 851 BunkBacklightCmd_ISig_4 1;
BA_ "GenSigCycleTime" SG_ 1270 CabLightIntensity_stat_ISig_4 100;
BA_ "GenSigCycleTimeActive" SG_ 1270 CabLightIntensity_stat_ISig_4 100;
BA_ "GenSigStartValue" SG_ 1270 CabLightIntensity_stat_ISig_4 255;
BA_ "GenSigMaxLatency" SG_ 1270 CabLightIntensity_stat_ISig_4 56;
BA_ "Platform_VMCU1_Sig" SG_ 1270 CabLightIntensity_stat_ISig_4 1;
BA_ "SeToolAncestorID_SIGNAL" SG_ 1270 CabLightIntensity_stat_ISig_4 "x0000001D041AFE81";
BA_ "SeToolItemID_SIGNAL" SG_ 1270 CabLightIntensity_stat_ISig_4 "x0000001D0433F018";
BA_ "SeToolName_SIGNAL" SG_ 1270 CabLightIntensity_stat_ISig_4 "LightSensor_Data";
BA_ "SeToolVersion_SIGNAL" SG_ 1270 CabLightIntensity_stat_ISig_4 "2";
BA_ "GenSigCycleTime" SG_ 739 CCBOverspeedRequest 100;
BA_ "GenSigCycleTimeActive" SG_ 739 CCBOverspeedRequest 100;
BA_ "GenSigStartValue" SG_ 739 CCBOverspeedRequest 65535;
BA_ "GenSigMaxLatency" SG_ 739 CCBOverspeedRequest 41;
BA_ "Platform_VMCU1_Sig" SG_ 739 CCBOverspeedRequest 1;
BA_ "GenSigCycleTime" SG_ 739 ASLDriverRequest 100;
BA_ "GenSigCycleTimeActive" SG_ 739 ASLDriverRequest 100;
BA_ "GenSigStartValue" SG_ 739 ASLDriverRequest 15;
BA_ "GenSigMaxLatency" SG_ 739 ASLDriverRequest 41;
BA_ "Platform_VMCU1_Sig" SG_ 739 ASLDriverRequest 1;
BA_ "GenSigCycleTime" SG_ 739 ASLEnableRequest 100;
BA_ "GenSigCycleTimeActive" SG_ 739 ASLEnableRequest 100;
BA_ "GenSigStartValue" SG_ 739 ASLEnableRequest 3;
BA_ "GenSigMaxLatency" SG_ 739 ASLEnableRequest 41;
BA_ "Platform_VMCU1_Sig" SG_ 739 ASLEnableRequest 1;
BA_ "GenSigCycleTime" SG_ 739 CCEnableRequest_ISig_4 100;
BA_ "GenSigCycleTimeActive" SG_ 739 CCEnableRequest_ISig_4 100;
BA_ "GenSigStartValue" SG_ 739 CCEnableRequest_ISig_4 3;
BA_ "GenSigMaxLatency" SG_ 739 CCEnableRequest_ISig_4 41;
BA_ "Platform_VMCU1_Sig" SG_ 739 CCEnableRequest_ISig_4 1;
BA_ "GenSigCycleTime" SG_ 739 CCRequestedPresetSpeed 100;
BA_ "GenSigCycleTimeActive" SG_ 739 CCRequestedPresetSpeed 100;
BA_ "GenSigStartValue" SG_ 739 CCRequestedPresetSpeed 65535;
BA_ "GenSigMaxLatency" SG_ 739 CCRequestedPresetSpeed 41;
BA_ "Platform_VMCU1_Sig" SG_ 739 CCRequestedPresetSpeed 1;
BA_ "GenSigCycleTime" SG_ 739 CCDriverRequest 100;
BA_ "GenSigCycleTimeActive" SG_ 739 CCDriverRequest 100;
BA_ "GenSigStartValue" SG_ 739 CCDriverRequest 15;
BA_ "GenSigMaxLatency" SG_ 739 CCDriverRequest 41;
BA_ "Platform_VMCU1_Sig" SG_ 739 CCDriverRequest 1;
BA_ "GenSigCycleTime" SG_ 739 ASLRequestedPresetSpeed 100;
BA_ "GenSigCycleTimeActive" SG_ 739 ASLRequestedPresetSpeed 100;
BA_ "GenSigStartValue" SG_ 739 ASLRequestedPresetSpeed 65535;
BA_ "GenSigMaxLatency" SG_ 739 ASLRequestedPresetSpeed 41;
BA_ "Platform_VMCU1_Sig" SG_ 739 ASLRequestedPresetSpeed 1;
BA_ "GenSigCycleTime" SG_ 390 EcoRollEnableRequest_ISig_4 100;
BA_ "GenSigCycleTimeActive" SG_ 390 EcoRollEnableRequest_ISig_4 100;
BA_ "GenSigStartValue" SG_ 390 EcoRollEnableRequest_ISig_4 3;
BA_ "Platform_VMCU1_Sig" SG_ 390 EcoRollEnableRequest_ISig_4 1;
BA_ "GenSigCycleTime" SG_ 390 SelectedEcoCruiseLevel_ISig_4 100;
BA_ "GenSigCycleTimeActive" SG_ 390 SelectedEcoCruiseLevel_ISig_4 100;
BA_ "GenSigStartValue" SG_ 390 SelectedEcoCruiseLevel_ISig_4 7;
BA_ "Platform_VMCU1_Sig" SG_ 390 SelectedEcoCruiseLevel_ISig_4 1;
BA_ "GenSigCycleTime" SG_ 514 PS_GearSelectionMode_ISig_4 100;
BA_ "GenSigCycleTimeActive" SG_ 514 PS_GearSelectionMode_ISig_4 100;
BA_ "GenSigStartValue" SG_ 514 PS_GearSelectionMode_ISig_4 7;
BA_ "GenSigCycleTime" SG_ 514 WaterInFuelDrainRequest 100;
BA_ "GenSigCycleTimeActive" SG_ 514 WaterInFuelDrainRequest 100;
BA_ "GenSigMaxLatency" SG_ 514 WaterInFuelDrainRequest 26;
BA_ "Platform_VMCU1_Sig" SG_ 514 WaterInFuelDrainRequest 1;
BA_ "SeToolAncestorID_SIGNAL" SG_ 514 WaterInFuelDrainRequest "x0000001D041410E9";
BA_ "SeToolItemID_SIGNAL" SG_ 514 WaterInFuelDrainRequest "x0000001D041410E9";
BA_ "SeToolName_SIGNAL" SG_ 514 WaterInFuelDrainRequest "WaterInFuelDrainRequest";
BA_ "SeToolVersion_SIGNAL" SG_ 514 WaterInFuelDrainRequest "1";
BA_ "GenSigCycleTime" SG_ 514 FuncIndIlluminationLevel_ISig_4 100;
BA_ "GenSigCycleTimeActive" SG_ 514 FuncIndIlluminationLevel_ISig_4 100;
BA_ "GenSigStartValue" SG_ 514 FuncIndIlluminationLevel_ISig_4 1;
BA_ "GenSigMaxLatency" SG_ 514 FuncIndIlluminationLevel_ISig_4 26;
BA_ "Platform_VMCU1_Sig" SG_ 514 FuncIndIlluminationLevel_ISig_4 1;
BA_ "SeToolAncestorID_SIGNAL" SG_ 514 FuncIndIlluminationLevel_ISig_4 "x0000001D043A8396";
BA_ "SeToolItemID_SIGNAL" SG_ 514 FuncIndIlluminationLevel_ISig_4 "x0000001D043A8396";
BA_ "SeToolName_SIGNAL" SG_ 514 FuncIndIlluminationLevel_ISig_4 "FuncIndIlluminationLevel";
BA_ "SeToolVersion_SIGNAL" SG_ 514 FuncIndIlluminationLevel_ISig_4 "1";
BA_ "GenSigCycleTime" SG_ 514 ResumeRequestForACC 100;
BA_ "GenSigCycleTimeActive" SG_ 514 ResumeRequestForACC 100;
BA_ "GenSigStartValue" SG_ 514 ResumeRequestForACC 3;
BA_ "GenSigCycleTime" SG_ 514 SWSpeedControlAdjustMode 100;
BA_ "GenSigCycleTimeActive" SG_ 514 SWSpeedControlAdjustMode 100;
BA_ "GenSigStartValue" SG_ 514 SWSpeedControlAdjustMode 15;
BA_ "GenSigMaxLatency" SG_ 514 SWSpeedControlAdjustMode 89;
BA_ "Platform_VMCU1_Sig" SG_ 514 SWSpeedControlAdjustMode 1;
BA_ "GenSigCycleTime" SG_ 514 ACCTimeGapRqst 100;
BA_ "GenSigCycleTimeActive" SG_ 514 ACCTimeGapRqst 100;
BA_ "GenSigStartValue" SG_ 514 ACCTimeGapRqst 7;
BA_ "GenSigMaxLatency" SG_ 514 ACCTimeGapRqst 26;
BA_ "Platform_VMCU1_Sig" SG_ 514 ACCTimeGapRqst 1;
BA_ "SeToolAncestorID_SIGNAL" SG_ 514 ACCTimeGapRqst "x0000001D04146F87";
BA_ "SeToolItemID_SIGNAL" SG_ 514 ACCTimeGapRqst "x0000001D0420F337";
BA_ "SeToolName_SIGNAL" SG_ 514 ACCTimeGapRqst "ACCTimeGapRqst";
BA_ "SeToolVersion_SIGNAL" SG_ 514 ACCTimeGapRqst "2";
BA_ "GenSigCycleTime" SG_ 514 SWSpdCtrlButtonsStatus6 100;
BA_ "GenSigCycleTimeActive" SG_ 514 SWSpdCtrlButtonsStatus6 100;
BA_ "GenSigStartValue" SG_ 514 SWSpdCtrlButtonsStatus6 15;
BA_ "GenSigCycleTime" SG_ 514 ACCEnableRqst 100;
BA_ "GenSigCycleTimeActive" SG_ 514 ACCEnableRqst 100;
BA_ "GenSigStartValue" SG_ 514 ACCEnableRqst 3;
BA_ "GenSigMaxLatency" SG_ 514 ACCEnableRqst 26;
BA_ "Platform_VMCU1_Sig" SG_ 514 ACCEnableRqst 1;
BA_ "SeToolAncestorID_SIGNAL" SG_ 514 ACCEnableRqst "x0000001D0414B8A6";
BA_ "SeToolItemID_SIGNAL" SG_ 514 ACCEnableRqst "x0000001D0414B8A6";
BA_ "SeToolName_SIGNAL" SG_ 514 ACCEnableRqst "ACCEnableRqst";
BA_ "SeToolVersion_SIGNAL" SG_ 514 ACCEnableRqst "1";
BA_ "GenSigCycleTime" SG_ 514 StopAlert_cmd 100;
BA_ "GenSigCycleTimeActive" SG_ 514 StopAlert_cmd 100;
BA_ "GenSigStartValue" SG_ 514 StopAlert_cmd 7;
BA_ "Platform_VMCU1_Sig" SG_ 514 StopAlert_cmd 1;
BA_ "SeToolAncestorID_SIGNAL" SG_ 514 StopAlert_cmd "x0000001D04182F7F";
BA_ "SeToolItemID_SIGNAL" SG_ 514 StopAlert_cmd "x0000001D04295469";
BA_ "SeToolName_SIGNAL" SG_ 514 StopAlert_cmd "StopAlert_cmd";
BA_ "SeToolVersion_SIGNAL" SG_ 514 StopAlert_cmd "4";
BA_ "GenSigCycleTime" SG_ 514 BacklightCmd_ISig_4 100;
BA_ "GenSigCycleTimeActive" SG_ 514 BacklightCmd_ISig_4 100;
BA_ "GenSigMaxLatency" SG_ 514 BacklightCmd_ISig_4 26;
BA_ "Platform_VMCU1_Sig" SG_ 514 BacklightCmd_ISig_4 1;
BA_ "SeToolAncestorID_SIGNAL" SG_ 514 BacklightCmd_ISig_4 "x0000001D0439DDD1";
BA_ "SeToolItemID_SIGNAL" SG_ 514 BacklightCmd_ISig_4 "x0000001D043A84D3";
BA_ "SeToolName_SIGNAL" SG_ 514 BacklightCmd_ISig_4 "BacklightCmd";
BA_ "SeToolVersion_SIGNAL" SG_ 514 BacklightCmd_ISig_4 "2";
BA_ "GenSigCycleTime" SG_ 514 CMTelltale_stat 100;
BA_ "GenSigCycleTimeActive" SG_ 514 CMTelltale_stat 100;
BA_ "GenSigStartValue" SG_ 514 CMTelltale_stat 7;
BA_ "Platform_VMCU1_Sig" SG_ 514 CMTelltale_stat 1;
BA_ "GenSigCycleTime" SG_ 1288 EcoCruisePwtMaxOvSpeedLev3 100;
BA_ "GenSigCycleTimeActive" SG_ 1288 EcoCruisePwtMaxOvSpeedLev3 100;
BA_ "GenSigStartValue" SG_ 1288 EcoCruisePwtMaxOvSpeedLev3 31;
BA_ "Platform_VMCU1_Sig" SG_ 1288 EcoCruisePwtMaxOvSpeedLev3 1;
BA_ "GenSigCycleTime" SG_ 1288 EcoCruisePwtMaxOvSpeedLev0 100;
BA_ "GenSigCycleTimeActive" SG_ 1288 EcoCruisePwtMaxOvSpeedLev0 100;
BA_ "GenSigStartValue" SG_ 1288 EcoCruisePwtMaxOvSpeedLev0 31;
BA_ "Platform_VMCU1_Sig" SG_ 1288 EcoCruisePwtMaxOvSpeedLev0 1;
BA_ "GenSigCycleTime" SG_ 1288 EcoCruisePwtMaxUnSpeedLev0 100;
BA_ "GenSigCycleTimeActive" SG_ 1288 EcoCruisePwtMaxUnSpeedLev0 100;
BA_ "GenSigStartValue" SG_ 1288 EcoCruisePwtMaxUnSpeedLev0 31;
BA_ "Platform_VMCU1_Sig" SG_ 1288 EcoCruisePwtMaxUnSpeedLev0 1;
BA_ "GenSigCycleTime" SG_ 1288 EcoCruisePwtMaxOvSpeedLev2 100;
BA_ "GenSigCycleTimeActive" SG_ 1288 EcoCruisePwtMaxOvSpeedLev2 100;
BA_ "GenSigStartValue" SG_ 1288 EcoCruisePwtMaxOvSpeedLev2 31;
BA_ "Platform_VMCU1_Sig" SG_ 1288 EcoCruisePwtMaxOvSpeedLev2 1;
BA_ "GenSigCycleTime" SG_ 1288 EcoCruisePwtMaxOvSpeedLev1 100;
BA_ "GenSigCycleTimeActive" SG_ 1288 EcoCruisePwtMaxOvSpeedLev1 100;
BA_ "GenSigStartValue" SG_ 1288 EcoCruisePwtMaxOvSpeedLev1 31;
BA_ "Platform_VMCU1_Sig" SG_ 1288 EcoCruisePwtMaxOvSpeedLev1 1;
BA_ "GenSigCycleTime" SG_ 1288 EcoCruisePwtMaxUnSpeedLev3 100;
BA_ "GenSigCycleTimeActive" SG_ 1288 EcoCruisePwtMaxUnSpeedLev3 100;
BA_ "GenSigStartValue" SG_ 1288 EcoCruisePwtMaxUnSpeedLev3 31;
BA_ "Platform_VMCU1_Sig" SG_ 1288 EcoCruisePwtMaxUnSpeedLev3 1;
BA_ "GenSigCycleTime" SG_ 1288 EcoCruisePwtMaxUnSpeedLev1 100;
BA_ "GenSigCycleTimeActive" SG_ 1288 EcoCruisePwtMaxUnSpeedLev1 100;
BA_ "GenSigStartValue" SG_ 1288 EcoCruisePwtMaxUnSpeedLev1 31;
BA_ "Platform_VMCU1_Sig" SG_ 1288 EcoCruisePwtMaxUnSpeedLev1 1;
BA_ "GenSigCycleTime" SG_ 1288 EcoCruisePwtMaxUnSpeedLev2 100;
BA_ "GenSigCycleTimeActive" SG_ 1288 EcoCruisePwtMaxUnSpeedLev2 100;
BA_ "GenSigStartValue" SG_ 1288 EcoCruisePwtMaxUnSpeedLev2 31;
BA_ "Platform_VMCU1_Sig" SG_ 1288 EcoCruisePwtMaxUnSpeedLev2 1;
BA_ "GenSigCycleTime" SG_ 1285 TotPTOLNGHighAccuracy 100;
BA_ "GenSigCycleTimeActive" SG_ 1285 TotPTOLNGHighAccuracy 100;
BA_ "GenSigStartValue" SG_ 1285 TotPTOLNGHighAccuracy 4294967295;
BA_ "Platform_VMCU1_Sig" SG_ 1285 TotPTOLNGHighAccuracy 1;
BA_ "GenSigCycleTime" SG_ 1282 ExhManif_EMAIAirTankPres_ISig_4 100;
BA_ "GenSigCycleTimeActive" SG_ 1282 ExhManif_EMAIAirTankPres_ISig_4 100;
BA_ "GenSigStartValue" SG_ 1282 ExhManif_EMAIAirTankPres_ISig_4 255;
BA_ "GenSigCycleTime" SG_ 1282 EngineFuelMode 100;
BA_ "GenSigCycleTimeActive" SG_ 1282 EngineFuelMode 100;
BA_ "GenSigStartValue" SG_ 1282 EngineFuelMode 3;
BA_ "Platform_VMCU1_Sig" SG_ 1282 EngineFuelMode 1;
BA_ "GenSigCycleTime" SG_ 1282 LNGOperatorInducementReason 100;
BA_ "GenSigCycleTimeActive" SG_ 1282 LNGOperatorInducementReason 100;
BA_ "GenSigStartValue" SG_ 1282 LNGOperatorInducementReason 7;
BA_ "Platform_VMCU1_Sig" SG_ 1282 LNGOperatorInducementReason 1;
BA_ "GenSigCycleTime" SG_ 1282 DPF_RegenCompleted 100;
BA_ "GenSigCycleTimeActive" SG_ 1282 DPF_RegenCompleted 100;
BA_ "GenSigStartValue" SG_ 1282 DPF_RegenCompleted 7;
BA_ "Platform_VMCU1_Sig" SG_ 1282 DPF_RegenCompleted 1;
BA_ "GenSigCycleTime" SG_ 1282 EngineTotalLngConsumed_ISig_4 100;
BA_ "GenSigCycleTimeActive" SG_ 1282 EngineTotalLngConsumed_ISig_4 100;
BA_ "GenSigStartValue" SG_ 1282 EngineTotalLngConsumed_ISig_4 4294967295;
BA_ "Platform_VMCU1_Sig" SG_ 1282 EngineTotalLngConsumed_ISig_4 1;
BA_ "GenSigCycleTime" SG_ 1252 DistLeftToSevereInducement_OBD 100;
BA_ "GenSigCycleTimeActive" SG_ 1252 DistLeftToSevereInducement_OBD 100;
BA_ "GenSigStartValue" SG_ 1252 DistLeftToSevereInducement_OBD 255;
BA_ "Platform_VMCU1_Sig" SG_ 1252 DistLeftToSevereInducement_OBD 1;
BA_ "GenSigCycleTime" SG_ 1252 TopGearUseDistance_ISig_4 100;
BA_ "GenSigCycleTimeActive" SG_ 1252 TopGearUseDistance_ISig_4 100;
BA_ "GenSigStartValue" SG_ 1252 TopGearUseDistance_ISig_4 4294967295;
BA_ "Platform_VMCU1_Sig" SG_ 1252 TopGearUseDistance_ISig_4 1;
BA_ "GenSigSendType" SG_ 961 EMS_BB2_11S_FCS 7;
BA_ "Platform_VMCU1_Sig" SG_ 961 EMS_BB2_11S_FCS 1;
BA_ "GenSigSendType" SG_ 958 KeyID_EngineStartAuth 1;
BA_ "GenSigMaxLatency" SG_ 958 KeyID_EngineStartAuth 100;
BA_ "Platform_VMCU1_Sig" SG_ 958 KeyID_EngineStartAuth 1;
BA_ "GenSigCycleTime" SG_ 1374 TimeLeftToTorqueReduction_OBD 100;
BA_ "GenSigCycleTimeActive" SG_ 1374 TimeLeftToTorqueReduction_OBD 100;
BA_ "GenSigStartValue" SG_ 1374 TimeLeftToTorqueReduction_OBD 511;
BA_ "GenSigMaxLatency" SG_ 1374 TimeLeftToTorqueReduction_OBD 257;
BA_ "Platform_VMCU1_Sig" SG_ 1374 TimeLeftToTorqueReduction_OBD 1;
BA_ "SeToolAncestorID_SIGNAL" SG_ 1374 TimeLeftToTorqueReduction_OBD "x0000001D043B9BEC";
BA_ "SeToolItemID_SIGNAL" SG_ 1374 TimeLeftToTorqueReduction_OBD "x0000001D043B9BEC";
BA_ "SeToolName_SIGNAL" SG_ 1374 TimeLeftToTorqueReduction_OBD "TimeLeftToTorqueReduction_OBD";
BA_ "SeToolVersion_SIGNAL" SG_ 1374 TimeLeftToTorqueReduction_OBD "1";
BA_ "GenSigCycleTime" SG_ 1374 AdblueTotalConsumed_ISig_4 100;
BA_ "GenSigCycleTimeActive" SG_ 1374 AdblueTotalConsumed_ISig_4 100;
BA_ "GenSigStartValue" SG_ 1374 AdblueTotalConsumed_ISig_4 4294967295;
BA_ "Platform_VMCU1_Sig" SG_ 1374 AdblueTotalConsumed_ISig_4 1;
BA_ "GenSigCycleTime" SG_ 1374 MIStatus_ISig_4 100;
BA_ "GenSigCycleTimeActive" SG_ 1374 MIStatus_ISig_4 100;
BA_ "GenSigStartValue" SG_ 1374 MIStatus_ISig_4 3;
BA_ "GenSigMaxLatency" SG_ 1374 MIStatus_ISig_4 257;
BA_ "Platform_VMCU1_Sig" SG_ 1374 MIStatus_ISig_4 1;
BA_ "SeToolAncestorID_SIGNAL" SG_ 1374 MIStatus_ISig_4 "x0000001D04147511";
BA_ "SeToolItemID_SIGNAL" SG_ 1374 MIStatus_ISig_4 "x0000001D0423C9EA";
BA_ "SeToolName_SIGNAL" SG_ 1374 MIStatus_ISig_4 "MIStatus";
BA_ "SeToolVersion_SIGNAL" SG_ 1374 MIStatus_ISig_4 "2";
BA_ "GenSigCycleTime" SG_ 1374 TorqueReductionStatus_OBD 100;
BA_ "GenSigCycleTimeActive" SG_ 1374 TorqueReductionStatus_OBD 100;
BA_ "GenSigStartValue" SG_ 1374 TorqueReductionStatus_OBD 7;
BA_ "GenSigMaxLatency" SG_ 1374 TorqueReductionStatus_OBD 257;
BA_ "Platform_VMCU1_Sig" SG_ 1374 TorqueReductionStatus_OBD 1;
BA_ "SeToolAncestorID_SIGNAL" SG_ 1374 TorqueReductionStatus_OBD "x0000001D043B9BA6";
BA_ "SeToolItemID_SIGNAL" SG_ 1374 TorqueReductionStatus_OBD "x0000001D043B9BA6";
BA_ "SeToolName_SIGNAL" SG_ 1374 TorqueReductionStatus_OBD "TorqueReductionStatus_OBD";
BA_ "SeToolVersion_SIGNAL" SG_ 1374 TorqueReductionStatus_OBD "1";
BA_ "GenSigCycleTime" SG_ 1374 SCROperatorInducementSeverity 100;
BA_ "GenSigCycleTimeActive" SG_ 1374 SCROperatorInducementSeverity 100;
BA_ "GenSigStartValue" SG_ 1374 SCROperatorInducementSeverity 7;
BA_ "Platform_VMCU1_Sig" SG_ 1374 SCROperatorInducementSeverity 1;
BA_ "GenSigCycleTime" SG_ 1374 SCROperatorInducementReason 100;
BA_ "GenSigCycleTimeActive" SG_ 1374 SCROperatorInducementReason 100;
BA_ "GenSigStartValue" SG_ 1374 SCROperatorInducementReason 7;
BA_ "Platform_VMCU1_Sig" SG_ 1374 SCROperatorInducementReason 1;
BA_ "GenSigCycleTime" SG_ 1374 MIDistinctWarning 100;
BA_ "GenSigCycleTimeActive" SG_ 1374 MIDistinctWarning 100;
BA_ "GenSigStartValue" SG_ 1374 MIDistinctWarning 3;
BA_ "GenSigMaxLatency" SG_ 1374 MIDistinctWarning 257;
BA_ "Platform_VMCU1_Sig" SG_ 1374 MIDistinctWarning 1;
BA_ "SeToolAncestorID_SIGNAL" SG_ 1374 MIDistinctWarning "x0000001D04147513";
BA_ "SeToolItemID_SIGNAL" SG_ 1374 MIDistinctWarning "x0000001D0423C9E0";
BA_ "SeToolName_SIGNAL" SG_ 1374 MIDistinctWarning "MIDistinctWarning";
BA_ "SeToolVersion_SIGNAL" SG_ 1374 MIDistinctWarning "2";
BA_ "GenSigCycleTime" SG_ 1374 MIStatusExtEMS 100;
BA_ "GenSigCycleTimeActive" SG_ 1374 MIStatusExtEMS 100;
BA_ "GenSigStartValue" SG_ 1374 MIStatusExtEMS 3;
BA_ "Platform_VMCU1_Sig" SG_ 1374 MIStatusExtEMS 1;
BA_ "GenSigCycleTime" SG_ 1374 MIDistinctWarningExtEMS_ISig_4 100;
BA_ "GenSigCycleTimeActive" SG_ 1374 MIDistinctWarningExtEMS_ISig_4 100;
BA_ "GenSigStartValue" SG_ 1374 MIDistinctWarningExtEMS_ISig_4 15;
BA_ "Platform_VMCU1_Sig" SG_ 1374 MIDistinctWarningExtEMS_ISig_4 1;
BA_ "GenSigSendType" SG_ 1342 EMS_BB2_09S_FCS 7;
BA_ "Platform_VMCU1_Sig" SG_ 1342 EMS_BB2_09S_FCS 1;
BA_ "GenSigSendType" SG_ 1341 ECU4VIN_stat 1;
BA_ "GenSigMaxLatency" SG_ 1341 ECU4VIN_stat 137;
BA_ "Platform_VMCU1_Sig" SG_ 1341 ECU4VIN_stat 1;
BA_ "GenSigCycleTime" SG_ 1392 EngineRunningTime_ISig_4 100;
BA_ "GenSigCycleTimeActive" SG_ 1392 EngineRunningTime_ISig_4 100;
BA_ "GenSigStartValue" SG_ 1392 EngineRunningTime_ISig_4 4294967295;
BA_ "Platform_VMCU1_Sig" SG_ 1392 EngineRunningTime_ISig_4 1;
BA_ "GenSigCycleTime" SG_ 1392 TotPTOFuelHighAccuracy 100;
BA_ "GenSigCycleTimeActive" SG_ 1392 TotPTOFuelHighAccuracy 100;
BA_ "GenSigStartValue" SG_ 1392 TotPTOFuelHighAccuracy 4294967295;
BA_ "Platform_VMCU1_Sig" SG_ 1392 TotPTOFuelHighAccuracy 1;
BA_ "GenSigCycleTime" SG_ 1391 OilPrediction_Quality 100;
BA_ "GenSigCycleTimeActive" SG_ 1391 OilPrediction_Quality 100;
BA_ "GenSigStartValue" SG_ 1391 OilPrediction_Quality 7;
BA_ "Platform_VMCU1_Sig" SG_ 1391 OilPrediction_Quality 1;
BA_ "GenSigCycleTime" SG_ 1391 TimeLeftToVehSpdReduction_OBD 100;
BA_ "GenSigCycleTimeActive" SG_ 1391 TimeLeftToVehSpdReduction_OBD 100;
BA_ "GenSigStartValue" SG_ 1391 TimeLeftToVehSpdReduction_OBD 511;
BA_ "Platform_VMCU1_Sig" SG_ 1391 TimeLeftToVehSpdReduction_OBD 1;
BA_ "GenSigCycleTime" SG_ 1391 OilPrediction_RemainDist 100;
BA_ "GenSigCycleTimeActive" SG_ 1391 OilPrediction_RemainDist 100;
BA_ "GenSigStartValue" SG_ 1391 OilPrediction_RemainDist 65535;
BA_ "Platform_VMCU1_Sig" SG_ 1391 OilPrediction_RemainDist 1;
BA_ "GenSigCycleTime" SG_ 1391 TimeToCorrectOilLevel_ISig_4 100;
BA_ "GenSigCycleTimeActive" SG_ 1391 TimeToCorrectOilLevel_ISig_4 100;
BA_ "GenSigStartValue" SG_ 1391 TimeToCorrectOilLevel_ISig_4 255;
BA_ "Platform_VMCU1_Sig" SG_ 1391 TimeToCorrectOilLevel_ISig_4 1;
BA_ "GenSigCycleTime" SG_ 1391 OilPrediction_RemainTime 100;
BA_ "GenSigCycleTimeActive" SG_ 1391 OilPrediction_RemainTime 100;
BA_ "GenSigStartValue" SG_ 1391 OilPrediction_RemainTime 65535;
BA_ "Platform_VMCU1_Sig" SG_ 1391 OilPrediction_RemainTime 1;
BA_ "GenSigCycleTime" SG_ 1391 OilPrediction_Status 100;
BA_ "GenSigCycleTimeActive" SG_ 1391 OilPrediction_Status 100;
BA_ "GenSigStartValue" SG_ 1391 OilPrediction_Status 7;
BA_ "Platform_VMCU1_Sig" SG_ 1391 OilPrediction_Status 1;
BA_REL_ "GenSigFirstTimeoutTime" BU_SG_REL_ CIOM SG_ 838 AirbagTelltale_stat_ISig_4 3000;
BA_REL_ "GenSigTimeoutTime" BU_SG_REL_ CIOM SG_ 838 AirbagTelltale_stat_ISig_4 300;
BA_REL_ "GenSigFirstTimeoutTime" BU_SG_REL_ CIOM SG_ 838 AQSModeRqst_ISig_4 3000;
BA_REL_ "GenSigTimeoutTime" BU_SG_REL_ CIOM SG_ 838 AQSModeRqst_ISig_4 300;
BA_REL_ "GenSigFirstTimeoutTime" BU_SG_REL_ VMCU SG_ 838 VCSystPowerSupply_rqst 3000;
BA_REL_ "GenSigTimeoutTime" BU_SG_REL_ VMCU SG_ 838 VCSystPowerSupply_rqst 300;
BA_REL_ "GenSigFirstTimeoutTime" BU_SG_REL_ TECU SG_ 838 ISeeEnableRequest 3000;
BA_REL_ "GenSigTimeoutTime" BU_SG_REL_ TECU SG_ 838 ISeeEnableRequest 300;
BA_REL_ "GenSigFirstTimeoutTime" BU_SG_REL_ CIOM SG_ 838 ACModeRqst_ISig_4 3000;
BA_REL_ "GenSigTimeoutTime" BU_SG_REL_ CIOM SG_ 838 ACModeRqst_ISig_4 300;
BA_REL_ "GenSigFirstTimeoutTime" BU_SG_REL_ CIOM SG_ 838 RemoteParkClimateRqst_ISig_4 3000;
BA_REL_ "GenSigTimeoutTime" BU_SG_REL_ CIOM SG_ 838 RemoteParkClimateRqst_ISig_4 300;
BA_REL_ "GenSigFirstTimeoutTime" BU_SG_REL_ VMCU SG_ 838 CalDataLoad_rqst_VehicleID 6000;
BA_REL_ "GenSigTimeoutTime" BU_SG_REL_ VMCU SG_ 838 CalDataLoad_rqst_VehicleID 300;
BA_REL_ "GenSigFirstTimeoutTime" BU_SG_REL_ VMCU SG_ 838 CalDataLoad_rqst_AxleID 6000;
BA_REL_ "GenSigTimeoutTime" BU_SG_REL_ VMCU SG_ 838 CalDataLoad_rqst_AxleID 300;
BA_REL_ "GenSigFirstTimeoutTime" BU_SG_REL_ CIOM SG_ 838 AutoBlowerLevelRqst_ISig_4 3000;
BA_REL_ "GenSigTimeoutTime" BU_SG_REL_ CIOM SG_ 838 AutoBlowerLevelRqst_ISig_4 300;
BA_REL_ "GenSigFirstTimeoutTime" BU_SG_REL_ CIOM SG_ 838 AutoDefogModeRqst_ISig_4 3000;
BA_REL_ "GenSigTimeoutTime" BU_SG_REL_ CIOM SG_ 838 AutoDefogModeRqst_ISig_4 300;
BA_REL_ "GenSigFirstTimeoutTime" BU_SG_REL_ VMCU SG_ 1422 FasUsrDefinedStorage_rqst_ISig_4 24000;
BA_REL_ "GenSigTimeoutTime" BU_SG_REL_ VMCU SG_ 1422 FasUsrDefinedStorage_rqst_ISig_4 6000;
BA_REL_ "GenSigFirstTimeoutTime" BU_SG_REL_ CIOM SG_ 1422 ATC_ButtonIndication 24000;
BA_REL_ "GenSigTimeoutTime" BU_SG_REL_ CIOM SG_ 1422 ATC_ButtonIndication 6000;
BA_REL_ "GenSigFirstTimeoutTime" BU_SG_REL_ VMCU SG_ 1422 FasLowSpeedReturnSetting_rqst_IS 24000;
BA_REL_ "GenSigTimeoutTime" BU_SG_REL_ VMCU SG_ 1422 FasLowSpeedReturnSetting_rqst_IS 6000;
BA_REL_ "GenSigFirstTimeoutTime" BU_SG_REL_ VMCU SG_ 1422 FasManualOffsetSetting_rqst_ISig 24000;
BA_REL_ "GenSigTimeoutTime" BU_SG_REL_ VMCU SG_ 1422 FasManualOffsetSetting_rqst_ISig 6000;
BA_REL_ "GenSigFirstTimeoutTime" BU_SG_REL_ VMCU SG_ 1422 FasPersonalSettingsButton_rqst_I 24000;
BA_REL_ "GenSigTimeoutTime" BU_SG_REL_ VMCU SG_ 1422 FasPersonalSettingsButton_rqst_I 6000;
BA_REL_ "GenSigFirstTimeoutTime" BU_SG_REL_ VMCU SG_ 1422 FasStiffnessCurveSetting_rqst_IS 24000;
BA_REL_ "GenSigTimeoutTime" BU_SG_REL_ VMCU SG_ 1422 FasStiffnessCurveSetting_rqst_IS 6000;
BA_REL_ "GenSigFirstTimeoutTime" BU_SG_REL_ VMCU SG_ 1422 FasStiffStraightSetting_rqst_ISi 24000;
BA_REL_ "GenSigTimeoutTime" BU_SG_REL_ VMCU SG_ 1422 FasStiffStraightSetting_rqst_ISi 6000;
BA_REL_ "GenSigFirstTimeoutTime" BU_SG_REL_ VMCU SG_ 1422 FasDriver_rqst_ISig_4 24000;
BA_REL_ "GenSigTimeoutTime" BU_SG_REL_ VMCU SG_ 1422 FasDriver_rqst_ISig_4 6000;
BA_REL_ "GenSigFirstTimeoutTime" BU_SG_REL_ VMCU SG_ 1422 FasDampingSetting_rqst_ISig_4 24000;
BA_REL_ "GenSigTimeoutTime" BU_SG_REL_ VMCU SG_ 1422 FasDampingSetting_rqst_ISig_4 6000;
BA_REL_ "GenSigFirstTimeoutTime" BU_SG_REL_ CIOM SG_ 1422 ESC_ButtonIndication2 24000;
BA_REL_ "GenSigTimeoutTime" BU_SG_REL_ CIOM SG_ 1422 ESC_ButtonIndication2 6000;
BA_REL_ "GenSigFirstTimeoutTime" BU_SG_REL_ CIOM SG_ 1422 TCS_ButtonIndication 24000;
BA_REL_ "GenSigTimeoutTime" BU_SG_REL_ CIOM SG_ 1422 TCS_ButtonIndication 6000;
BA_REL_ "GenSigFirstTimeoutTime" BU_SG_REL_ CIOM SG_ 1422 ABS_ButtonIndication 24000;
BA_REL_ "GenSigTimeoutTime" BU_SG_REL_ CIOM SG_ 1422 ABS_ButtonIndication 6000;
BA_REL_ "GenSigFirstTimeoutTime" BU_SG_REL_ CIOM SG_ 1421 ESCOff_DeviceIndication 3000;
BA_REL_ "GenSigTimeoutTime" BU_SG_REL_ CIOM SG_ 1421 ESCOff_DeviceIndication 600;
BA_REL_ "GenSigFirstTimeoutTime" BU_SG_REL_ VMCU SG_ 1421 CCUnderSpeedRequest 3000;
BA_REL_ "GenSigTimeoutTime" BU_SG_REL_ VMCU SG_ 1421 CCUnderSpeedRequest 600;
BA_REL_ "GenSigFirstTimeoutTime" BU_SG_REL_ VMCU SG_ 1421 DHCActiveRequest 3000;
BA_REL_ "GenSigTimeoutTime" BU_SG_REL_ VMCU SG_ 1421 DHCActiveRequest 600;
BA_REL_ "GenSigFirstTimeoutTime" BU_SG_REL_ CIOM SG_ 1421 RollerBenchGUIDeviceStatus 3000;
BA_REL_ "GenSigTimeoutTime" BU_SG_REL_ CIOM SG_ 1421 RollerBenchGUIDeviceStatus 600;
BA_REL_ "GenSigFirstTimeoutTime" BU_SG_REL_ VMCU SG_ 1421 DHCSetSpeedAdjustRequest 3000;
BA_REL_ "GenSigTimeoutTime" BU_SG_REL_ VMCU SG_ 1421 DHCSetSpeedAdjustRequest 600;
BA_REL_ "GenSigFirstTimeoutTime" BU_SG_REL_ DACU SG_ 1421 AutomaticCMenableStatus 3000;
BA_REL_ "GenSigTimeoutTime" BU_SG_REL_ DACU SG_ 1421 AutomaticCMenableStatus 600;
BA_REL_ "GenSigFirstTimeoutTime" BU_SG_REL_ VMCU SG_ 1421 SetDaylightSaving_rqst 3000;
BA_REL_ "GenSigTimeoutTime" BU_SG_REL_ VMCU SG_ 1421 SetDaylightSaving_rqst 600;
BA_REL_ "GenSigFirstTimeoutTime" BU_SG_REL_ VMCU SG_ 1421 CamerasPowerSupply_rqst 3000;
BA_REL_ "GenSigTimeoutTime" BU_SG_REL_ VMCU SG_ 1421 CamerasPowerSupply_rqst 600;
BA_REL_ "GenSigFirstTimeoutTime" BU_SG_REL_ VMCU SG_ 1421 AFSActiveAllowedInDP_GUIrqst 3000;
BA_REL_ "GenSigTimeoutTime" BU_SG_REL_ VMCU SG_ 1421 AFSActiveAllowedInDP_GUIrqst 600;
BA_REL_ "GenSigFirstTimeoutTime" BU_SG_REL_ CIOM SG_ 822 SEMMediaSourceAvail_Source04_ISi 3000;
BA_REL_ "GenSigTimeoutTime" BU_SG_REL_ CIOM SG_ 822 SEMMediaSourceAvail_Source04_ISi 300;
BA_REL_ "GenSigFirstTimeoutTime" BU_SG_REL_ CIOM SG_ 822 SEMMediaSourceAvail_Source10_ISi 3000;
BA_REL_ "GenSigTimeoutTime" BU_SG_REL_ CIOM SG_ 822 SEMMediaSourceAvail_Source10_ISi 300;
BA_REL_ "GenSigFirstTimeoutTime" BU_SG_REL_ CIOM SG_ 822 SEMMediaSourceAvail_SInfo_ISig_4 3000;
BA_REL_ "GenSigTimeoutTime" BU_SG_REL_ CIOM SG_ 822 SEMMediaSourceAvail_SInfo_ISig_4 300;
BA_REL_ "GenSigFirstTimeoutTime" BU_SG_REL_ CIOM SG_ 822 SEM_PresetIndicationCmd_ISig_4 3000;
BA_REL_ "GenSigTimeoutTime" BU_SG_REL_ CIOM SG_ 822 SEM_PresetIndicationCmd_ISig_4 300;
BA_REL_ "GenSigFirstTimeoutTime" BU_SG_REL_ CIOM SG_ 822 SEMMediaSourceAvail_Source09_ISi 3000;
BA_REL_ "GenSigTimeoutTime" BU_SG_REL_ CIOM SG_ 822 SEMMediaSourceAvail_Source09_ISi 300;
BA_REL_ "GenSigFirstTimeoutTime" BU_SG_REL_ CIOM SG_ 822 SEMMediaSourceAvail_Source12_ISi 3000;
BA_REL_ "GenSigTimeoutTime" BU_SG_REL_ CIOM SG_ 822 SEMMediaSourceAvail_Source12_ISi 300;
BA_REL_ "GenSigFirstTimeoutTime" BU_SG_REL_ CIOM SG_ 822 SEMMediaSourceAvail_Source07_ISi 3000;
BA_REL_ "GenSigTimeoutTime" BU_SG_REL_ CIOM SG_ 822 SEMMediaSourceAvail_Source07_ISi 300;
BA_REL_ "GenSigFirstTimeoutTime" BU_SG_REL_ CIOM SG_ 822 SEMMediaSourceAvail_Source03_ISi 3000;
BA_REL_ "GenSigTimeoutTime" BU_SG_REL_ CIOM SG_ 822 SEMMediaSourceAvail_Source03_ISi 300;
BA_REL_ "GenSigFirstTimeoutTime" BU_SG_REL_ CIOM SG_ 822 SEMMediaSourceAvail_Source11_ISi 3000;
BA_REL_ "GenSigTimeoutTime" BU_SG_REL_ CIOM SG_ 822 SEMMediaSourceAvail_Source11_ISi 300;
BA_REL_ "GenSigFirstTimeoutTime" BU_SG_REL_ CIOM SG_ 822 SEM_AudioVolValIndCmd_ISig_4 3000;
BA_REL_ "GenSigTimeoutTime" BU_SG_REL_ CIOM SG_ 822 SEM_AudioVolValIndCmd_ISig_4 300;
BA_REL_ "GenSigFirstTimeoutTime" BU_SG_REL_ CIOM SG_ 822 SEMMediaSourceAvail_Source02_ISi 3000;
BA_REL_ "GenSigTimeoutTime" BU_SG_REL_ CIOM SG_ 822 SEMMediaSourceAvail_Source02_ISi 300;
BA_REL_ "GenSigFirstTimeoutTime" BU_SG_REL_ CIOM SG_ 822 AudioSourceStat_ISig_4 3000;
BA_REL_ "GenSigTimeoutTime" BU_SG_REL_ CIOM SG_ 822 AudioSourceStat_ISig_4 300;
BA_REL_ "GenSigFirstTimeoutTime" BU_SG_REL_ CIOM SG_ 822 SEMMediaSourceAvail_Source06_ISi 3000;
BA_REL_ "GenSigTimeoutTime" BU_SG_REL_ CIOM SG_ 822 SEMMediaSourceAvail_Source06_ISi 300;
BA_REL_ "GenSigFirstTimeoutTime" BU_SG_REL_ CIOM SG_ 822 SEMMediaSourceAvail_Source00_ISi 3000;
BA_REL_ "GenSigTimeoutTime" BU_SG_REL_ CIOM SG_ 822 SEMMediaSourceAvail_Source00_ISi 300;
BA_REL_ "GenSigFirstTimeoutTime" BU_SG_REL_ CIOM SG_ 822 SEMMediaSourceAvail_Source01_ISi 3000;
BA_REL_ "GenSigTimeoutTime" BU_SG_REL_ CIOM SG_ 822 SEMMediaSourceAvail_Source01_ISi 300;
BA_REL_ "GenSigFirstTimeoutTime" BU_SG_REL_ CIOM SG_ 822 SEMMediaSourceAvail_Source08_ISi 3000;
BA_REL_ "GenSigTimeoutTime" BU_SG_REL_ CIOM SG_ 822 SEMMediaSourceAvail_Source08_ISi 300;
BA_REL_ "GenSigFirstTimeoutTime" BU_SG_REL_ CIOM SG_ 822 SEM_AudioMuteStat_ISig_4 3000;
BA_REL_ "GenSigTimeoutTime" BU_SG_REL_ CIOM SG_ 822 SEM_AudioMuteStat_ISig_4 300;
BA_REL_ "GenSigFirstTimeoutTime" BU_SG_REL_ CIOM SG_ 822 SEMMediaSourceAvail_Source13_ISi 3000;
BA_REL_ "GenSigTimeoutTime" BU_SG_REL_ CIOM SG_ 822 SEMMediaSourceAvail_Source13_ISi 300;
BA_REL_ "GenSigFirstTimeoutTime" BU_SG_REL_ CIOM SG_ 822 SEMMediaSourceAvail_Source05_ISi 3000;
BA_REL_ "GenSigTimeoutTime" BU_SG_REL_ CIOM SG_ 822 SEMMediaSourceAvail_Source05_ISi 300;
BA_REL_ "GenSigFirstTimeoutTime" BU_SG_REL_ VMCU SG_ 1337 TPMUnmateTrailerReq_ISig_4 12000;
BA_REL_ "GenSigTimeoutTime" BU_SG_REL_ VMCU SG_ 1337 TPMUnmateTrailerReq_ISig_4 3000;
BA_REL_ "GenSigFirstTimeoutTime" BU_SG_REL_ VMCU SG_ 1337 TPMSetAxleRefPres_Axle4_ISig_4 12000;
BA_REL_ "GenSigTimeoutTime" BU_SG_REL_ VMCU SG_ 1337 TPMSetAxleRefPres_Axle4_ISig_4 3000;
BA_REL_ "GenSigFirstTimeoutTime" BU_SG_REL_ VMCU SG_ 1337 TPMPosOfWMReq_VehiclePos_ISig_4 12000;
BA_REL_ "GenSigTimeoutTime" BU_SG_REL_ VMCU SG_ 1337 TPMPosOfWMReq_VehiclePos_ISig_4 3000;
BA_REL_ "GenSigFirstTimeoutTime" BU_SG_REL_ VMCU SG_ 1337 TPMSetAxleRefPres_Axle1_ISig_4 12000;
BA_REL_ "GenSigTimeoutTime" BU_SG_REL_ VMCU SG_ 1337 TPMSetAxleRefPres_Axle1_ISig_4 3000;
BA_REL_ "GenSigFirstTimeoutTime" BU_SG_REL_ VMCU SG_ 1337 TPMSetAxleRefPres_Axle2_ISig_4 12000;
BA_REL_ "GenSigTimeoutTime" BU_SG_REL_ VMCU SG_ 1337 TPMSetAxleRefPres_Axle2_ISig_4 3000;
BA_REL_ "GenSigFirstTimeoutTime" BU_SG_REL_ VMCU SG_ 1337 TPMSetAxleRefPres_Axle3_ISig_4 12000;
BA_REL_ "GenSigTimeoutTime" BU_SG_REL_ VMCU SG_ 1337 TPMSetAxleRefPres_Axle3_ISig_4 3000;
BA_REL_ "GenSigFirstTimeoutTime" BU_SG_REL_ VMCU SG_ 1337 TPMMateTrailerReq_ISig_4 12000;
BA_REL_ "GenSigTimeoutTime" BU_SG_REL_ VMCU SG_ 1337 TPMMateTrailerReq_ISig_4 3000;
BA_REL_ "GenSigFirstTimeoutTime" BU_SG_REL_ VMCU SG_ 1337 TPMPosOfWMReq_TireId_ISig_4 12000;
BA_REL_ "GenSigTimeoutTime" BU_SG_REL_ VMCU SG_ 1337 TPMPosOfWMReq_TireId_ISig_4 3000;
BA_REL_ "GenSigFirstTimeoutTime" BU_SG_REL_ VMCU SG_ 1337 TPMSetAxleRefPres_Axle5_ISig_4 12000;
BA_REL_ "GenSigTimeoutTime" BU_SG_REL_ VMCU SG_ 1337 TPMSetAxleRefPres_Axle5_ISig_4 3000;
BA_REL_ "GenSigFirstTimeoutTime" BU_SG_REL_ VMCU SG_ 1337 TPMSetAxleRefPres_VehiclePos_ISi 12000;
BA_REL_ "GenSigTimeoutTime" BU_SG_REL_ VMCU SG_ 1337 TPMSetAxleRefPres_VehiclePos_ISi 3000;
BA_REL_ "GenSigFirstTimeoutTime" BU_SG_REL_ VMCU SG_ 1336 TPMSetAxleTireConfig_Axle4_ISig_ 12000;
BA_REL_ "GenSigTimeoutTime" BU_SG_REL_ VMCU SG_ 1336 TPMSetAxleTireConfig_Axle4_ISig_ 3000;
BA_REL_ "GenSigFirstTimeoutTime" BU_SG_REL_ VMCU SG_ 1336 TPMSetAxleTireConfig_Axle5_ISig_ 12000;
BA_REL_ "GenSigTimeoutTime" BU_SG_REL_ VMCU SG_ 1336 TPMSetAxleTireConfig_Axle5_ISig_ 3000;
BA_REL_ "GenSigFirstTimeoutTime" BU_SG_REL_ VMCU SG_ 1336 TPMSetPresThresCfg_VehiclePos_IS 12000;
BA_REL_ "GenSigTimeoutTime" BU_SG_REL_ VMCU SG_ 1336 TPMSetPresThresCfg_VehiclePos_IS 3000;
BA_REL_ "GenSigFirstTimeoutTime" BU_SG_REL_ VMCU SG_ 1336 TPMSetPresThresCfg_ExtOverPres_I 12000;
BA_REL_ "GenSigTimeoutTime" BU_SG_REL_ VMCU SG_ 1336 TPMSetPresThresCfg_ExtOverPres_I 3000;
BA_REL_ "GenSigFirstTimeoutTime" BU_SG_REL_ VMCU SG_ 1336 TPMSetAxleTireConfig_Axle2_ISig_ 12000;
BA_REL_ "GenSigTimeoutTime" BU_SG_REL_ VMCU SG_ 1336 TPMSetAxleTireConfig_Axle2_ISig_ 3000;
BA_REL_ "GenSigFirstTimeoutTime" BU_SG_REL_ VMCU SG_ 1336 TPMSetAxleTireConfig_VehiclePos_ 12000;
BA_REL_ "GenSigTimeoutTime" BU_SG_REL_ VMCU SG_ 1336 TPMSetAxleTireConfig_VehiclePos_ 3000;
BA_REL_ "GenSigFirstTimeoutTime" BU_SG_REL_ VMCU SG_ 1336 TPMSetAxleTireConfig_Axle3_ISig_ 12000;
BA_REL_ "GenSigTimeoutTime" BU_SG_REL_ VMCU SG_ 1336 TPMSetAxleTireConfig_Axle3_ISig_ 3000;
BA_REL_ "GenSigFirstTimeoutTime" BU_SG_REL_ VMCU SG_ 1336 TPMSetAxleTireConfig_Axle1_ISig_ 12000;
BA_REL_ "GenSigTimeoutTime" BU_SG_REL_ VMCU SG_ 1336 TPMSetAxleTireConfig_Axle1_ISig_ 3000;
BA_REL_ "GenSigFirstTimeoutTime" BU_SG_REL_ VMCU SG_ 1336 TPMSetPresThresCfg_AxleNr_ISig_4 12000;
BA_REL_ "GenSigTimeoutTime" BU_SG_REL_ VMCU SG_ 1336 TPMSetPresThresCfg_AxleNr_ISig_4 3000;
BA_REL_ "GenSigFirstTimeoutTime" BU_SG_REL_ VMCU SG_ 1336 TPMSetPresThresCfg_OverPres_ISig 12000;
BA_REL_ "GenSigTimeoutTime" BU_SG_REL_ VMCU SG_ 1336 TPMSetPresThresCfg_OverPres_ISig 3000;
BA_REL_ "GenSigFirstTimeoutTime" BU_SG_REL_ VMCU SG_ 1336 TPMSetPresThresCfg_ExtUnderPres_ 12000;
BA_REL_ "GenSigTimeoutTime" BU_SG_REL_ VMCU SG_ 1336 TPMSetPresThresCfg_ExtUnderPres_ 3000;
BA_REL_ "GenSigFirstTimeoutTime" BU_SG_REL_ VMCU SG_ 1336 TPMSetPresThresCfg_UnderPres_ISi 12000;
BA_REL_ "GenSigTimeoutTime" BU_SG_REL_ VMCU SG_ 1336 TPMSetPresThresCfg_UnderPres_ISi 3000;
BA_REL_ "GenSigFirstTimeoutTime" BU_SG_REL_ VMCU SG_ 837 TPMIndicationLightReq 3000;
BA_REL_ "GenSigTimeoutTime" BU_SG_REL_ VMCU SG_ 837 TPMIndicationLightReq 300;
BA_REL_ "GenSigFirstTimeoutTime" BU_SG_REL_ CIOM SG_ 837 Regeneration_DeviceInd 3000;
BA_REL_ "GenSigTimeoutTime" BU_SG_REL_ CIOM SG_ 837 Regeneration_DeviceInd 600;
BA_REL_ "GenSigFirstTimeoutTime" BU_SG_REL_ CIOM SG_ 1056 ExtraHeating_rqst_ISig_4 3600;
BA_REL_ "GenSigTimeoutTime" BU_SG_REL_ CIOM SG_ 1056 ExtraHeating_rqst_ISig_4 900;
BA_REL_ "GenSigFirstTimeoutTime" BU_SG_REL_ TECU SG_ 1056 HillDataCtrlTGW_State_ISig_4 12000;
BA_REL_ "GenSigTimeoutTime" BU_SG_REL_ TECU SG_ 1056 HillDataCtrlTGW_State_ISig_4 900;
BA_REL_ "GenSigFirstTimeoutTime" BU_SG_REL_ TECU SG_ 1056 HillDataCtrlTGW_AckCnt_ISig_4 12000;
BA_REL_ "GenSigTimeoutTime" BU_SG_REL_ TECU SG_ 1056 HillDataCtrlTGW_AckCnt_ISig_4 900;
BA_REL_ "GenSigFirstTimeoutTime" BU_SG_REL_ CIOM SG_ 1334 BacklightLevelHighRes2_ISig_4 12000;
BA_REL_ "GenSigTimeoutTime" BU_SG_REL_ CIOM SG_ 1334 BacklightLevelHighRes2_ISig_4 3000;
BA_REL_ "GenSigFirstTimeoutTime" BU_SG_REL_ BBM SG_ 1334 BacklightLevelHighRes2_ISig_4 12000;
BA_REL_ "GenSigTimeoutTime" BU_SG_REL_ BBM SG_ 1334 BacklightLevelHighRes2_ISig_4 3000;
BA_REL_ "GenSigFirstTimeoutTime" BU_SG_REL_ VMCU SG_ 1334 BacklightLevelHighRes2_ISig_4 12000;
BA_REL_ "GenSigTimeoutTime" BU_SG_REL_ VMCU SG_ 1334 BacklightLevelHighRes2_ISig_4 3000;
BA_REL_ "GenSigFirstTimeoutTime" BU_SG_REL_ VMCU SG_ 1334 MaintReset_rqst_Selection 12000;
BA_REL_ "GenSigTimeoutTime" BU_SG_REL_ VMCU SG_ 1334 MaintReset_rqst_Selection 3000;
BA_REL_ "GenSigFirstTimeoutTime" BU_SG_REL_ VMCU SG_ 1334 MaintReset_rqst_Request 12000;
BA_REL_ "GenSigTimeoutTime" BU_SG_REL_ VMCU SG_ 1334 MaintReset_rqst_Request 3000;
BA_REL_ "GenSigFirstTimeoutTime" BU_SG_REL_ EMS SG_ 1334 DPF_ManualRegenerateInhibit 12000;
BA_REL_ "GenSigTimeoutTime" BU_SG_REL_ EMS SG_ 1334 DPF_ManualRegenerateInhibit 3000;
BA_REL_ "GenSigFirstTimeoutTime" BU_SG_REL_ VMCU SG_ 1334 BlackPanel_stat_ISig_4 12000;
BA_REL_ "GenSigTimeoutTime" BU_SG_REL_ VMCU SG_ 1334 BlackPanel_stat_ISig_4 3000;
BA_REL_ "GenSigFirstTimeoutTime" BU_SG_REL_ VMCU SG_ 1334 MaintReset_rqst_ID 12000;
BA_REL_ "GenSigTimeoutTime" BU_SG_REL_ VMCU SG_ 1334 MaintReset_rqst_ID 3000;
BA_REL_ "GenSigFirstTimeoutTime" BU_SG_REL_ EMS SG_ 1334 DPF_ManualRegenerateRequest 12000;
BA_REL_ "GenSigTimeoutTime" BU_SG_REL_ EMS SG_ 1334 DPF_ManualRegenerateRequest 3000;
BA_REL_ "GenSigFirstTimeoutTime" BU_SG_REL_ VMCU SG_ 1377 GPSData_Longitude_ISig_4_561 12000;
BA_REL_ "GenSigTimeoutTime" BU_SG_REL_ VMCU SG_ 1377 GPSData_Longitude_ISig_4_561 3000;
BA_REL_ "GenSigFirstTimeoutTime" BU_SG_REL_ VMCU SG_ 1377 GPSData_Direction_ISig_4_561 12000;
BA_REL_ "GenSigTimeoutTime" BU_SG_REL_ VMCU SG_ 1377 GPSData_Direction_ISig_4_561 3000;
BA_REL_ "GenSigFirstTimeoutTime" BU_SG_REL_ VMCU SG_ 1377 GPSData_Latitude_ISig_4_561 12000;
BA_REL_ "GenSigTimeoutTime" BU_SG_REL_ VMCU SG_ 1377 GPSData_Latitude_ISig_4_561 3000;
BA_REL_ "GenSigFirstTimeoutTime" BU_SG_REL_ VMCU SG_ 1377 GPSData_Altitude_ISig_4_561 12000;
BA_REL_ "GenSigTimeoutTime" BU_SG_REL_ VMCU SG_ 1377 GPSData_Altitude_ISig_4_561 3000;
BA_REL_ "GenSigFirstTimeoutTime" BU_SG_REL_ VMCU SG_ 1377 GPSData_HDOP_ISig_4_561 12000;
BA_REL_ "GenSigTimeoutTime" BU_SG_REL_ VMCU SG_ 1377 GPSData_HDOP_ISig_4_561 3000;
BA_REL_ "GenSigFirstTimeoutTime" BU_SG_REL_ VMCU SG_ 1377 GPSData_Time_ISig_4_561 12000;
BA_REL_ "GenSigTimeoutTime" BU_SG_REL_ VMCU SG_ 1377 GPSData_Time_ISig_4_561 3000;
BA_REL_ "GenSigFirstTimeoutTime" BU_SG_REL_ VMCU SG_ 1377 GPSData_VehSpeed_ISig_4_561 12000;
BA_REL_ "GenSigTimeoutTime" BU_SG_REL_ VMCU SG_ 1377 GPSData_VehSpeed_ISig_4_561 3000;
BA_REL_ "GenSigFirstTimeoutTime" BU_SG_REL_ VMCU SG_ 1377 GPSData_AntennaStat_ISig_4_561 12000;
BA_REL_ "GenSigTimeoutTime" BU_SG_REL_ VMCU SG_ 1377 GPSData_AntennaStat_ISig_4_561 3000;
BA_REL_ "GenSigFirstTimeoutTime" BU_SG_REL_ TECU SG_ 1375 GPSData_HDOP_ISig_4_55f 12000;
BA_REL_ "GenSigTimeoutTime" BU_SG_REL_ TECU SG_ 1375 GPSData_HDOP_ISig_4_55f 3000;
BA_REL_ "GenSigFirstTimeoutTime" BU_SG_REL_ TECU SG_ 1375 GPSData_VehSpeed_ISig_4_55f 12000;
BA_REL_ "GenSigTimeoutTime" BU_SG_REL_ TECU SG_ 1375 GPSData_VehSpeed_ISig_4_55f 3000;
BA_REL_ "GenSigFirstTimeoutTime" BU_SG_REL_ TECU SG_ 1375 GPSData_Direction_ISig_4_55f 12000;
BA_REL_ "GenSigTimeoutTime" BU_SG_REL_ TECU SG_ 1375 GPSData_Direction_ISig_4_55f 3000;
BA_REL_ "GenSigFirstTimeoutTime" BU_SG_REL_ TECU SG_ 1375 GPSData_Longitude_ISig_4_55f 12000;
BA_REL_ "GenSigTimeoutTime" BU_SG_REL_ TECU SG_ 1375 GPSData_Longitude_ISig_4_55f 3000;
BA_REL_ "GenSigFirstTimeoutTime" BU_SG_REL_ TECU SG_ 1375 GPSData_Time_ISig_4_55f 12000;
BA_REL_ "GenSigTimeoutTime" BU_SG_REL_ TECU SG_ 1375 GPSData_Time_ISig_4_55f 3000;
BA_REL_ "GenSigFirstTimeoutTime" BU_SG_REL_ TECU SG_ 1375 GPSData_Latitude_ISig_4_55f 12000;
BA_REL_ "GenSigTimeoutTime" BU_SG_REL_ TECU SG_ 1375 GPSData_Latitude_ISig_4_55f 3000;
BA_REL_ "GenSigFirstTimeoutTime" BU_SG_REL_ TECU SG_ 1375 GPSData_AntennaStat_ISig_4_55f 12000;
BA_REL_ "GenSigTimeoutTime" BU_SG_REL_ TECU SG_ 1375 GPSData_AntennaStat_ISig_4_55f 3000;
BA_REL_ "GenSigFirstTimeoutTime" BU_SG_REL_ TECU SG_ 1375 GPSData_Altitude_ISig_4_55f 12000;
BA_REL_ "GenSigTimeoutTime" BU_SG_REL_ TECU SG_ 1375 GPSData_Altitude_ISig_4_55f 3000;
BA_REL_ "GenSigFirstTimeoutTime" BU_SG_REL_ DACU SG_ 1381 GPSData_HDOP_ISig_4_565 12000;
BA_REL_ "GenSigTimeoutTime" BU_SG_REL_ DACU SG_ 1381 GPSData_HDOP_ISig_4_565 3000;
BA_REL_ "GenSigFirstTimeoutTime" BU_SG_REL_ DACU SG_ 1381 GPSData_VehSpeed_ISig_4_565 12000;
BA_REL_ "GenSigTimeoutTime" BU_SG_REL_ DACU SG_ 1381 GPSData_VehSpeed_ISig_4_565 3000;
BA_REL_ "GenSigFirstTimeoutTime" BU_SG_REL_ DACU SG_ 1381 GPSData_AntennaStat_ISig_4_565 12000;
BA_REL_ "GenSigTimeoutTime" BU_SG_REL_ DACU SG_ 1381 GPSData_AntennaStat_ISig_4_565 3000;
BA_REL_ "GenSigFirstTimeoutTime" BU_SG_REL_ DACU SG_ 1381 GPSData_Latitude_ISig_4_565 12000;
BA_REL_ "GenSigTimeoutTime" BU_SG_REL_ DACU SG_ 1381 GPSData_Latitude_ISig_4_565 3000;
BA_REL_ "GenSigFirstTimeoutTime" BU_SG_REL_ DACU SG_ 1381 GPSData_Time_ISig_4_565 12000;
BA_REL_ "GenSigTimeoutTime" BU_SG_REL_ DACU SG_ 1381 GPSData_Time_ISig_4_565 3000;
BA_REL_ "GenSigFirstTimeoutTime" BU_SG_REL_ DACU SG_ 1381 GPSData_Direction_ISig_4_565 12000;
BA_REL_ "GenSigTimeoutTime" BU_SG_REL_ DACU SG_ 1381 GPSData_Direction_ISig_4_565 3000;
BA_REL_ "GenSigFirstTimeoutTime" BU_SG_REL_ DACU SG_ 1381 GPSData_Longitude_ISig_4_565 12000;
BA_REL_ "GenSigTimeoutTime" BU_SG_REL_ DACU SG_ 1381 GPSData_Longitude_ISig_4_565 3000;
BA_REL_ "GenSigFirstTimeoutTime" BU_SG_REL_ DACU SG_ 1381 GPSData_Altitude_ISig_4_565 12000;
BA_REL_ "GenSigTimeoutTime" BU_SG_REL_ DACU SG_ 1381 GPSData_Altitude_ISig_4_565 3000;
BA_REL_ "GenSigFirstTimeoutTime" BU_SG_REL_ CIOM SG_ 1386 GPSData_HDOP_ISig_4_56a 12000;
BA_REL_ "GenSigTimeoutTime" BU_SG_REL_ CIOM SG_ 1386 GPSData_HDOP_ISig_4_56a 3000;
BA_REL_ "GenSigFirstTimeoutTime" BU_SG_REL_ CIOM SG_ 1386 GPSData_Latitude_ISig_4_56a 12000;
BA_REL_ "GenSigTimeoutTime" BU_SG_REL_ CIOM SG_ 1386 GPSData_Latitude_ISig_4_56a 3000;
BA_REL_ "GenSigFirstTimeoutTime" BU_SG_REL_ CIOM SG_ 1386 GPSData_Time_ISig_4_56a 12000;
BA_REL_ "GenSigTimeoutTime" BU_SG_REL_ CIOM SG_ 1386 GPSData_Time_ISig_4_56a 3000;
BA_REL_ "GenSigFirstTimeoutTime" BU_SG_REL_ CIOM SG_ 1386 GPSData_Direction_ISig_4_56a 12000;
BA_REL_ "GenSigTimeoutTime" BU_SG_REL_ CIOM SG_ 1386 GPSData_Direction_ISig_4_56a 3000;
BA_REL_ "GenSigFirstTimeoutTime" BU_SG_REL_ CIOM SG_ 1386 GPSData_AntennaStat_ISig_4_56a 12000;
BA_REL_ "GenSigTimeoutTime" BU_SG_REL_ CIOM SG_ 1386 GPSData_AntennaStat_ISig_4_56a 3000;
BA_REL_ "GenSigFirstTimeoutTime" BU_SG_REL_ CIOM SG_ 1386 GPSData_Longitude_ISig_4_56a 12000;
BA_REL_ "GenSigTimeoutTime" BU_SG_REL_ CIOM SG_ 1386 GPSData_Longitude_ISig_4_56a 3000;
BA_REL_ "GenSigFirstTimeoutTime" BU_SG_REL_ CIOM SG_ 1386 GPSData_VehSpeed_ISig_4_56a 12000;
BA_REL_ "GenSigTimeoutTime" BU_SG_REL_ CIOM SG_ 1386 GPSData_VehSpeed_ISig_4_56a 3000;
BA_REL_ "GenSigFirstTimeoutTime" BU_SG_REL_ CIOM SG_ 1386 GPSData_Altitude_ISig_4_56a 12000;
BA_REL_ "GenSigTimeoutTime" BU_SG_REL_ CIOM SG_ 1386 GPSData_Altitude_ISig_4_56a 3000;
BA_REL_ "GenSigFirstTimeoutTime" BU_SG_REL_ BBM SG_ 1384 GPSData_Time_ISig_4_568 12000;
BA_REL_ "GenSigTimeoutTime" BU_SG_REL_ BBM SG_ 1384 GPSData_Time_ISig_4_568 3000;
BA_REL_ "GenSigFirstTimeoutTime" BU_SG_REL_ BBM SG_ 1384 GPSData_HDOP_ISig_4_568 12000;
BA_REL_ "GenSigTimeoutTime" BU_SG_REL_ BBM SG_ 1384 GPSData_HDOP_ISig_4_568 3000;
BA_REL_ "GenSigFirstTimeoutTime" BU_SG_REL_ BBM SG_ 1384 GPSData_Direction_ISig_4_568 12000;
BA_REL_ "GenSigTimeoutTime" BU_SG_REL_ BBM SG_ 1384 GPSData_Direction_ISig_4_568 3000;
BA_REL_ "GenSigFirstTimeoutTime" BU_SG_REL_ BBM SG_ 1384 GPSData_Longitude_ISig_4_568 12000;
BA_REL_ "GenSigTimeoutTime" BU_SG_REL_ BBM SG_ 1384 GPSData_Longitude_ISig_4_568 3000;
BA_REL_ "GenSigFirstTimeoutTime" BU_SG_REL_ BBM SG_ 1384 GPSData_VehSpeed_ISig_4_568 12000;
BA_REL_ "GenSigTimeoutTime" BU_SG_REL_ BBM SG_ 1384 GPSData_VehSpeed_ISig_4_568 3000;
BA_REL_ "GenSigFirstTimeoutTime" BU_SG_REL_ BBM SG_ 1384 GPSData_Altitude_ISig_4_568 12000;
BA_REL_ "GenSigTimeoutTime" BU_SG_REL_ BBM SG_ 1384 GPSData_Altitude_ISig_4_568 3000;
BA_REL_ "GenSigFirstTimeoutTime" BU_SG_REL_ BBM SG_ 1384 GPSData_Latitude_ISig_4_568 12000;
BA_REL_ "GenSigTimeoutTime" BU_SG_REL_ BBM SG_ 1384 GPSData_Latitude_ISig_4_568 3000;
BA_REL_ "GenSigFirstTimeoutTime" BU_SG_REL_ BBM SG_ 1384 GPSData_AntennaStat_ISig_4_568 12000;
BA_REL_ "GenSigTimeoutTime" BU_SG_REL_ BBM SG_ 1384 GPSData_AntennaStat_ISig_4_568 3000;
BA_REL_ "GenSigFirstTimeoutTime" BU_SG_REL_ CIOM SG_ 979 PinCodeEntered_value 3000;
BA_REL_ "GenSigTimeoutTime" BU_SG_REL_ CIOM SG_ 979 PinCodeEntered_value 450;
BA_REL_ "GenSigFirstTimeoutTime" BU_SG_REL_ CIOM SG_ 979 DynamicCode_rqst 3000;
BA_REL_ "GenSigTimeoutTime" BU_SG_REL_ CIOM SG_ 979 DynamicCode_rqst 450;
BA_REL_ "GenSigFirstTimeoutTime" BU_SG_REL_ VMCU SG_ 979 LogDisplayedMessage_req 3000;
BA_REL_ "GenSigTimeoutTime" BU_SG_REL_ VMCU SG_ 979 LogDisplayedMessage_req 500;
BA_REL_ "GenSigFirstTimeoutTime" BU_SG_REL_ VMCU SG_ 970 FirstAxleLowerPrioRequested_ISig 3000;
BA_REL_ "GenSigTimeoutTime" BU_SG_REL_ VMCU SG_ 970 FirstAxleLowerPrioRequested_ISig 500;
BA_REL_ "GenSigFirstTimeoutTime" BU_SG_REL_ CIOM SG_ 970 Synch_Unsynch_Mode_stat 3000;
BA_REL_ "GenSigTimeoutTime" BU_SG_REL_ CIOM SG_ 970 Synch_Unsynch_Mode_stat 450;
BA_REL_ "GenSigFirstTimeoutTime" BU_SG_REL_ VMCU SG_ 970 SelectedSpeedUnit_stat_ISig_4 3000;
BA_REL_ "GenSigTimeoutTime" BU_SG_REL_ VMCU SG_ 970 SelectedSpeedUnit_stat_ISig_4 450;
BA_REL_ "GenSigFirstTimeoutTime" BU_SG_REL_ BBM SG_ 970 SelectedLanguage_stat_ISig_4 3000;
BA_REL_ "GenSigTimeoutTime" BU_SG_REL_ BBM SG_ 970 SelectedLanguage_stat_ISig_4 450;
BA_REL_ "GenSigFirstTimeoutTime" BU_SG_REL_ CIOM SG_ 970 SelectedLanguage_stat_ISig_4 3000;
BA_REL_ "GenSigTimeoutTime" BU_SG_REL_ CIOM SG_ 970 SelectedLanguage_stat_ISig_4 450;
BA_REL_ "GenSigFirstTimeoutTime" BU_SG_REL_ VMCU SG_ 970 LampCheck_rqst_ISig_4 3000;
BA_REL_ "GenSigTimeoutTime" BU_SG_REL_ VMCU SG_ 970 LampCheck_rqst_ISig_4 450;
BA_REL_ "GenSigFirstTimeoutTime" BU_SG_REL_ CIOM SG_ 970 SelectedWeightUnit_stat_ISig_4 3000;
BA_REL_ "GenSigTimeoutTime" BU_SG_REL_ CIOM SG_ 970 SelectedWeightUnit_stat_ISig_4 450;
BA_REL_ "GenSigFirstTimeoutTime" BU_SG_REL_ CIOM SG_ 970 SpeedLockingInhibition_stat 3000;
BA_REL_ "GenSigTimeoutTime" BU_SG_REL_ CIOM SG_ 970 SpeedLockingInhibition_stat 450;
BA_REL_ "GenSigFirstTimeoutTime" BU_SG_REL_ CIOM SG_ 970 DriverMemory_rqst_ISig_4 3000;
BA_REL_ "GenSigTimeoutTime" BU_SG_REL_ CIOM SG_ 970 DriverMemory_rqst_ISig_4 450;
BA_REL_ "GenSigFirstTimeoutTime" BU_SG_REL_ VMCU SG_ 970 DriverMemory_rqst_ISig_4 3000;
BA_REL_ "GenSigTimeoutTime" BU_SG_REL_ VMCU SG_ 970 DriverMemory_rqst_ISig_4 450;
BA_REL_ "GenSigFirstTimeoutTime" BU_SG_REL_ CIOM SG_ 970 SelectedTimeFormat_stat_ISig_4 3000;
BA_REL_ "GenSigTimeoutTime" BU_SG_REL_ CIOM SG_ 970 SelectedTimeFormat_stat_ISig_4 450;
BA_REL_ "GenSigFirstTimeoutTime" BU_SG_REL_ VMCU SG_ 970 MaintInfo_rqst 3000;
BA_REL_ "GenSigTimeoutTime" BU_SG_REL_ VMCU SG_ 970 MaintInfo_rqst 450;
BA_REL_ "GenSigFirstTimeoutTime" BU_SG_REL_ DACU SG_ 970 LCSSoundSettingRequest 3000;
BA_REL_ "GenSigTimeoutTime" BU_SG_REL_ DACU SG_ 970 LCSSoundSettingRequest 450;
BA_REL_ "GenSigFirstTimeoutTime" BU_SG_REL_ CIOM SG_ 851 BunkBacklightCmd_ISig_4 3000;
BA_REL_ "GenSigTimeoutTime" BU_SG_REL_ CIOM SG_ 851 BunkBacklightCmd_ISig_4 360;
BA_REL_ "GenSigFirstTimeoutTime" BU_SG_REL_ BBM SG_ 1270 CabLightIntensity_stat_ISig_4 4800;
BA_REL_ "GenSigTimeoutTime" BU_SG_REL_ BBM SG_ 1270 CabLightIntensity_stat_ISig_4 1200;
BA_REL_ "GenSigFirstTimeoutTime" BU_SG_REL_ DACU SG_ 1270 CabLightIntensity_stat_ISig_4 4800;
BA_REL_ "GenSigTimeoutTime" BU_SG_REL_ DACU SG_ 1270 CabLightIntensity_stat_ISig_4 1200;
BA_REL_ "GenSigFirstTimeoutTime" BU_SG_REL_ VMCU SG_ 739 CCBOverspeedRequest 3000;
BA_REL_ "GenSigTimeoutTime" BU_SG_REL_ VMCU SG_ 739 CCBOverspeedRequest 210;
BA_REL_ "GenSigFirstTimeoutTime" BU_SG_REL_ VMCU SG_ 739 ASLDriverRequest 3000;
BA_REL_ "GenSigTimeoutTime" BU_SG_REL_ VMCU SG_ 739 ASLDriverRequest 210;
BA_REL_ "GenSigFirstTimeoutTime" BU_SG_REL_ VMCU SG_ 739 ASLEnableRequest 3000;
BA_REL_ "GenSigTimeoutTime" BU_SG_REL_ VMCU SG_ 739 ASLEnableRequest 210;
BA_REL_ "GenSigFirstTimeoutTime" BU_SG_REL_ CIOM SG_ 739 CCEnableRequest_ISig_4 3000;
BA_REL_ "GenSigTimeoutTime" BU_SG_REL_ CIOM SG_ 739 CCEnableRequest_ISig_4 210;
BA_REL_ "GenSigFirstTimeoutTime" BU_SG_REL_ VMCU SG_ 739 CCEnableRequest_ISig_4 3000;
BA_REL_ "GenSigTimeoutTime" BU_SG_REL_ VMCU SG_ 739 CCEnableRequest_ISig_4 210;
BA_REL_ "GenSigFirstTimeoutTime" BU_SG_REL_ BBM SG_ 739 CCEnableRequest_ISig_4 3000;
BA_REL_ "GenSigTimeoutTime" BU_SG_REL_ BBM SG_ 739 CCEnableRequest_ISig_4 210;
BA_REL_ "GenSigFirstTimeoutTime" BU_SG_REL_ VMCU SG_ 739 CCRequestedPresetSpeed 3000;
BA_REL_ "GenSigTimeoutTime" BU_SG_REL_ VMCU SG_ 739 CCRequestedPresetSpeed 210;
BA_REL_ "GenSigFirstTimeoutTime" BU_SG_REL_ VMCU SG_ 739 CCDriverRequest 3000;
BA_REL_ "GenSigTimeoutTime" BU_SG_REL_ VMCU SG_ 739 CCDriverRequest 210;
BA_REL_ "GenSigFirstTimeoutTime" BU_SG_REL_ BBM SG_ 739 CCDriverRequest 3000;
BA_REL_ "GenSigTimeoutTime" BU_SG_REL_ BBM SG_ 739 CCDriverRequest 210;
BA_REL_ "GenSigFirstTimeoutTime" BU_SG_REL_ VMCU SG_ 739 ASLRequestedPresetSpeed 3000;
BA_REL_ "GenSigTimeoutTime" BU_SG_REL_ VMCU SG_ 739 ASLRequestedPresetSpeed 210;
BA_REL_ "GenSigFirstTimeoutTime" BU_SG_REL_ TECU SG_ 390 EcoRollEnableRequest_ISig_4 3000;
BA_REL_ "GenSigTimeoutTime" BU_SG_REL_ TECU SG_ 390 EcoRollEnableRequest_ISig_4 90;
BA_REL_ "GenSigFirstTimeoutTime" BU_SG_REL_ EMS SG_ 390 SelectedEcoCruiseLevel_ISig_4 12000;
BA_REL_ "GenSigTimeoutTime" BU_SG_REL_ EMS SG_ 390 SelectedEcoCruiseLevel_ISig_4 3000;
BA_REL_ "GenSigFirstTimeoutTime" BU_SG_REL_ DACU SG_ 390 SelectedEcoCruiseLevel_ISig_4 3000;
BA_REL_ "GenSigTimeoutTime" BU_SG_REL_ DACU SG_ 390 SelectedEcoCruiseLevel_ISig_4 90;
BA_REL_ "GenSigFirstTimeoutTime" BU_SG_REL_ TECU SG_ 390 SelectedEcoCruiseLevel_ISig_4 3000;
BA_REL_ "GenSigTimeoutTime" BU_SG_REL_ TECU SG_ 390 SelectedEcoCruiseLevel_ISig_4 90;
BA_REL_ "GenSigFirstTimeoutTime" BU_SG_REL_ VMCU SG_ 390 SelectedEcoCruiseLevel_ISig_4 3000;
BA_REL_ "GenSigTimeoutTime" BU_SG_REL_ VMCU SG_ 390 SelectedEcoCruiseLevel_ISig_4 90;
BA_REL_ "GenSigFirstTimeoutTime" BU_SG_REL_ VMCU SG_ 514 PS_GearSelectionMode_ISig_4 3000;
BA_REL_ "GenSigTimeoutTime" BU_SG_REL_ VMCU SG_ 514 PS_GearSelectionMode_ISig_4 150;
BA_REL_ "GenSigFirstTimeoutTime" BU_SG_REL_ EMS SG_ 514 WaterInFuelDrainRequest 3000;
BA_REL_ "GenSigTimeoutTime" BU_SG_REL_ EMS SG_ 514 WaterInFuelDrainRequest 150;
BA_REL_ "GenSigFirstTimeoutTime" BU_SG_REL_ VMCU SG_ 514 FuncIndIlluminationLevel_ISig_4 3000;
BA_REL_ "GenSigTimeoutTime" BU_SG_REL_ VMCU SG_ 514 FuncIndIlluminationLevel_ISig_4 150;
BA_REL_ "GenSigFirstTimeoutTime" BU_SG_REL_ CIOM SG_ 514 FuncIndIlluminationLevel_ISig_4 3000;
BA_REL_ "GenSigTimeoutTime" BU_SG_REL_ CIOM SG_ 514 FuncIndIlluminationLevel_ISig_4 150;
BA_REL_ "GenSigFirstTimeoutTime" BU_SG_REL_ DACU SG_ 514 ResumeRequestForACC 3000;
BA_REL_ "GenSigTimeoutTime" BU_SG_REL_ DACU SG_ 514 ResumeRequestForACC 150;
BA_REL_ "GenSigFirstTimeoutTime" BU_SG_REL_ VMCU SG_ 514 SWSpeedControlAdjustMode 3000;
BA_REL_ "GenSigTimeoutTime" BU_SG_REL_ VMCU SG_ 514 SWSpeedControlAdjustMode 150;
BA_REL_ "GenSigFirstTimeoutTime" BU_SG_REL_ CIOM SG_ 514 SWSpeedControlAdjustMode 3000;
BA_REL_ "GenSigTimeoutTime" BU_SG_REL_ CIOM SG_ 514 SWSpeedControlAdjustMode 150;
BA_REL_ "GenSigFirstTimeoutTime" BU_SG_REL_ DACU SG_ 514 ACCTimeGapRqst 3000;
BA_REL_ "GenSigTimeoutTime" BU_SG_REL_ DACU SG_ 514 ACCTimeGapRqst 150;
BA_REL_ "GenSigFirstTimeoutTime" BU_SG_REL_ CIOM SG_ 514 SWSpdCtrlButtonsStatus6 3000;
BA_REL_ "GenSigTimeoutTime" BU_SG_REL_ CIOM SG_ 514 SWSpdCtrlButtonsStatus6 150;
BA_REL_ "GenSigFirstTimeoutTime" BU_SG_REL_ VMCU SG_ 514 ACCEnableRqst 3000;
BA_REL_ "GenSigTimeoutTime" BU_SG_REL_ VMCU SG_ 514 ACCEnableRqst 150;
BA_REL_ "GenSigFirstTimeoutTime" BU_SG_REL_ DACU SG_ 514 ACCEnableRqst 3000;
BA_REL_ "GenSigTimeoutTime" BU_SG_REL_ DACU SG_ 514 ACCEnableRqst 150;
BA_REL_ "GenSigFirstTimeoutTime" BU_SG_REL_ CIOM SG_ 514 ACCEnableRqst 3000;
BA_REL_ "GenSigTimeoutTime" BU_SG_REL_ CIOM SG_ 514 ACCEnableRqst 150;
BA_REL_ "GenSigFirstTimeoutTime" BU_SG_REL_ VMCU SG_ 514 StopAlert_cmd 3000;
BA_REL_ "GenSigTimeoutTime" BU_SG_REL_ VMCU SG_ 514 StopAlert_cmd 150;
BA_REL_ "GenSigFirstTimeoutTime" BU_SG_REL_ CIOM SG_ 514 BacklightCmd_ISig_4 3000;
BA_REL_ "GenSigTimeoutTime" BU_SG_REL_ CIOM SG_ 514 BacklightCmd_ISig_4 150;
BA_REL_ "GenSigFirstTimeoutTime" BU_SG_REL_ VMCU SG_ 514 BacklightCmd_ISig_4 3000;
BA_REL_ "GenSigTimeoutTime" BU_SG_REL_ VMCU SG_ 514 BacklightCmd_ISig_4 150;
BA_REL_ "GenSigFirstTimeoutTime" BU_SG_REL_ DACU SG_ 514 CMTelltale_stat 3000;
BA_REL_ "GenSigTimeoutTime" BU_SG_REL_ DACU SG_ 514 CMTelltale_stat 150;
BA_REL_ "GenSigFirstTimeoutTime" BU_SG_REL_ VMCU SG_ 1288 EcoCruisePwtMaxOvSpeedLev3 24000;
BA_REL_ "GenSigTimeoutTime" BU_SG_REL_ VMCU SG_ 1288 EcoCruisePwtMaxOvSpeedLev3 6000;
BA_REL_ "GenSigFirstTimeoutTime" BU_SG_REL_ VMCU SG_ 1288 EcoCruisePwtMaxOvSpeedLev0 24000;
BA_REL_ "GenSigTimeoutTime" BU_SG_REL_ VMCU SG_ 1288 EcoCruisePwtMaxOvSpeedLev0 6000;
BA_REL_ "GenSigFirstTimeoutTime" BU_SG_REL_ VMCU SG_ 1288 EcoCruisePwtMaxUnSpeedLev0 24000;
BA_REL_ "GenSigTimeoutTime" BU_SG_REL_ VMCU SG_ 1288 EcoCruisePwtMaxUnSpeedLev0 6000;
BA_REL_ "GenSigFirstTimeoutTime" BU_SG_REL_ VMCU SG_ 1288 EcoCruisePwtMaxOvSpeedLev2 24000;
BA_REL_ "GenSigTimeoutTime" BU_SG_REL_ VMCU SG_ 1288 EcoCruisePwtMaxOvSpeedLev2 6000;
BA_REL_ "GenSigFirstTimeoutTime" BU_SG_REL_ VMCU SG_ 1288 EcoCruisePwtMaxOvSpeedLev1 24000;
BA_REL_ "GenSigTimeoutTime" BU_SG_REL_ VMCU SG_ 1288 EcoCruisePwtMaxOvSpeedLev1 6000;
BA_REL_ "GenSigFirstTimeoutTime" BU_SG_REL_ VMCU SG_ 1288 EcoCruisePwtMaxUnSpeedLev3 24000;
BA_REL_ "GenSigTimeoutTime" BU_SG_REL_ VMCU SG_ 1288 EcoCruisePwtMaxUnSpeedLev3 6000;
BA_REL_ "GenSigFirstTimeoutTime" BU_SG_REL_ VMCU SG_ 1288 EcoCruisePwtMaxUnSpeedLev1 24000;
BA_REL_ "GenSigTimeoutTime" BU_SG_REL_ VMCU SG_ 1288 EcoCruisePwtMaxUnSpeedLev1 6000;
BA_REL_ "GenSigFirstTimeoutTime" BU_SG_REL_ VMCU SG_ 1288 EcoCruisePwtMaxUnSpeedLev2 24000;
BA_REL_ "GenSigTimeoutTime" BU_SG_REL_ VMCU SG_ 1288 EcoCruisePwtMaxUnSpeedLev2 6000;
BA_REL_ "GenSigFirstTimeoutTime" BU_SG_REL_ VMCU SG_ 1285 TotPTOLNGHighAccuracy 24000;
BA_REL_ "GenSigTimeoutTime" BU_SG_REL_ VMCU SG_ 1285 TotPTOLNGHighAccuracy 6000;
BA_REL_ "GenSigFirstTimeoutTime" BU_SG_REL_ VMCU SG_ 1282 ExhManif_EMAIAirTankPres_ISig_4 12000;
BA_REL_ "GenSigTimeoutTime" BU_SG_REL_ VMCU SG_ 1282 ExhManif_EMAIAirTankPres_ISig_4 3000;
BA_REL_ "GenSigFirstTimeoutTime" BU_SG_REL_ VMCU SG_ 1282 EngineFuelMode 12000;
BA_REL_ "GenSigTimeoutTime" BU_SG_REL_ VMCU SG_ 1282 EngineFuelMode 3000;
BA_REL_ "GenSigFirstTimeoutTime" BU_SG_REL_ IC3 SG_ 1282 LNGOperatorInducementReason 12000;
BA_REL_ "GenSigTimeoutTime" BU_SG_REL_ IC3 SG_ 1282 LNGOperatorInducementReason 3000;
BA_REL_ "GenSigFirstTimeoutTime" BU_SG_REL_ IC3 SG_ 1282 DPF_RegenCompleted 12000;
BA_REL_ "GenSigTimeoutTime" BU_SG_REL_ IC3 SG_ 1282 DPF_RegenCompleted 3000;
BA_REL_ "GenSigFirstTimeoutTime" BU_SG_REL_ CIOM SG_ 1282 EngineTotalLngConsumed_ISig_4 12000;
BA_REL_ "GenSigTimeoutTime" BU_SG_REL_ CIOM SG_ 1282 EngineTotalLngConsumed_ISig_4 3000;
BA_REL_ "GenSigFirstTimeoutTime" BU_SG_REL_ IC3 SG_ 1282 EngineTotalLngConsumed_ISig_4 12000;
BA_REL_ "GenSigTimeoutTime" BU_SG_REL_ IC3 SG_ 1282 EngineTotalLngConsumed_ISig_4 3000;
BA_REL_ "GenSigFirstTimeoutTime" BU_SG_REL_ VMCU SG_ 1282 EngineTotalLngConsumed_ISig_4 12000;
BA_REL_ "GenSigTimeoutTime" BU_SG_REL_ VMCU SG_ 1282 EngineTotalLngConsumed_ISig_4 3000;
BA_REL_ "GenSigFirstTimeoutTime" BU_SG_REL_ IC3 SG_ 1252 DistLeftToSevereInducement_OBD 24000;
BA_REL_ "GenSigTimeoutTime" BU_SG_REL_ IC3 SG_ 1252 DistLeftToSevereInducement_OBD 6000;
BA_REL_ "GenSigFirstTimeoutTime" BU_SG_REL_ IC3 SG_ 1252 TopGearUseDistance_ISig_4 24000;
BA_REL_ "GenSigTimeoutTime" BU_SG_REL_ IC3 SG_ 1252 TopGearUseDistance_ISig_4 6000;
BA_REL_ "GenSigFirstTimeoutTime" BU_SG_REL_ IC3 SG_ 1374 TimeLeftToTorqueReduction_OBD 24000;
BA_REL_ "GenSigTimeoutTime" BU_SG_REL_ IC3 SG_ 1374 TimeLeftToTorqueReduction_OBD 6000;
BA_REL_ "GenSigFirstTimeoutTime" BU_SG_REL_ VMCU SG_ 1374 AdblueTotalConsumed_ISig_4 24000;
BA_REL_ "GenSigTimeoutTime" BU_SG_REL_ VMCU SG_ 1374 AdblueTotalConsumed_ISig_4 6000;
BA_REL_ "GenSigFirstTimeoutTime" BU_SG_REL_ IC3 SG_ 1374 AdblueTotalConsumed_ISig_4 24000;
BA_REL_ "GenSigTimeoutTime" BU_SG_REL_ IC3 SG_ 1374 AdblueTotalConsumed_ISig_4 6000;
BA_REL_ "GenSigFirstTimeoutTime" BU_SG_REL_ VMCU SG_ 1374 MIStatus_ISig_4 24000;
BA_REL_ "GenSigTimeoutTime" BU_SG_REL_ VMCU SG_ 1374 MIStatus_ISig_4 6000;
BA_REL_ "GenSigFirstTimeoutTime" BU_SG_REL_ IC3 SG_ 1374 MIStatus_ISig_4 24000;
BA_REL_ "GenSigTimeoutTime" BU_SG_REL_ IC3 SG_ 1374 MIStatus_ISig_4 6000;
BA_REL_ "GenSigFirstTimeoutTime" BU_SG_REL_ IC3 SG_ 1374 TorqueReductionStatus_OBD 24000;
BA_REL_ "GenSigTimeoutTime" BU_SG_REL_ IC3 SG_ 1374 TorqueReductionStatus_OBD 6000;
BA_REL_ "GenSigFirstTimeoutTime" BU_SG_REL_ IC3 SG_ 1374 SCROperatorInducementSeverity 24000;
BA_REL_ "GenSigTimeoutTime" BU_SG_REL_ IC3 SG_ 1374 SCROperatorInducementSeverity 6000;
BA_REL_ "GenSigFirstTimeoutTime" BU_SG_REL_ IC3 SG_ 1374 SCROperatorInducementReason 24000;
BA_REL_ "GenSigTimeoutTime" BU_SG_REL_ IC3 SG_ 1374 SCROperatorInducementReason 6000;
BA_REL_ "GenSigFirstTimeoutTime" BU_SG_REL_ VMCU SG_ 1374 MIDistinctWarning 24000;
BA_REL_ "GenSigTimeoutTime" BU_SG_REL_ VMCU SG_ 1374 MIDistinctWarning 6000;
BA_REL_ "GenSigFirstTimeoutTime" BU_SG_REL_ IC3 SG_ 1374 MIDistinctWarning 24000;
BA_REL_ "GenSigTimeoutTime" BU_SG_REL_ IC3 SG_ 1374 MIDistinctWarning 6000;
BA_REL_ "GenSigFirstTimeoutTime" BU_SG_REL_ IC3 SG_ 1374 MIStatusExtEMS 24000;
BA_REL_ "GenSigTimeoutTime" BU_SG_REL_ IC3 SG_ 1374 MIStatusExtEMS 6000;
BA_REL_ "GenSigFirstTimeoutTime" BU_SG_REL_ VMCU SG_ 1374 MIDistinctWarningExtEMS_ISig_4 24000;
BA_REL_ "GenSigTimeoutTime" BU_SG_REL_ VMCU SG_ 1374 MIDistinctWarningExtEMS_ISig_4 6000;
BA_REL_ "GenSigFirstTimeoutTime" BU_SG_REL_ IC3 SG_ 1374 MIDistinctWarningExtEMS_ISig_4 24000;
BA_REL_ "GenSigTimeoutTime" BU_SG_REL_ IC3 SG_ 1374 MIDistinctWarningExtEMS_ISig_4 6000;
BA_REL_ "GenSigFirstTimeoutTime" BU_SG_REL_ BBM SG_ 1392 EngineRunningTime_ISig_4 28800;
BA_REL_ "GenSigTimeoutTime" BU_SG_REL_ BBM SG_ 1392 EngineRunningTime_ISig_4 7200;
BA_REL_ "GenSigFirstTimeoutTime" BU_SG_REL_ IC3 SG_ 1392 EngineRunningTime_ISig_4 28800;
BA_REL_ "GenSigTimeoutTime" BU_SG_REL_ IC3 SG_ 1392 EngineRunningTime_ISig_4 7200;
BA_REL_ "GenSigFirstTimeoutTime" BU_SG_REL_ VMCU SG_ 1392 EngineRunningTime_ISig_4 28800;
BA_REL_ "GenSigTimeoutTime" BU_SG_REL_ VMCU SG_ 1392 EngineRunningTime_ISig_4 7200;
BA_REL_ "GenSigFirstTimeoutTime" BU_SG_REL_ CIOM SG_ 1392 EngineRunningTime_ISig_4 28800;
BA_REL_ "GenSigTimeoutTime" BU_SG_REL_ CIOM SG_ 1392 EngineRunningTime_ISig_4 7200;
BA_REL_ "GenSigFirstTimeoutTime" BU_SG_REL_ VMCU SG_ 1392 TotPTOFuelHighAccuracy 28800;
BA_REL_ "GenSigTimeoutTime" BU_SG_REL_ VMCU SG_ 1392 TotPTOFuelHighAccuracy 7200;
BA_REL_ "GenSigFirstTimeoutTime" BU_SG_REL_ CIOM SG_ 1391 OilPrediction_Quality 36000;
BA_REL_ "GenSigTimeoutTime" BU_SG_REL_ CIOM SG_ 1391 OilPrediction_Quality 9000;
BA_REL_ "GenSigFirstTimeoutTime" BU_SG_REL_ VMCU SG_ 1391 OilPrediction_Quality 36000;
BA_REL_ "GenSigTimeoutTime" BU_SG_REL_ VMCU SG_ 1391 OilPrediction_Quality 9000;
BA_REL_ "GenSigFirstTimeoutTime" BU_SG_REL_ IC3 SG_ 1391 TimeLeftToVehSpdReduction_OBD 36000;
BA_REL_ "GenSigTimeoutTime" BU_SG_REL_ IC3 SG_ 1391 TimeLeftToVehSpdReduction_OBD 9000;
BA_REL_ "GenSigFirstTimeoutTime" BU_SG_REL_ CIOM SG_ 1391 OilPrediction_RemainDist 36000;
BA_REL_ "GenSigTimeoutTime" BU_SG_REL_ CIOM SG_ 1391 OilPrediction_RemainDist 9000;
BA_REL_ "GenSigFirstTimeoutTime" BU_SG_REL_ VMCU SG_ 1391 OilPrediction_RemainDist 36000;
BA_REL_ "GenSigTimeoutTime" BU_SG_REL_ VMCU SG_ 1391 OilPrediction_RemainDist 9000;
BA_REL_ "GenSigFirstTimeoutTime" BU_SG_REL_ IC3 SG_ 1391 TimeToCorrectOilLevel_ISig_4 36000;
BA_REL_ "GenSigTimeoutTime" BU_SG_REL_ IC3 SG_ 1391 TimeToCorrectOilLevel_ISig_4 9000;
BA_REL_ "GenSigFirstTimeoutTime" BU_SG_REL_ VMCU SG_ 1391 OilPrediction_RemainTime 36000;
BA_REL_ "GenSigTimeoutTime" BU_SG_REL_ VMCU SG_ 1391 OilPrediction_RemainTime 9000;
BA_REL_ "GenSigFirstTimeoutTime" BU_SG_REL_ CIOM SG_ 1391 OilPrediction_RemainTime 36000;
BA_REL_ "GenSigTimeoutTime" BU_SG_REL_ CIOM SG_ 1391 OilPrediction_RemainTime 9000;
BA_REL_ "GenSigFirstTimeoutTime" BU_SG_REL_ CIOM SG_ 1391 OilPrediction_Status 36000;
BA_REL_ "GenSigTimeoutTime" BU_SG_REL_ CIOM SG_ 1391 OilPrediction_Status 9000;
BA_REL_ "GenSigFirstTimeoutTime" BU_SG_REL_ VMCU SG_ 1391 OilPrediction_Status 36000;
BA_REL_ "GenSigTimeoutTime" BU_SG_REL_ VMCU SG_ 1391 OilPrediction_Status 9000;
VAL_ 1443 SaveTrlrName_rqst_Request 3 "InactiveActive_NotAvailable" 2 "InactiveActive_Error" 1 "InactiveActive_Active" 0 "InactiveActive_Inactive" ;
VAL_ 1443 SaveTrlrName_rqst_Position 7 "TrailerPosition_NotAvailable" 6 "TrailerPosition_Error" 5 "TrailerPosition_Trailer5" 4 "TrailerPosition_Trailer4" 3 "TrailerPosition_Trailer3" 2 "TrailerPosition_Trailer2" 1 "TrailerPosition_Trailer1" 0 "TrailerPosition_NotConnected" ;
VAL_ 1256 AlmClkSetAlarm_rqst_Stat 3 "AlarmClkStat2_Snoozed" 2 "AlarmClkStat2_Ringing" 1 "AlarmClkStat2_Active" 0 "AlarmClkStat2_Inactive" ;
VAL_ 1256 AlmClkSetAlarm_rqst_Mode 3 "AlarmClkMode_Spare" 2 "AlarmClkMode_Timer" 1 "AlarmClkMode_Recurrent" 0 "AlarmClkMode_OneTime" ;
VAL_ 1256 AlmClkSetAlarm_rqst_ID 127 "AlarmClkID_NotAvailable" 126 "AlarmClkID_Error" 10 "AlarmClkID_Alarm10" 9 "AlarmClkID_Alarm9" 8 "AlarmClkID_Alarm8" 7 "AlarmClkID_Alarm7" 6 "AlarmClkID_Alarm6" 5 "AlarmClkID_Alarm5" 4 "AlarmClkID_Alarm4" 3 "AlarmClkID_Alarm3" 2 "AlarmClkID_Alarm2" 1 "AlarmClkID_Alarm1" 0 "AlarmClkID_NotUsed" ;
VAL_ 1256 AlmClkSetAlarm_rqst_Type 7 "AlarmClkType_NotAvailable" 6 "AlarmClkType_Error" 5 "AlarmClkType_Reserved_02" 4 "AlarmClkType_Reserved_01" 3 "AlarmClkType_Reserved" 2 "AlarmClkType_Radio" 1 "AlarmClkType_Buzzer" 0 "AlarmClkType_NoAudibleNotification" ;
VAL_ 1256 AlmClkSnze_rqst_ID 127 "AlarmClkID_NotAvailable" 126 "AlarmClkID_Error" 10 "AlarmClkID_Alarm10" 9 "AlarmClkID_Alarm9" 8 "AlarmClkID_Alarm8" 7 "AlarmClkID_Alarm7" 6 "AlarmClkID_Alarm6" 5 "AlarmClkID_Alarm5" 4 "AlarmClkID_Alarm4" 3 "AlarmClkID_Alarm3" 2 "AlarmClkID_Alarm2" 1 "AlarmClkID_Alarm1" 0 "AlarmClkID_NotUsed" ;
VAL_ 1256 AlmClkSnze_rqst_Action 7 "AlmClkSnzeAction_NotAvailable" 6 "AlmClkSnzeAction_Error" 5 "AlmClkSnzeAction_Spare02" 4 "AlmClkSnzeAction_Spare01" 3 "AlmClkSnzeAction_Spare" 2 "AlmClkSnzeAction_RequestToTurnAlarmOff" 1 "AlmClkSnzeAction_RequestToSnoozeAlarm" 0 "AlmClkSnzeAction_NoRequest" ;
VAL_ 839 UpdParkClimTimerRqst_TimerCmd_IS 7 "PhTimer_cmd_NotAvailable" 6 "PhTimer_cmd_Error" 5 "PhTimer_cmd_Spare_02" 4 "PhTimer_cmd_Spare_01" 3 "PhTimer_cmd_TimerDeleted" 2 "PhTimer_cmd_TimerDisable" 1 "PhTimer_cmd_TimerEnable" 0 "PhTimer_cmd_NoAction" ;
VAL_ 838 AirbagTelltale_stat_ISig_4 3 "OffOn_NotAvailable" 2 "OffOn_Error" 1 "OffOn_On" 0 "OffOn_Off" ;
VAL_ 838 AQSModeRqst_ISig_4 7 "AQSModeRqst_NotAvailable" 6 "AQSModeRqst_Error" 5 "AQSModeRqst_Spare3" 4 "AQSModeRqst_Spare2" 3 "AQSModeRqst_Spare1" 2 "AQSModeRqst_Auto" 1 "AQSModeRqst_Off" 0 "AQSModeRqst_NoAction" ;
VAL_ 838 VCSystPowerSupply_rqst 3 "InactiveActive_NotAvailable" 2 "InactiveActive_Error" 1 "InactiveActive_Active" 0 "InactiveActive_Inactive" ;
VAL_ 838 ISeeEnableRequest 3 "InactiveActive_NotAvailable" 2 "InactiveActive_Error" 1 "InactiveActive_Active" 0 "InactiveActive_Inactive" ;
VAL_ 838 ACModeRqst_ISig_4 7 "ACModeReq_NotAvailable" 6 "ACModeReq_Error" 5 "ACModeReq_Spare" 4 "ACModeReq_ExtraDryCabAir" 3 "ACModeReq_HumidCabAir" 2 "ACModeReq_Standard" 1 "ACModeReq_Economy" 0 "ACModeReq_NoAction" ;
VAL_ 838 RemoteParkClimateRqst_ISig_4 7 "RemoteParkingClimateRqst_NotAvailable" 6 "RemoteParkingClimateRqst_Error" 5 "RemoteParkingClimateRqst_Spare_03" 4 "RemoteParkingClimateRqst_Spare_02" 3 "RemoteParkingClimateRqst_Spare_01" 2 "RemoteParkingClimateRqst_DisableRequest" 1 "RemoteParkingClimateRqst_EnableRequest" 0 "RemoteParkingClimateRqst_NoAction" ;
VAL_ 838 CalDataLoad_rqst_VehicleID 7 "VehicleID_NotAvailable" 6 "VehicleID_Error" 5 "VehicleID_Trailer5" 4 "VehicleID_Trailer4" 3 "VehicleID_Trailer3" 2 "VehicleID_Trailer2" 1 "VehicleID_Trailer1" 0 "VehicleID_Truck" ;
VAL_ 838 CalDataLoad_rqst_AxleID 15 "AxleIdEnum_NotAvailable" 14 "AxleIdEnum_Error" 13 "AxleIdEnum_Reserved4" 12 "AxleIdEnum_Reserved3" 11 "AxleIdEnum_Reserved2" 10 "AxleIdEnum_Reserved1" 9 "AxleIdEnum_AxleID10" 8 "AxleIdEnum_AxleID9" 7 "AxleIdEnum_AxleID8" 6 "AxleIdEnum_AxleID7" 5 "AxleIdEnum_AxleID6" 4 "AxleIdEnum_AxleID5" 3 "AxleIdEnum_AxleID4" 2 "AxleIdEnum_AxleID3" 1 "AxleIdEnum_AxleID2" 0 "AxleIdEnum_AxleID1" ;
VAL_ 838 AutoBlowerLevelRqst_ISig_4 7 "AutoBlowerLevelRqst_NotAvailable" 6 "AutoBlowerLevelRqst_Error" 3 "AutoBlowerLevelRqst_Low" 2 "AutoBlowerLevelRqst_Normal" 1 "AutoBlowerLevelRqst_High" 0 "AutoBlowerLevelRqst_NoAction" ;
VAL_ 838 AutoDefogModeRqst_ISig_4 7 "AutoDefogModeRqst_NotAvailable" 6 "AutoDefogModeRqst_Error" 5 "AutoDefogModeRqst_Spare" 4 "AutoDefogModeRqst_Moderate" 3 "AutoDefogModeRqst_Normal" 2 "AutoDefogModeRqst_Sensitive" 1 "AutoDefogModeRqst_Off" 0 "AutoDefogModeRqst_NoAction" ;
VAL_ 515 SetParkClimTimerRqst_Mon_ISig_4 1 "NotSelectedSelected_Selected" 0 "NotSelectedSelected_NotSelected" ;
VAL_ 515 SetParkClimTimerRqst_Tue_ISig_4 1 "NotSelectedSelected_Selected" 0 "NotSelectedSelected_NotSelected" ;
VAL_ 515 SetParkClimTimerRqst_Sat_ISig_4 1 "NotSelectedSelected_Selected" 0 "NotSelectedSelected_NotSelected" ;
VAL_ 515 SetParkClimTimerRqst_Type_ISig_4 7 "TimerType_NotAvailable" 6 "TimerType_Error" 5 "TimerType_Spare3" 4 "TimerType_Spare2" 3 "TimerType_Spare1" 2 "TimerType_CabClimateTimerWithStartTime" 1 "TimerType_EngineTimerWithReadyTime" 0 "TimerType_CabClimateTimerWithReadyTime" ;
VAL_ 515 SetParkClimTimerRqst_Sun_ISig_4 1 "NotSelectedSelected_Selected" 0 "NotSelectedSelected_NotSelected" ;
VAL_ 515 SetParkClimTimerRqst_Wed_ISig_4 1 "NotSelectedSelected_Selected" 0 "NotSelectedSelected_NotSelected" ;
VAL_ 515 SetParkClimTimerRqst_Thu_ISig_4 1 "NotSelectedSelected_Selected" 0 "NotSelectedSelected_NotSelected" ;
VAL_ 515 SetParkClimTimerRqst_TimerCmd_IS 7 "PhTimer_cmd_NotAvailable" 6 "PhTimer_cmd_Error" 5 "PhTimer_cmd_Spare_02" 4 "PhTimer_cmd_Spare_01" 3 "PhTimer_cmd_TimerDeleted" 2 "PhTimer_cmd_TimerDisable" 1 "PhTimer_cmd_TimerEnable" 0 "PhTimer_cmd_NoAction" ;
VAL_ 515 SetParkClimTimerRqst_Fri_ISig_4 1 "NotSelectedSelected_Selected" 0 "NotSelectedSelected_NotSelected" ;
VAL_ 515 SetParkClimTimerRqst_Rec_ISig_4 1 "Rec_Recurrent" 0 "Rec_Once" ;
VAL_ 1422 FasUsrDefinedStorage_rqst_ISig_4 3 "FasUsrDefinedStorage_NotAvailable" 2 "FasUsrDefinedStorage_Error" 1 "FasUsrDefinedStorage_StoreUserDefinedSetting" 0 "FasUsrDefinedStorage_DoNotStoreUserDefinedSetting" ;
VAL_ 1422 ATC_ButtonIndication 3 "DeviceIndication_SpareValue" 2 "DeviceIndication_Blink" 1 "DeviceIndication_On" 0 "DeviceIndication_Off" ;
VAL_ 1422 FasPersonalSettingsButton_rqst_I 7 "FasPersSettingsButton_NotAvailable" 6 "FasPersSettingsButton_Error" 5 "FasPersSettingsButton_Spare" 4 "FasPersSettingsButton_UserDefinedButton" 3 "FasPersSettingsButton_PresetButtonHeavy" 2 "FasPersSettingsButton_PresetButtonFirm" 1 "FasPersSettingsButton_PresetButtonLight" 0 "FasPersSettingsButton_PresetButtonDefault" ;
VAL_ 1422 FasDriver_rqst_ISig_4 15 "FasDriver_NotAvailable" 14 "FasDriver_Error" 13 "FasDriver_Spare3" 12 "FasDriver_Spare2" 11 "FasDriver_Spare1" 10 "FasDriver_Driver10" 9 "FasDriver_Driver9" 8 "FasDriver_Driver8" 7 "FasDriver_Driver7" 6 "FasDriver_Driver6" 5 "FasDriver_Driver5" 4 "FasDriver_Driver4" 3 "FasDriver_Driver3" 2 "FasDriver_Driver2" 1 "FasDriver_Driver1" 0 "FasDriver_DefaultDriver" ;
VAL_ 1422 ESC_ButtonIndication2 3 "DeviceIndication_SpareValue" 2 "DeviceIndication_Blink" 1 "DeviceIndication_On" 0 "DeviceIndication_Off" ;
VAL_ 1422 TCS_ButtonIndication 3 "DeviceIndication_SpareValue" 2 "DeviceIndication_Blink" 1 "DeviceIndication_On" 0 "DeviceIndication_Off" ;
VAL_ 1422 ABS_ButtonIndication 3 "DeviceIndication_SpareValue" 2 "DeviceIndication_Blink" 1 "DeviceIndication_On" 0 "DeviceIndication_Off" ;
VAL_ 1421 ESCOff_DeviceIndication 3 "DeviceIndication_SpareValue" 2 "DeviceIndication_Blink" 1 "DeviceIndication_On" 0 "DeviceIndication_Off" ;
VAL_ 1421 DHCActiveRequest 3 "OffOn_NotAvailable" 2 "OffOn_Error" 1 "OffOn_On" 0 "OffOn_Off" ;
VAL_ 1421 RollerBenchGUIDeviceStatus 3 "OffOn_NotAvailable" 2 "OffOn_Error" 1 "OffOn_On" 0 "OffOn_Off" ;
VAL_ 1421 DHCSetSpeedAdjustRequest 7 "SpeedAdjustRequest_NotAvailable" 6 "SpeedAdjustRequest_Error" 5 "SpeedAdjustRequest_Spare2" 4 "SpeedAdjustRequest_Spare1" 3 "SpeedAdjustRequest_Decrease" 2 "SpeedAdjustRequest_Increase" 1 "SpeedAdjustRequest_Set" 0 "SpeedAdjustRequest_NoRequest" ;
VAL_ 1421 AutomaticCMenableStatus 3 "OffOn_NotAvailable" 2 "OffOn_Error" 1 "OffOn_On" 0 "OffOn_Off" ;
VAL_ 1421 SetDaylightSaving_rqst 3 "DaylightSaving_NotAvailable" 2 "DaylightSaving_Error" 1 "DaylightSaving_DaylightSaving" 0 "DaylightSaving_Standard" ;
VAL_ 1421 CamerasPowerSupply_rqst 3 "InactiveActive_NotAvailable" 2 "InactiveActive_Error" 1 "InactiveActive_Active" 0 "InactiveActive_Inactive" ;
VAL_ 1421 AFSActiveAllowedInDP_GUIrqst 3 "InactiveActive_NotAvailable" 2 "InactiveActive_Error" 1 "InactiveActive_Active" 0 "InactiveActive_Inactive" ;
VAL_ 949 MediaSourcesListRsp_SInfo_ISig_4 3 "SignalInfo2bitType_NotAvailable" 2 "SignalInfo2bitType_ErrorIndication" 1 "SignalInfo2bitType_Spare" 0 "SignalInfo2bitType_Valid" ;
VAL_ 822 SEMMediaSourceAvail_Source04_ISi 1 "Bitfield1BitType_True" 0 "Bitfield1BitType_False" ;
VAL_ 822 SEMMediaSourceAvail_Source10_ISi 1 "Bitfield1BitType_True" 0 "Bitfield1BitType_False" ;
VAL_ 822 SEMMediaSourceAvail_SInfo_ISig_4 3 "SignalInfo2bitType_NotAvailable" 2 "SignalInfo2bitType_ErrorIndication" 1 "SignalInfo2bitType_Spare" 0 "SignalInfo2bitType_Valid" ;
VAL_ 822 SEMMediaSourceAvail_Source09_ISi 1 "Bitfield1BitType_True" 0 "Bitfield1BitType_False" ;
VAL_ 822 SEMMediaSourceAvail_Source12_ISi 1 "Bitfield1BitType_True" 0 "Bitfield1BitType_False" ;
VAL_ 822 SEMMediaSourceAvail_Source07_ISi 1 "Bitfield1BitType_True" 0 "Bitfield1BitType_False" ;
VAL_ 822 SEMMediaSourceAvail_Source03_ISi 1 "Bitfield1BitType_True" 0 "Bitfield1BitType_False" ;
VAL_ 822 SEMMediaSourceAvail_Source11_ISi 1 "Bitfield1BitType_True" 0 "Bitfield1BitType_False" ;
VAL_ 822 SEMMediaSourceAvail_Source02_ISi 1 "Bitfield1BitType_True" 0 "Bitfield1BitType_False" ;
VAL_ 822 AudioSourceStat_ISig_4 15 "AudioSource_NotAvailable" 14 "AudioSource_Error" 13 "AudioSource_Source13" 12 "AudioSource_Source12" 11 "AudioSource_Source11" 10 "AudioSource_Source10" 9 "AudioSource_Source09" 8 "AudioSource_Source08" 7 "AudioSource_Source07" 6 "AudioSource_Source06" 5 "AudioSource_Source05" 4 "AudioSource_Source04" 3 "AudioSource_Source03" 2 "AudioSource_Source02" 1 "AudioSource_Source01" 0 "AudioSource_Source00" ;
VAL_ 822 SEMMediaSourceAvail_Source06_ISi 1 "Bitfield1BitType_True" 0 "Bitfield1BitType_False" ;
VAL_ 822 SEMMediaSourceAvail_Source00_ISi 1 "Bitfield1BitType_True" 0 "Bitfield1BitType_False" ;
VAL_ 822 SEMMediaSourceAvail_Source01_ISi 1 "Bitfield1BitType_True" 0 "Bitfield1BitType_False" ;
VAL_ 822 SEMMediaSourceAvail_Source08_ISi 1 "Bitfield1BitType_True" 0 "Bitfield1BitType_False" ;
VAL_ 822 SEM_AudioMuteStat_ISig_4 7 "AudioMute_NotAvailable" 6 "AudioMute_ErrorIndication" 5 "AudioMute_Spare_03" 4 "AudioMute_Spare_02" 3 "AudioMute_Spare_01" 2 "AudioMute_Spare" 1 "AudioMute_Mute" 0 "AudioMute_Off" ;
VAL_ 822 SEMMediaSourceAvail_Source13_ISi 1 "Bitfield1BitType_True" 0 "Bitfield1BitType_False" ;
VAL_ 822 SEMMediaSourceAvail_Source05_ISi 1 "Bitfield1BitType_True" 0 "Bitfield1BitType_False" ;
VAL_ 1337 TPMUnmateTrailerReq_ISig_4 3 "Request_NotAvailable" 2 "Request_Error" 1 "Request_RequestActive" 0 "Request_NotRequested" ;
VAL_ 1337 TPMPosOfWMReq_VehiclePos_ISig_4 7 "TPMVehiclePos_NotAvailable" 6 "TPMVehiclePos_Error" 5 "TPMVehiclePos_Trailer5Vehicle" 4 "TPMVehiclePos_Trailer4Vehicle" 3 "TPMVehiclePos_Trailer3Vehicle" 2 "TPMVehiclePos_Trailer2Vehicle" 1 "TPMVehiclePos_Trailer1Vehicle" 0 "TPMVehiclePos_TruckVehicle" ;
VAL_ 1337 TPMMateTrailerReq_ISig_4 3 "Request_NotAvailable" 2 "Request_Error" 1 "Request_RequestActive" 0 "Request_NotRequested" ;
VAL_ 1337 TPMSetAxleRefPres_VehiclePos_ISi 7 "TPMVehiclePos_NotAvailable" 6 "TPMVehiclePos_Error" 5 "TPMVehiclePos_Trailer5Vehicle" 4 "TPMVehiclePos_Trailer4Vehicle" 3 "TPMVehiclePos_Trailer3Vehicle" 2 "TPMVehiclePos_Trailer2Vehicle" 1 "TPMVehiclePos_Trailer1Vehicle" 0 "TPMVehiclePos_TruckVehicle" ;
VAL_ 1336 TPMSetAxleTireConfig_Axle4_ISig_ 7 "TPMAxleConfig_NotAvailable" 6 "TPMAxleConfig_Error" 5 "TPMAxleConfig_Spare" 4 "TPMAxleConfig_RearAxleWith4Tires" 3 "TPMAxleConfig_RearAxleWith2Tires" 2 "TPMAxleConfig_FrontAxleWith4Tires" 1 "TPMAxleConfig_FrontAxleWith2Tires" 0 "TPMAxleConfig_NotPresent" ;
VAL_ 1336 TPMSetAxleTireConfig_Axle5_ISig_ 7 "TPMAxleConfig_NotAvailable" 6 "TPMAxleConfig_Error" 5 "TPMAxleConfig_Spare" 4 "TPMAxleConfig_RearAxleWith4Tires" 3 "TPMAxleConfig_RearAxleWith2Tires" 2 "TPMAxleConfig_FrontAxleWith4Tires" 1 "TPMAxleConfig_FrontAxleWith2Tires" 0 "TPMAxleConfig_NotPresent" ;
VAL_ 1336 TPMSetPresThresCfg_VehiclePos_IS 7 "TPMVehiclePos_NotAvailable" 6 "TPMVehiclePos_Error" 5 "TPMVehiclePos_Trailer5Vehicle" 4 "TPMVehiclePos_Trailer4Vehicle" 3 "TPMVehiclePos_Trailer3Vehicle" 2 "TPMVehiclePos_Trailer2Vehicle" 1 "TPMVehiclePos_Trailer1Vehicle" 0 "TPMVehiclePos_TruckVehicle" ;
VAL_ 1336 TPMSetAxleTireConfig_Axle2_ISig_ 7 "TPMAxleConfig_NotAvailable" 6 "TPMAxleConfig_Error" 5 "TPMAxleConfig_Spare" 4 "TPMAxleConfig_RearAxleWith4Tires" 3 "TPMAxleConfig_RearAxleWith2Tires" 2 "TPMAxleConfig_FrontAxleWith4Tires" 1 "TPMAxleConfig_FrontAxleWith2Tires" 0 "TPMAxleConfig_NotPresent" ;
VAL_ 1336 TPMSetAxleTireConfig_VehiclePos_ 7 "TPMVehiclePos_NotAvailable" 6 "TPMVehiclePos_Error" 5 "TPMVehiclePos_Trailer5Vehicle" 4 "TPMVehiclePos_Trailer4Vehicle" 3 "TPMVehiclePos_Trailer3Vehicle" 2 "TPMVehiclePos_Trailer2Vehicle" 1 "TPMVehiclePos_Trailer1Vehicle" 0 "TPMVehiclePos_TruckVehicle" ;
VAL_ 1336 TPMSetAxleTireConfig_Axle3_ISig_ 7 "TPMAxleConfig_NotAvailable" 6 "TPMAxleConfig_Error" 5 "TPMAxleConfig_Spare" 4 "TPMAxleConfig_RearAxleWith4Tires" 3 "TPMAxleConfig_RearAxleWith2Tires" 2 "TPMAxleConfig_FrontAxleWith4Tires" 1 "TPMAxleConfig_FrontAxleWith2Tires" 0 "TPMAxleConfig_NotPresent" ;
VAL_ 1336 TPMSetAxleTireConfig_Axle1_ISig_ 7 "TPMAxleConfig_NotAvailable" 6 "TPMAxleConfig_Error" 5 "TPMAxleConfig_Spare" 4 "TPMAxleConfig_RearAxleWith4Tires" 3 "TPMAxleConfig_RearAxleWith2Tires" 2 "TPMAxleConfig_FrontAxleWith4Tires" 1 "TPMAxleConfig_FrontAxleWith2Tires" 0 "TPMAxleConfig_NotPresent" ;
VAL_ 1336 TPMSetPresThresCfg_AxleNr_ISig_4 7 "TPMAxleNr_NotAvailable" 6 "TPMAxleNr_Error" 5 "TPMAxleNr_Axle5" 4 "TPMAxleNr_Axle4" 3 "TPMAxleNr_Axle3" 2 "TPMAxleNr_Axle2" 1 "TPMAxleNr_Axle1" 0 "TPMAxleNr_NoRequest" ;
VAL_ 837 TPMIndicationLightReq 3 "Request_NotAvailable" 2 "Request_Error" 1 "Request_RequestActive" 0 "Request_NotRequested" ;
VAL_ 837 Regeneration_DeviceInd 15 "DualDeviceIndication_UpperDontCareLowerDontCare" 14 "DualDeviceIndication_UpperBlinkLowerDontCare" 13 "DualDeviceIndication_UpperOnLowerDontCare" 12 "DualDeviceIndication_UpperOffLowerDontCare" 11 "DualDeviceIndication_UpperDontCareLowerBlink" 10 "DualDeviceIndication_UpperBlinkLowerBlink" 9 "DualDeviceIndication_UpperOnLowerBlink" 8 "DualDeviceIndication_UpperOffLowerBlink" 7 "DualDeviceIndication_UpperDontCareLowerOn" 6 "DualDeviceIndication_UpperBlinkLowerOn" 5 "DualDeviceIndication_UpperOnLowerOn" 4 "DualDeviceIndication_UpperOffLowerOn" 3 "DualDeviceIndication_UpperDontCareLowerOff" 2 "DualDeviceIndication_UpperBlinkLowerOff" 1 "DualDeviceIndication_UpperOnLowerOff" 0 "DualDeviceIndication_UpperOffLowerOff" ;
VAL_ 1056 ExtraHeating_rqst_ISig_4 7 "ActivationRequest_NotAvailable" 6 "ActivationRequest_Error" 5 "ActivationRequest_Spare3" 4 "ActivationRequest_Spare2" 3 "ActivationRequest_Spare1" 2 "ActivationRequest_AutoStart" 1 "ActivationRequest_Off" 0 "ActivationRequest_NoAction" ;
VAL_ 1056 HillDataCtrlTGW_State_ISig_4 7 "HillDataState_NotAvailable" 6 "HillDataState_Error" 5 "HillDataState_Spare_03" 4 "HillDataState_Spare_02" 3 "HillDataState_Spare_01" 2 "HillDataState_Receive" 1 "HillDataState_Request" 0 "HillDataState_Idle" ;
VAL_ 1334 MaintReset_rqst_Request 3 "ResetRequest_NotAvailable" 2 "ResetRequest_Error" 1 "ResetRequest_ResetRequested" 0 "ResetRequest_NoResetRequested" ;
VAL_ 1334 DPF_ManualRegenerateInhibit 3 "InactiveActive_NotAvailable" 2 "InactiveActive_Error" 1 "InactiveActive_Active" 0 "InactiveActive_Inactive" ;
VAL_ 1334 BlackPanel_stat_ISig_4 3 "InactiveActive_NotAvailable" 2 "InactiveActive_Error" 1 "InactiveActive_Active" 0 "InactiveActive_Inactive" ;
VAL_ 1334 DPF_ManualRegenerateRequest 3 "Request_NotAvailable" 2 "Request_Error" 1 "Request_RequestActive" 0 "Request_NotRequested" ;
VAL_ 1377 GPSData_AntennaStat_ISig_4_561 7 "GPS_Antenna_status_NA" 6 "GPS_Antenna_status_ErrorIndicator" 5 "GPS_Antenna_status_SpareValue_01" 4 "GPS_Antenna_status_SpareValue" 3 "GPS_Antenna_status_AntennaStatusUnknown" 2 "GPS_Antenna_status_AntennaInit" 1 "GPS_Antenna_status_AntennaDisconnected" 0 "GPS_Antenna_status_AntennaStatusOK" ;
VAL_ 1375 GPSData_AntennaStat_ISig_4_55f 7 "GPS_Antenna_status_NA" 6 "GPS_Antenna_status_ErrorIndicator" 5 "GPS_Antenna_status_SpareValue_01" 4 "GPS_Antenna_status_SpareValue" 3 "GPS_Antenna_status_AntennaStatusUnknown" 2 "GPS_Antenna_status_AntennaInit" 1 "GPS_Antenna_status_AntennaDisconnected" 0 "GPS_Antenna_status_AntennaStatusOK" ;
VAL_ 1381 GPSData_AntennaStat_ISig_4_565 7 "GPS_Antenna_status_NA" 6 "GPS_Antenna_status_ErrorIndicator" 5 "GPS_Antenna_status_SpareValue_01" 4 "GPS_Antenna_status_SpareValue" 3 "GPS_Antenna_status_AntennaStatusUnknown" 2 "GPS_Antenna_status_AntennaInit" 1 "GPS_Antenna_status_AntennaDisconnected" 0 "GPS_Antenna_status_AntennaStatusOK" ;
VAL_ 1386 GPSData_AntennaStat_ISig_4_56a 7 "GPS_Antenna_status_NA" 6 "GPS_Antenna_status_ErrorIndicator" 5 "GPS_Antenna_status_SpareValue_01" 4 "GPS_Antenna_status_SpareValue" 3 "GPS_Antenna_status_AntennaStatusUnknown" 2 "GPS_Antenna_status_AntennaInit" 1 "GPS_Antenna_status_AntennaDisconnected" 0 "GPS_Antenna_status_AntennaStatusOK" ;
VAL_ 1384 GPSData_AntennaStat_ISig_4_568 7 "GPS_Antenna_status_NA" 6 "GPS_Antenna_status_ErrorIndicator" 5 "GPS_Antenna_status_SpareValue_01" 4 "GPS_Antenna_status_SpareValue" 3 "GPS_Antenna_status_AntennaStatusUnknown" 2 "GPS_Antenna_status_AntennaInit" 1 "GPS_Antenna_status_AntennaDisconnected" 0 "GPS_Antenna_status_AntennaStatusOK" ;
VAL_ 979 DynamicCode_rqst 7 "DynamicCode_rqst_NotAvailable" 6 "DynamicCode_rqst_Error" 1 "DynamicCode_rqst_DynamicCodeRequest" 0 "DynamicCode_rqst_Idle" ;
VAL_ 970 FirstAxleLowerPrioRequested_ISig 7 "FirstAxleLowerPrio_NotAvailable" 6 "FirstAxleLowerPrio_Error" 5 "FirstAxleLowerPrio_Reserved_03" 4 "FirstAxleLowerPrio_Reserved_02" 3 "FirstAxleLowerPrio_Reserved_01" 2 "FirstAxleLowerPrio_Reserved" 1 "FirstAxleLowerPrio_LowerPusher" 0 "FirstAxleLowerPrio_LowerTag" ;
VAL_ 970 Synch_Unsynch_Mode_stat 7 "Synch_Unsynch_Mode_stat_NotAvailable" 6 "Synch_Unsynch_Mode_stat_Error" 5 "Synch_Unsynch_Mode_stat_Spare_02" 4 "Synch_Unsynch_Mode_stat_Spare_01" 3 "Synch_Unsynch_Mode_stat_Spare" 2 "Synch_Unsynch_Mode_stat_UnsynchronizedMode" 1 "Synch_Unsynch_Mode_stat_SynchronizedMode" 0 "Synch_Unsynch_Mode_stat_Idle" ;
VAL_ 970 SelectedSpeedUnit_stat_ISig_4 3 "SpeedUnit_NotAvailable" 2 "SpeedUnit_Error" 1 "SpeedUnit_MilesPerHour" 0 "SpeedUnit_KilometersPerHour" ;
VAL_ 970 SelectedLanguage_stat_ISig_4 63 "Language_NotAvailable" 62 "Language_Error" 61 "Language_Spare_26" 60 "Language_Spare_25" 59 "Language_Spare_24" 58 "Language_Spare_23" 57 "Language_Spare_22" 56 "Language_Spare_21" 55 "Language_Spare_20" 54 "Language_Spare_19" 53 "Language_Spare_18" 52 "Language_Spare_17" 51 "Language_Spare_16" 50 "Language_Spare_15" 49 "Language_Spare_14" 48 "Language_Spare_13" 47 "Language_Spare_12" 46 "Language_Spare_11" 45 "Language_Spare_10" 44 "Language_Spare_09" 43 "Language_Spare_08" 42 "Language_Spare_07" 41 "Language_Spare_06" 40 "Language_Spare_05" 39 "Language_Spare_04" 38 "Language_Malay_Indonesian" 37 "Language_Ukrainian" 36 "Language_Bosnian" 35 "Language_Croatian" 34 "Language_Numeric" 33 "Language_Japanese" 32 "Language_Korean" 31 "Language_Chinese" 30 "Language_Thai" 29 "Language_Arabic" 28 "Language_Farsi" 27 "Language_Hebrew" 26 "Language_Turkish" 25 "Language_Hungarian" 24 "Language_Slovak" 23 "Language_Czech" 22 "Language_Slovenian" 21 "Language_Serbian" 20 "Language_Greek" 19 "Language_Bulgarian" 18 "Language_Italian" 17 "Language_Dutch" 16 "Language_Rumanian" 15 "Language_BrazilianPortugese" 14 "Language_Portugese" 13 "Language_Spanish" 12 "Language_French" 11 "Language_German" 10 "Language_Polish" 9 "Language_Lituanian" 8 "Language_Latvian" 7 "Language_Estonian" 6 "Language_Russian" 5 "Language_Finish" 4 "Language_Icelandic" 3 "Language_Norwegian" 2 "Language_Danish" 1 "Language_Swedish" 0 "Language_English" ;
VAL_ 970 LampCheck_rqst_ISig_4 3 "LampCheck_NotAvailable" 2 "LampCheck_Error" 1 "LampCheck_PerformLampCheck" 0 "LampCheck_NoAction" ;
VAL_ 970 SelectedWeightUnit_stat_ISig_4 3 "WeightUnit_NotAvailable" 2 "WeightUnit_Error" 1 "WeightUnit_Pound" 0 "WeightUnit_Kg" ;
VAL_ 970 SpeedLockingInhibition_stat 7 "SpeedLockingInhibition_stat_NotAvailable" 6 "SpeedLockingInhibition_stat_Error" 2 "SpeedLockingInhibition_stat_SpeedLockingDeactivate" 1 "SpeedLockingInhibition_stat_SpeedLockingActivate" 0 "SpeedLockingInhibition_stat_Idle" ;
VAL_ 970 DriverMemory_rqst_ISig_4 31 "DriverMemory_rqst_Error" 30 "DriverMemory_rqst_NotAvailable" 29 "DriverMemory_rqst_Spare_07" 28 "DriverMemory_rqst_Spare_06" 27 "DriverMemory_rqst_Spare_05" 26 "DriverMemory_rqst_Spare_04" 25 "DriverMemory_rqst_Spare_03" 24 "DriverMemory_rqst_Spare_02" 23 "DriverMemory_rqst_Spare_01" 22 "DriverMemory_rqst_Spare" 21 "DriverMemory_rqst_ResetAllMemThenUseDefDriverMem" 20 "DriverMemory_rqst_ResetAndThenUseDriverMemory10" 19 "DriverMemory_rqst_ResetAndThenUseDriverMemory9" 18 "DriverMemory_rqst_ResetAndThenUseDriverMemory8" 17 "DriverMemory_rqst_ResetAndThenUseDriverMemory7" 16 "DriverMemory_rqst_ResetAndThenUseDriverMemory6" 15 "DriverMemory_rqst_ResetAndThenUseDriverMemory5" 14 "DriverMemory_rqst_ResetAndThenUseDriverMemory4" 13 "DriverMemory_rqst_ResetAndThenUseDriverMemory3" 12 "DriverMemory_rqst_ResetAndThenUseDriverMemory2" 11 "DriverMemory_rqst_ResetAndThenUseDriverMemory1" 10 "DriverMemory_rqst_UseDriverMemory10" 9 "DriverMemory_rqst_UseDriverMemory9" 8 "DriverMemory_rqst_UseDriverMemory8" 7 "DriverMemory_rqst_UseDriverMemory7" 6 "DriverMemory_rqst_UseDriverMemory6" 5 "DriverMemory_rqst_UseDriverMemory5" 4 "DriverMemory_rqst_UseDriverMemory4" 3 "DriverMemory_rqst_UseDriverMemory3" 2 "DriverMemory_rqst_UseDriverMemory2" 1 "DriverMemory_rqst_UseDriverMemory1" 0 "DriverMemory_rqst_UseDefaultDriverMemory" ;
VAL_ 970 SelectedTimeFormat_stat_ISig_4 3 "TimeFormatStat_NotAvailable" 2 "TimeFormatStat_Error" 1 "TimeFormatStat_24h" 0 "TimeFormatStat_AM_PM" ;
VAL_ 970 MaintInfo_rqst 3 "Request_NotAvailable" 2 "Request_Error" 1 "Request_RequestActive" 0 "Request_NotRequested" ;
VAL_ 970 LCSSoundSettingRequest 3 "LCSSoundSettingRequest_NotAvailable" 2 "LCSSoundSettingRequest_Error" 1 "LCSSoundSettingRequest_EnableLCSSound" 0 "LCSSoundSettingRequest_DisableLCSSound" ;
VAL_ 851 BunkBacklightCmd_ISig_4 31 "BacklightCmd_NotAvailable" 30 "BacklightCmd_Error" 16 "BacklightCmd_BacklightLevel16" 15 "BacklightCmd_BacklightLevel15" 14 "BacklightCmd_BacklightLevel14" 13 "BacklightCmd_BacklightLevel13" 12 "BacklightCmd_BacklightLevel12" 11 "BacklightCmd_BacklightLevel11" 10 "BacklightCmd_BacklightLevel10" 9 "BacklightCmd_BacklightLevel9" 8 "BacklightCmd_BacklightLevel8" 7 "BacklightCmd_BacklightLevel7" 6 "BacklightCmd_BacklightLevel6" 5 "BacklightCmd_BacklightLevel5" 4 "BacklightCmd_BacklightLevel4" 3 "BacklightCmd_BacklightLevel3" 2 "BacklightCmd_BacklightLevel2" 1 "BacklightCmd_BacklightLevel1" 0 "BacklightCmd_BacklightOff" ;
VAL_ 739 ASLDriverRequest 15 "ASLDriverRequest_NotAvailable" 14 "ASLDriverRequest_Error" 13 "ASLDriverRequest_Spare_06" 12 "ASLDriverRequest_Spare_05" 11 "ASLDriverRequest_Spare_04" 10 "ASLDriverRequest_Spare_03" 9 "ASLDriverRequest_Spare_02" 8 "ASLDriverRequest_Spare_01" 7 "ASLDriverRequest_Spare" 6 "ASLDriverRequest_SetPresetSpeed" 5 "ASLDriverRequest_Pause" 4 "ASLDriverRequest_Decrease" 3 "ASLDriverRequest_Increase" 2 "ASLDriverRequest_ResumePreviousSpeed" 1 "ASLDriverRequest_SetCurrentSpeed" 0 "ASLDriverRequest_NoRequest" ;
VAL_ 739 ASLEnableRequest 3 "OffOn_NotAvailable" 2 "OffOn_Error" 1 "OffOn_On" 0 "OffOn_Off" ;
VAL_ 739 CCEnableRequest_ISig_4 3 "DisableEnable_NotAvailable" 2 "DisableEnable_Error" 1 "DisableEnable_Enable" 0 "DisableEnable_Disable" ;
VAL_ 739 CCDriverRequest 15 "CCDriverRequest_NotAvailable" 14 "CCDriverRequest_Error" 13 "CCDriverRequest_Spare_06" 12 "CCDriverRequest_Spare_05" 11 "CCDriverRequest_Spare_04" 10 "CCDriverRequest_Spare_03" 9 "CCDriverRequest_Spare_02" 8 "CCDriverRequest_Spare_01" 7 "CCDriverRequest_Spare" 6 "CCDriverRequest_SetPresetSpeed" 5 "CCDriverRequest_Pause" 4 "CCDriverRequest_Decrease" 3 "CCDriverRequest_Increase" 2 "CCDriverRequest_ResumePreviousSpeed" 1 "CCDriverRequest_SetCurrentSpeed" 0 "CCDriverRequest_NoRequest" ;
VAL_ 390 EcoRollEnableRequest_ISig_4 3 "InactiveActive_NotAvailable" 2 "InactiveActive_Error" 1 "InactiveActive_Active" 0 "InactiveActive_Inactive" ;
VAL_ 390 SelectedEcoCruiseLevel_ISig_4 7 "SelectedEcoCruiseLevel_NotAvailable" 6 "SelectedEcoCruiseLevel_Error" 5 "SelectedEcoCruiseLevel_Spare01" 4 "SelectedEcoCruiseLevel_Spare" 3 "SelectedEcoCruiseLevel_Level3" 2 "SelectedEcoCruiseLevel_Level2" 1 "SelectedEcoCruiseLevel_Level1" 0 "SelectedEcoCruiseLevel_Off" ;
VAL_ 514 PS_GearSelectionMode_ISig_4 7 "GearSelectionMode_NotAvailable" 6 "GearSelectionMode_Spare2" 5 "GearSelectionMode_Spare1" 4 "GearSelectionMode_Manual" 3 "GearSelectionMode_Automatic" 2 "GearSelectionMode_Neutral" 1 "GearSelectionMode_Reverse" 0 "GearSelectionMode_FoldAway" ;
VAL_ 514 WaterInFuelDrainRequest 3 "Request_NotAvailable" 2 "Request_Error" 1 "Request_RequestActive" 0 "Request_NotRequested" ;
VAL_ 514 FuncIndIlluminationLevel_ISig_4 7 "FuncIndIlluminationLevel_NotAvailable" 6 "FuncIndIlluminationLevel_Error" 5 "FuncIndIlluminationLevel_Spare" 4 "FuncIndIlluminationLevel_IlluminationLevel4" 3 "FuncIndIlluminationLevel_IlluminationLevel3" 2 "FuncIndIlluminationLevel_IlluminationLevel2" 1 "FuncIndIlluminationLevel_IlluminationLevel1" 0 "FuncIndIlluminationLevel_IlluminationOff" ;
VAL_ 514 ResumeRequestForACC 3 "OffOn_NotAvailable" 2 "OffOn_Error" 1 "OffOn_On" 0 "OffOn_Off" ;
VAL_ 514 SWSpeedControlAdjustMode 15 "SWSpeedControlAdjustMode_NotAvailable" 14 "SWSpeedControlAdjustMode_Error" 13 "SWSpeedControlAdjustMode_Spare_10" 12 "SWSpeedControlAdjustMode_Spare_09" 11 "SWSpeedControlAdjustMode_Spare_08" 10 "SWSpeedControlAdjustMode_Spare_07" 9 "SWSpeedControlAdjustMode_Spare_06" 8 "SWSpeedControlAdjustMode_Spare_05" 7 "SWSpeedControlAdjustMode_Spare_04" 6 "SWSpeedControlAdjustMode_Spare_03" 5 "SWSpeedControlAdjustMode_Spare_02" 4 "SWSpeedControlAdjustMode_Spare_01" 3 "SWSpeedControlAdjustMode_Spare" 2 "SWSpeedControlAdjustMode_AdjustTimeGap" 1 "SWSpeedControlAdjustMode_AdjustOverspeed" 0 "SWSpeedControlAdjustMode_AdjustSpeed" ;
VAL_ 514 ACCTimeGapRqst 7 "ACCTimeGapRqst_Unavailable" 6 "ACCTimeGapRqst_Error" 5 "ACCTimeGapRqst_Spare" 4 "ACCTimeGapRqst_Set5" 3 "ACCTimeGapRqst_Set4" 2 "ACCTimeGapRqst_Set3" 1 "ACCTimeGapRqst_Set2" 0 "ACCTimeGapRqst_Set1" ;
VAL_ 514 SWSpdCtrlButtonsStatus6 15 "SWSpdCtrlButtonsStatus6_NotAvailable" 14 "SWSpdCtrlButtonsStatus6_Error" 13 "SWSpdCtrlButtonsStatus6_Spare04" 12 "SWSpdCtrlButtonsStatus6_Spare03" 11 "SWSpdCtrlButtonsStatus6_Spare02" 10 "SWSpdCtrlButtonsStatus6_Spare01" 9 "SWSpdCtrlButtonsStatus6_TimeGap" 8 "SWSpdCtrlButtonsStatus6_DHC" 7 "SWSpdCtrlButtonsStatus6_EcoSettings" 6 "SWSpdCtrlButtonsStatus6_CC_ACC" 5 "SWSpdCtrlButtonsStatus6_Enter" 4 "SWSpdCtrlButtonsStatus6_Decrease" 3 "SWSpdCtrlButtonsStatus6_Increase" 2 "SWSpdCtrlButtonsStatus6_Resume" 1 "SWSpdCtrlButtonsStatus6_PauseOff" 0 "SWSpdCtrlButtonsStatus6_None" ;
VAL_ 514 ACCEnableRqst 3 "DisableEnable_NotAvailable" 2 "DisableEnable_Error" 1 "DisableEnable_Enable" 0 "DisableEnable_Disable" ;
VAL_ 514 StopAlert_cmd 7 "Telltale_cmd_NotAvailable" 6 "Telltale_cmd_ErrorIndication" 5 "Telltale_cmd_Spare_02" 4 "Telltale_cmd_Spare_01" 3 "Telltale_cmd_Spare" 2 "Telltale_cmd_Flashing" 1 "Telltale_cmd_OnSteady" 0 "Telltale_cmd_Off" ;
VAL_ 514 BacklightCmd_ISig_4 31 "BacklightCmd_NotAvailable" 30 "BacklightCmd_Error" 16 "BacklightCmd_BacklightLevel16" 15 "BacklightCmd_BacklightLevel15" 14 "BacklightCmd_BacklightLevel14" 13 "BacklightCmd_BacklightLevel13" 12 "BacklightCmd_BacklightLevel12" 11 "BacklightCmd_BacklightLevel11" 10 "BacklightCmd_BacklightLevel10" 9 "BacklightCmd_BacklightLevel9" 8 "BacklightCmd_BacklightLevel8" 7 "BacklightCmd_BacklightLevel7" 6 "BacklightCmd_BacklightLevel6" 5 "BacklightCmd_BacklightLevel5" 4 "BacklightCmd_BacklightLevel4" 3 "BacklightCmd_BacklightLevel3" 2 "BacklightCmd_BacklightLevel2" 1 "BacklightCmd_BacklightLevel1" 0 "BacklightCmd_BacklightOff" ;
VAL_ 514 CMTelltale_stat 7 "Telltale_cmd_NotAvailable" 6 "Telltale_cmd_ErrorIndication" 5 "Telltale_cmd_Spare_02" 4 "Telltale_cmd_Spare_01" 3 "Telltale_cmd_Spare" 2 "Telltale_cmd_Flashing" 1 "Telltale_cmd_OnSteady" 0 "Telltale_cmd_Off" ;
VAL_ 1282 EngineFuelMode 3 "FuelMode_NotAvailable" 2 "FuelMode_Error" 1 "FuelMode_RunOnDiesel" 0 "FuelMode_RunOnGas" ;
VAL_ 1282 LNGOperatorInducementReason 7 "LNGOperatorInducementReason_NotAvailable" 6 "LNGOperatorInducementReason_Error" 5 "LNGOperatorInducementReason_Spare2" 4 "LNGOperatorInducementReason_Spare1" 3 "LNGOperatorInducementReason_IncorrectConsumption" 2 "LNGOperatorInducementReason_GasSupplyMalfunction" 1 "LNGOperatorInducementReason_LNGLevelLow" 0 "LNGOperatorInducementReason_OK" ;
VAL_ 1282 DPF_RegenCompleted 7 "RegenCompleted_NotAvailable" 6 "RegenCompleted_Error" 5 "RegenCompleted_Spare3" 4 "RegenCompleted_Spare2" 3 "RegenCompleted_Spare1" 2 "RegenCompleted_Completed" 1 "RegenCompleted_NotCompleted" 0 "RegenCompleted_NoInformation" ;
VAL_ 1374 MIStatus_ISig_4 3 "OffOn_NotAvailable" 2 "OffOn_Error" 1 "OffOn_On" 0 "OffOn_Off" ;
VAL_ 1374 TorqueReductionStatus_OBD 7 "TorqueReductionStatus_OBD_NotAvailable" 6 "TorqueReductionStatus_OBD_Error" 5 "TorqueReductionStatus_OBD_Spare_01" 4 "TorqueReductionStatus_OBD_Spare" 3 "TorqueReductionStatus_OBD_TorqueReductionActive" 2 "TorqueReductionStatus_OBD_TorqueReductionActiveNextStandstill" 1 "TorqueReductionStatus_OBD_Pending" 0 "TorqueReductionStatus_OBD_NotActive" ;
VAL_ 1374 SCROperatorInducementSeverity 7 "SCROperatorInducementSeverity_NotAvailable" 6 "SCROperatorInducementSeverity_Reserved" 5 "SCROperatorInducementSeverity_SevereInducementActive" 4 "SCROperatorInducementSeverity_SevereIndEnabledWaitActCondition" 3 "SCROperatorInducementSeverity_IndLevel3LowLevelInducementActive" 2 "SCROperatorInducementSeverity_IndLevel2IntensiveWarning" 1 "SCROperatorInducementSeverity_IndLevel1InitialWarning" 0 "SCROperatorInducementSeverity_NoInducementActive" ;
VAL_ 1374 SCROperatorInducementReason 7 "SCROperatorInducementReason_NotAvailable" 6 "SCROperatorInducementReason_Error" 5 "SCROperatorInducementReason_Spare" 4 "SCROperatorInducementReason_Tampering" 3 "SCROperatorInducementReason_IncorrectConsumption" 2 "SCROperatorInducementReason_IncorrectQuality" 1 "SCROperatorInducementReason_ReagentLevelLow" 0 "SCROperatorInducementReason_OK" ;
VAL_ 1374 MIDistinctWarning 3 "OffOn_NotAvailable" 2 "OffOn_Error" 1 "OffOn_On" 0 "OffOn_Off" ;
VAL_ 1374 MIStatusExtEMS 3 "MIStatusExt_NotAvailable" 2 "MIStatusExt_Error" 1 "MIStatusExt_Ready" 0 "MIStatusExt_NotReady5Flash" ;
VAL_ 1374 MIDistinctWarningExtEMS_ISig_4 15 "MIDistinctWarningExt_NotAvailable" 14 "MIDistinctWarningExt_Error" 3 "MIDistinctWarningExt_ContinuousMISteady" 2 "MIDistinctWarningExt_ShortMI3Flash" 1 "MIDistinctWarningExt_OnDemandMI2Flash" 0 "MIDistinctWarningExt_Off1Flash" ;
VAL_ 1391 OilPrediction_Quality 7 "OilQuality_NotAvailable" 6 "OilQuality_Error" 5 "OilQuality_NoSelectionMade" 4 "OilQuality_VDS4" 3 "OilQuality_VDS3" 2 "OilQuality_VDS2" 1 "OilQuality_VDSVDS3WithFixedInterval" 0 "OilQuality_NonVDS_VDS4WithFixedInterval" ;
VAL_ 1391 OilPrediction_Status 7 "OilStatus_NotAvailable" 6 "OilStatus_Error" 5 "OilStatus_Spare" 4 "OilStatus_Ok" 3 "OilStatus_ServiceNearDue" 2 "OilStatus_ServiceDue" 1 "OilStatus_ServiceOverDue" 0 "OilStatus_NotActive" ;
SIG_GROUP_ 1443 SaveTrlrName_rqst_sg 1 : SaveTrlrName_rqst_Request SaveTrlrName_rqst_NewName SaveTrlrName_rqst_Position;
SIG_GROUP_ 1214 AdjustTimeOffset_rqst_sg 1 : AdjustTimeOffset_rqst_Hours AdjustTimeOffset_rqst_Minutes;
SIG_GROUP_ 1214 ChangeDate_rqst_sg 1 : ChangeDate_rqst_Day ChangeDate_rqst_Year ChangeDate_rqst_Month;
SIG_GROUP_ 1256 AlmClkSnze_rqst_sg 1 : AlmClkSnze_rqst_ID AlmClkSnze_rqst_Action;
SIG_GROUP_ 1256 AlmClkSetAlarm_rqst_sg 1 : AlmClkSetAlarm_rqst_Stat AlmClkSetAlarm_rqst_Mode AlmClkSetAlarm_rqst_SetHr AlmClkSetAlarm_rqst_ID AlmClkSetAlarm_rqst_SetMin AlmClkSetAlarm_rqst_Type AlmClkSetAlarm_rqst_DaySet;
SIG_GROUP_ 839 UpdParkClimTimerRqst_sg_ISig_4 1 : UpdParkClimTimerRqst_TimerCmd_IS UpdParkClimTimerRqst_TimRqst_ISi;
SIG_GROUP_ 839 CombinationScaleLoad_sg 1 : CombinationScaleLoad_ScaleLoad CombinationScaleLoad_FirstAxleID CombinationScaleLoad_LastAxleID;
SIG_GROUP_ 838 CalDataLoad_rqst_sg 1 : CalDataLoad_rqst_VehicleID CalDataLoad_rqst_AxleID;
SIG_GROUP_ 515 SetParkClimTimerRqst_sg_ISig_4 1 : SetParkClimTimerRqst_Mon_ISig_4 SetParkClimTimerRqst_Tue_ISig_4 SetParkClimTimerRqst_Sat_ISig_4 SetParkClimTimerRqst_Dur_ISig_4 SetParkClimTimerRqst_Type_ISig_4 SetParkClimTimerRqst_Sun_ISig_4 SetParkClimTimerRqst_Wed_ISig_4 SetParkClimTimerRqst_TimerNr_ISi SetParkClimTimerRqst_Min_ISig_4 SetParkClimTimerRqst_Hrs_ISig_4 SetParkClimTimerRqst_Temp_ISig_4 SetParkClimTimerRqst_Thu_ISig_4 SetParkClimTimerRqst_TimerCmd_IS SetParkClimTimerRqst_Fri_ISig_4 SetParkClimTimerRqst_Rec_ISig_4;
SIG_GROUP_ 949 MediaSourcesListRsp_sg_ISig_4 1 : MediaSourcesListRsp_SrcAttrib_IS MediaSourcesListRsp_SInfo_ISig_4 MediaSourcesListRsp_Name_ISig_4 MediaSourcesListRsp_PCI_ISig_4 MediaSourcesListRsp_ItemID_ISig_;
SIG_GROUP_ 822 SEMMediaSourceAvail_sg_ISig_4 1 : SEMMediaSourceAvail_Source04_ISi SEMMediaSourceAvail_Source10_ISi SEMMediaSourceAvail_SInfo_ISig_4 SEMMediaSourceAvail_Source09_ISi SEMMediaSourceAvail_Source12_ISi SEMMediaSourceAvail_Source07_ISi SEMMediaSourceAvail_Source03_ISi SEMMediaSourceAvail_Source11_ISi SEMMediaSourceAvail_Source02_ISi SEMMediaSourceAvail_Source06_ISi SEMMediaSourceAvail_Source00_ISi SEMMediaSourceAvail_Source01_ISi SEMMediaSourceAvail_Source08_ISi SEMMediaSourceAvail_Source13_ISi SEMMediaSourceAvail_Source05_ISi;
SIG_GROUP_ 1337 TPMPosOfWMReq_sg_ISig_4 1 : TPMPosOfWMReq_VehiclePos_ISig_4 TPMPosOfWMReq_TireId_ISig_4;
SIG_GROUP_ 1337 TPMSetAxleRefPres_sg_ISig_4 1 : TPMSetAxleRefPres_Axle4_ISig_4 TPMSetAxleRefPres_Axle1_ISig_4 TPMSetAxleRefPres_Axle2_ISig_4 TPMSetAxleRefPres_Axle3_ISig_4 TPMSetAxleRefPres_Axle5_ISig_4 TPMSetAxleRefPres_VehiclePos_ISi;
SIG_GROUP_ 1336 TPMSetPresThresCfg_sg_ISig_4 1 : TPMSetPresThresCfg_VehiclePos_IS TPMSetPresThresCfg_ExtOverPres_I TPMSetPresThresCfg_AxleNr_ISig_4 TPMSetPresThresCfg_OverPres_ISig TPMSetPresThresCfg_ExtUnderPres_ TPMSetPresThresCfg_UnderPres_ISi;
SIG_GROUP_ 1336 TPMSetAxleTireConfig_sg_ISig_4 1 : TPMSetAxleTireConfig_Axle4_ISig_ TPMSetAxleTireConfig_Axle5_ISig_ TPMSetAxleTireConfig_Axle2_ISig_ TPMSetAxleTireConfig_VehiclePos_ TPMSetAxleTireConfig_Axle3_ISig_ TPMSetAxleTireConfig_Axle1_ISig_;
SIG_GROUP_ 1056 HillDataCtrlTGW_sg_ISig_4 1 : HillDataCtrlTGW_State_ISig_4 HillDataCtrlTGW_AckCnt_ISig_4;
SIG_GROUP_ 1334 MaintReset_rqst_sg 1 : MaintReset_rqst_Selection MaintReset_rqst_Request MaintReset_rqst_ID;
SIG_GROUP_ 1377 GPSData_sg_ISig_4_561 1 : GPSData_Longitude_ISig_4_561 GPSData_Direction_ISig_4_561 GPSData_Latitude_ISig_4_561 GPSData_Altitude_ISig_4_561 GPSData_HDOP_ISig_4_561 GPSData_Time_ISig_4_561 GPSData_VehSpeed_ISig_4_561 GPSData_AntennaStat_ISig_4_561;
SIG_GROUP_ 1375 GPSData_sg_ISig_4_55f 1 : GPSData_HDOP_ISig_4_55f GPSData_VehSpeed_ISig_4_55f GPSData_Direction_ISig_4_55f GPSData_Longitude_ISig_4_55f GPSData_Time_ISig_4_55f GPSData_Latitude_ISig_4_55f GPSData_AntennaStat_ISig_4_55f GPSData_Altitude_ISig_4_55f;
SIG_GROUP_ 1381 GPSData_sg_ISig_4_565 1 : GPSData_HDOP_ISig_4_565 GPSData_VehSpeed_ISig_4_565 GPSData_AntennaStat_ISig_4_565 GPSData_Latitude_ISig_4_565 GPSData_Time_ISig_4_565 GPSData_Direction_ISig_4_565 GPSData_Longitude_ISig_4_565 GPSData_Altitude_ISig_4_565;
SIG_GROUP_ 1386 GPSData_sg_ISig_4_56a 1 : GPSData_HDOP_ISig_4_56a GPSData_Latitude_ISig_4_56a GPSData_Time_ISig_4_56a GPSData_Direction_ISig_4_56a GPSData_AntennaStat_ISig_4_56a GPSData_Longitude_ISig_4_56a GPSData_VehSpeed_ISig_4_56a GPSData_Altitude_ISig_4_56a;
SIG_GROUP_ 1384 GPSData_sg_ISig_4_568 1 : GPSData_Time_ISig_4_568 GPSData_HDOP_ISig_4_568 GPSData_Direction_ISig_4_568 GPSData_Longitude_ISig_4_568 GPSData_VehSpeed_ISig_4_568 GPSData_Altitude_ISig_4_568 GPSData_Latitude_ISig_4_568 GPSData_AntennaStat_ISig_4_568;
SIG_GROUP_ 1391 OilPrediction_sg 1 : OilPrediction_Quality OilPrediction_RemainDist OilPrediction_RemainTime OilPrediction_Status;
